VERSION ""

NS_ :

BS_:

BU_: ABS_BASE ATCM_DMSM GENERIC_GWMWakeup PBM IPMB TCU_TBS FDSM GSM TRCM GWM _delete ABS_ESC HUD IPMA CCM SASM PSCM SCCM HCM ATCM SUMA_RLM ATCM_FFSM PCU SECM VDM TBM OCS GENERIC TCCM TSTR RCM

BO_ 139 CruiseCtrl_Steering_Data: 8 SASM
 SG_ ActvFrontSteMsgTxt_D_Rq : 31|3@0+ (1,0) [0|7] "SED"  GWM
 SG_ ActvFrontSteLck_D_Stat : 17|2@0+ (1,0) [0|3] "SED"  GWM
 SG_ SelDrvMdeAdptSte_D_Stat : 28|2@0+ (1,0) [0|3] "SED"  ABS_BASE,ABS_ESC
 SG_ AslButtnOnOffPress2 : 4|1@0+ (1,0) [0|1] "SED"  SCCM
 SG_ AslButtnOnOffCnclPres2 : 5|1@0+ (1,0) [0|1] "SED"  SCCM
 SG_ CcButtnOnPress2 : 18|1@0+ (1,0) [0|1] "SED"  SCCM
 SG_ CcButtnOnOffPress2 : 19|1@0+ (1,0) [0|1] "SED"  SCCM
 SG_ CcButtnOnOffCnclPress2 : 20|1@0+ (1,0) [0|1] "SED"  SCCM
 SG_ CcButtnOffPress2 : 21|1@0+ (1,0) [0|1] "SED"  SCCM
 SG_ CcAsllButtnResPress2 : 22|1@0+ (1,0) [0|1] "SED"  SCCM
 SG_ CcAslButtnSetPress2 : 23|1@0+ (1,0) [0|1] "SED"  SCCM
 SG_ CcAslButtnSetIncPress2 : 8|1@0+ (1,0) [0|1] "SED"  SCCM
 SG_ CcAslButtnSetDecPress2 : 9|1@0+ (1,0) [0|1] "SED"  SCCM
 SG_ CcAslButtnResIncPress2 : 10|1@0+ (1,0) [0|1] "SED"  SCCM
 SG_ CcAslButtnResDecPress2 : 11|1@0+ (1,0) [0|1] "SED"  SCCM
 SG_ CcAslButtnOnPress2 : 12|1@0+ (1,0) [0|1] "SED"  SCCM
 SG_ CcAslButtnOnOffCncl2 : 13|1@0+ (1,0) [0|1] "SED"  SCCM
 SG_ CcAslButtnOffCnclPres2 : 14|1@0+ (1,0) [0|1] "SED"  SCCM
 SG_ CcAslButtnIndxIncPres2 : 15|1@0+ (1,0) [0|1] "SED"  SCCM
 SG_ CcAslButtnIndxDecPres2 : 0|1@0+ (1,0) [0|1] "SED"  SCCM
 SG_ CcAslButtnDeny_B_Actl2 : 1|1@0+ (1,0) [0|1] "SED"  SCCM
 SG_ CcAslButtnCnclResPres2 : 2|1@0+ (1,0) [0|1] "SED"  SCCM
 SG_ CcAslButtnCnclPress2 : 3|1@0+ (1,0) [0|1] "SED"  SCCM
 SG_ AccButtnGapIncPress2 : 6|1@0+ (1,0) [0|1] "SED"  SCCM
 SG_ AccButtnGapDecPress2 : 7|1@0+ (1,0) [0|1] "SED"  SCCM

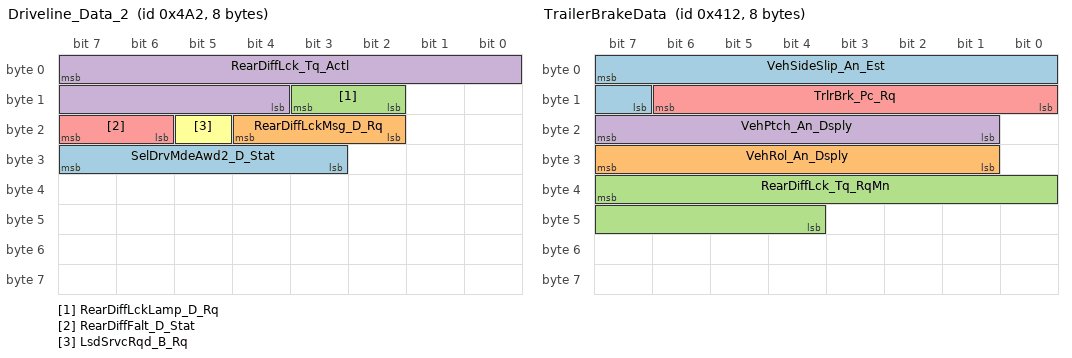
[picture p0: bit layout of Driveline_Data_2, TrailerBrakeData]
BO_ 1186 Driveline_Data_2: 8 TCCM
 SG_ SelDrvMdeAwd2_D_Stat : 31|5@0+ (1,0) [0|31] "SED"  ABS_BASE,ABS_ESC,GWM
 SG_ RearDiffLckMsg_D_Rq : 20|3@0+ (1,0) [0|7] "SED"  GWM
 SG_ RearDiffLckLamp_D_Rq : 11|2@0+ (1,0) [0|3] "SED"  IPMB,ATCM_FFSM,GWM,ATCM_DMSM
 SG_ RearDiffLck_Tq_Actl : 7|12@0+ (1,0) [0|4093] "Nm"  ABS_BASE,ABS_ESC,GWM
 SG_ RearDiffFalt_D_Stat : 23|2@0+ (1,0) [0|3] "SED"  ABS_BASE,ABS_ESC,GWM
 SG_ LsdSrvcRqd_B_Rq : 21|1@0+ (1,0) [0|1] "SED"  GWM

BO_ 1042 TrailerBrakeData: 8 ABS_ESC
 SG_ VehSideSlip_An_Est : 7|9@0+ (0.002,-0.5) [-0.5|0.518] "radians"  TCCM,GWM
 SG_ VehRol_An_Dsply : 31|7@0+ (1,-64) [-64|61] "degrees"  GWM
 SG_ RearDiffLck_Tq_RqMn : 39|12@0+ (4,0) [0|16376] "Nm"  TCCM,GWM
 SG_ VehPtch_An_Dsply : 23|7@0+ (1,-64) [-64|61] "degrees"  GWM
 SG_ TrlrBrk_Pc_Rq : 14|7@0+ (1,0) [0|127] "percent"  TBM,GWM

BO_ 138 ActiveFrontSteering_Stat2: 8 SASM
 SG_ SteWhlRelCalib_T_Actl : 7|8@0+ (1,0) [0|255] "ms"  ABS_BASE,ABS_ESC
 SG_ SteWhlRelCalib_An_Sns : 15|15@0+ (0.1,-1600) [-1600|1676.5] "deg"  PSCM,RCM,TCCM

BO_ 1878 TesterPhysicalReqPBM: 8 TSTR
 SG_ TesterPhysicalReqPBM : 7|64@0+ (1,0) [0|1.84467E+019] "unitless"  PBM

BO_ 1886 TesterPhysicalResPBM: 8 PBM
 SG_ TesterPhysicalResPBM : 7|64@0+ (1,0) [0|1.84467E+019] "unitless"  TSTR

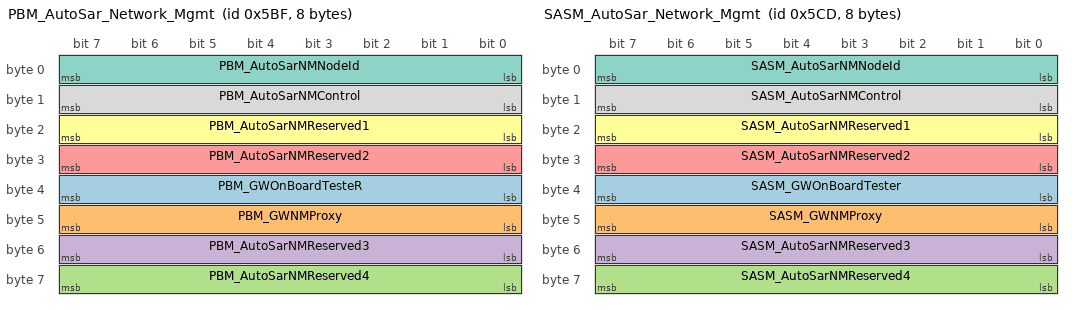
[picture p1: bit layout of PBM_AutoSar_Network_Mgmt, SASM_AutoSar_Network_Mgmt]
BO_ 1471 PBM_AutoSar_Network_Mgmt: 8 PBM
 SG_ PBM_GWOnBoardTesteR : 39|8@0+ (1,0) [0|255] "unitless"  GWM
 SG_ PBM_GWNMProxy : 47|8@0+ (1,0) [0|255] "unitless"  GWM
 SG_ PBM_AutoSarNMReserved4 : 63|8@0+ (1,0) [0|255] "unitless"  GWM
 SG_ PBM_AutoSarNMReserved3 : 55|8@0+ (1,0) [0|255] "unitless"  GWM
 SG_ PBM_AutoSarNMReserved2 : 31|8@0+ (1,0) [0|255] "unitless"  GWM
 SG_ PBM_AutoSarNMReserved1 : 23|8@0+ (1,0) [0|255] "unitless"  GWM
 SG_ PBM_AutoSarNMNodeId : 7|8@0+ (1,0) [0|255] "unitless"  GWM
 SG_ PBM_AutoSarNMControl : 15|8@0+ (1,0) [0|255] "unitless"  GWM

BO_ 1951 TesterPhysicalResSASM: 8 SASM
 SG_ TesterPhysicalResSASM : 7|64@0+ (1,0) [0|1.84467E+019] "unitless"  TSTR

BO_ 1943 TesterPhysicalReqSASM: 8 TSTR
 SG_ TesterPhysicalReqSASM : 7|64@0+ (1,0) [0|1.84467E+019] "unitless"  SASM

BO_ 1485 SASM_AutoSar_Network_Mgmt: 8 SASM
 SG_ SASM_GWOnBoardTester : 39|8@0+ (1,0) [0|255] "unitless"  GWM
 SG_ SASM_GWNMProxy : 47|8@0+ (1,0) [0|255] "unitless"  GWM
 SG_ SASM_AutoSarNMReserved4 : 63|8@0+ (1,0) [0|255] "unitless"  GWM
 SG_ SASM_AutoSarNMReserved3 : 55|8@0+ (1,0) [0|255] "unitless"  GWM
 SG_ SASM_AutoSarNMReserved2 : 31|8@0+ (1,0) [0|255] "unitless"  GWM
 SG_ SASM_AutoSarNMReserved1 : 23|8@0+ (1,0) [0|255] "unitless"  GWM
 SG_ SASM_AutoSarNMNodeId : 7|8@0+ (1,0) [0|255] "unitless"  GWM
 SG_ SASM_AutoSarNMControl : 15|8@0+ (1,0) [0|255] "unitless"  GWM

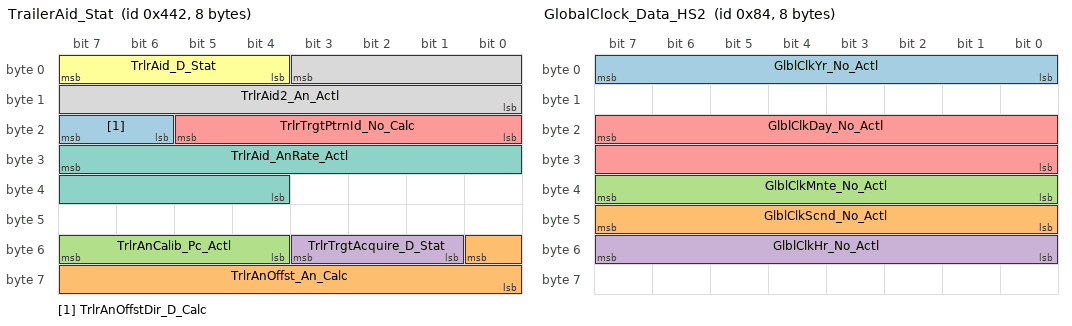
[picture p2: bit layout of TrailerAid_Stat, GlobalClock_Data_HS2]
BO_ 1090 TrailerAid_Stat: 8 IPMB
 SG_ TrlrAnOffstDir_D_Calc : 23|2@0+ (1,0) [0|3] "SED"  PSCM,GWM
 SG_ TrlrAnOffst_An_Calc : 48|9@0+ (0.1,0) [0|51.1] "degrees"  PSCM,GWM
 SG_ TrlrAnCalib_Pc_Actl : 55|4@0+ (10,0) [0|140] "percent"  PSCM,GWM
 SG_ TrlrTrgtAcquire_D_Stat : 51|3@0+ (1,0) [0|7] "SED"  PSCM,GWM
 SG_ TrlrTrgtPtrnId_No_Calc : 21|6@0+ (1,0) [0|63] "unitless"  GWM
 SG_ TrlrAid_D_Stat : 7|4@0+ (1,0) [0|15] "SED"  PSCM
 SG_ TrlrAid_AnRate_Actl : 31|12@0+ (0.1,-50) [-50|359.4] "degrees/sec"  PSCM
 SG_ TrlrAid2_An_Actl : 3|12@0+ (0.1,-90) [-90|319.4] "degrees"  PSCM

BO_ 1977 TesterPhysicalResIPMB: 8 IPMB
 SG_ TesterPhysicalResIPMB : 7|64@0+ (1,0) [0|1.84467E+019] "unitless"  TSTR

BO_ 1969 TesterPhysicalReqIPMB: 8 TSTR
 SG_ TesterPhysicalReqIPMB : 7|64@0+ (1,0) [0|1.84467E+019] "unitless"  IPMB

BO_ 132 GlobalClock_Data_HS2: 8 GWM
 SG_ GlblClkYr_No_Actl : 7|8@0+ (1,2000) [2000|2255] "year"  FDSM,TCU_TBS
 SG_ GlblClkScnd_No_Actl : 47|8@0+ (1,0) [0|255] "second"  FDSM,TCU_TBS
 SG_ GlblClkMnte_No_Actl : 39|8@0+ (1,0) [0|255] "minute"  FDSM,TCU_TBS
 SG_ GlblClkHr_No_Actl : 55|8@0+ (1,0) [0|255] "hour"  FDSM,TCU_TBS
 SG_ GlblClkDay_No_Actl : 23|16@0+ (1,0) [0|65535] "julian day"  FDSM,TCU_TBS

BO_ 73 Global_PATS_SubTarget: 8 ABS_ESC
 SG_ immoSubTarget1Data_T1 : 15|40@0+ (1,0) [0|1099511627775] "Encrypted"  GWM
 SG_ immoSubTarget1Cmd_T1 : 7|3@0+ (1,0) [0|7] "SED"  GWM

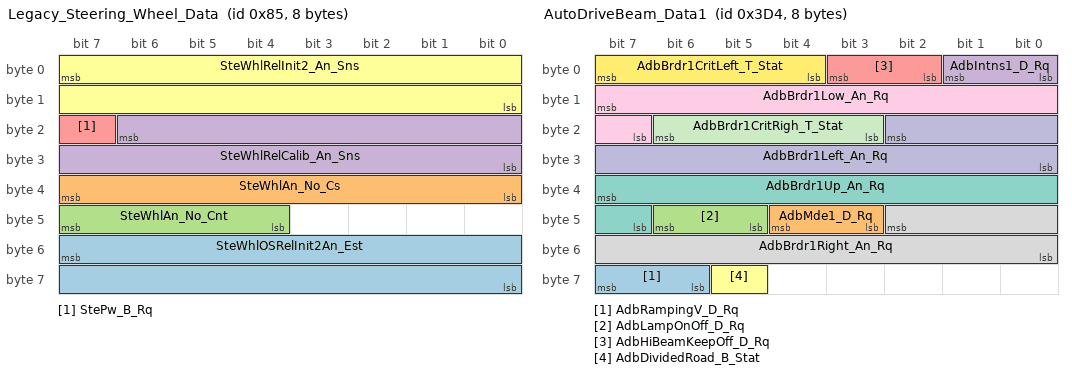
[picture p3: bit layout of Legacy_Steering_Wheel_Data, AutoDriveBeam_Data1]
BO_ 133 Legacy_Steering_Wheel_Data: 8 GENERIC
 SG_ SteWhlOSRelInit2An_Est : 55|16@0+ (0.1,-3200) [-3200|3353.3] "deg"  GENERIC
 SG_ SteWhlAn_No_Cs : 39|8@0+ (1,0) [0|255] "Unitless"  GENERIC
 SG_ SteWhlAn_No_Cnt : 47|4@0+ (1,0) [0|15] "Counts"  GENERIC
 SG_ SteWhlRelCalib_An_Sns : 22|15@0+ (0.1,-1600) [-1600|1676.5] "deg"  GENERIC
 SG_ StePw_B_Rq : 23|1@0+ (1,0) [0|1] "SED"  GENERIC
 SG_ SteWhlRelInit2_An_Sns : 7|16@0+ (0.1,-3200) [-3200|3353.3] "degrees"  IPMA,GENERIC

BO_ 980 AutoDriveBeam_Data1: 8 IPMA
 SG_ AdbRampingV_D_Rq : 63|2@0+ (1,0) [0|3] "SED"  HCM
 SG_ AdbMde1_D_Rq : 44|2@0+ (1,0) [0|3] "SED"  HCM
 SG_ AdbLampOnOff_D_Rq : 46|2@0+ (1,0) [0|3] "SED"  HCM
 SG_ AdbIntns1_D_Rq : 1|2@0+ (1,0) [0|3] "SED"  HCM
 SG_ AdbHiBeamKeepOff_D_Rq : 3|2@0+ (1,0) [0|3] "SED"  HCM
 SG_ AdbDividedRoad_B_Stat : 61|1@0+ (1,0) [0|1] "SED"  HCM
 SG_ AdbBrdr1Up_An_Rq : 39|9@0+ (0.02,-8) [-8|2.18] "degrees"  HCM
 SG_ AdbBrdr1Right_An_Rq : 42|11@0+ (0.02,-20) [-20|20.9] "degrees"  HCM
 SG_ AdbBrdr1Low_An_Rq : 15|9@0+ (0.02,-8) [-8|2.18] "degrees"  HCM
 SG_ AdbBrdr1Left_An_Rq : 18|11@0+ (0.02,-20) [-20|20.9] "degrees"  HCM
 SG_ AdbBrdr1CritRigh_T_Stat : 22|4@0+ (100,0) [0|1500] "millisecond"  HCM
 SG_ AdbBrdr1CritLeft_T_Stat : 7|4@0+ (100,0) [0|1500] "millisecond"  HCM

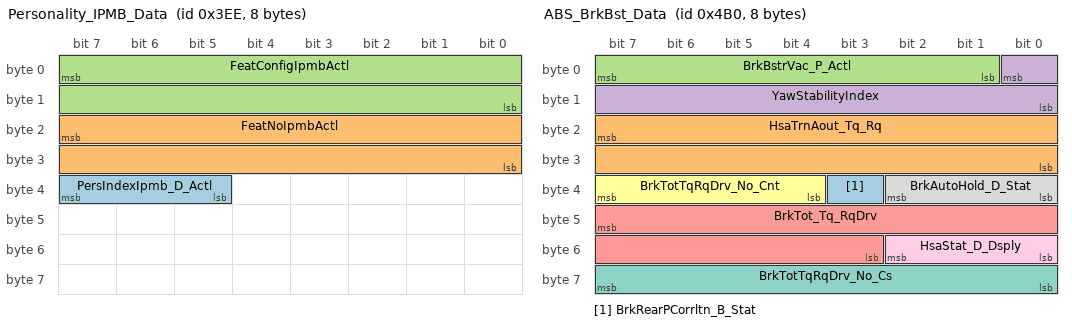
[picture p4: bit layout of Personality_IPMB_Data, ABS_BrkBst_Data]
BO_ 1006 Personality_IPMB_Data: 8 IPMB
 SG_ PersIndexIpmb_D_Actl : 39|3@0+ (1,0) [0|7] "SED"  GWM
 SG_ FeatNoIpmbActl : 23|16@0+ (1,0) [0|65535] "Number"  GWM
 SG_ FeatConfigIpmbActl : 7|16@0+ (1,0) [0|65535] "Undefined"  GWM

BO_ 1200 ABS_BrkBst_Data: 8 ABS_ESC
 SG_ BrkRearPCorrltn_B_Stat : 35|1@0+ (1,0) [0|1] "SED"  PBM,GWM
 SG_ HsaTrnAout_Tq_Rq : 23|16@0+ (4,-131072) [-131072|131060] "Nm"  GWM
 SG_ BrkBstrVac_P_Actl : 7|7@0+ (8,0) [0|1008] "Millibar"  GWM
 SG_ YawStabilityIndex : 0|9@0+ (1,-256) [-256|255] "%"  IPMA,SASM,GWM,PSCM,VDM
 SG_ BrkTot_Tq_RqDrv : 47|13@0+ (4,0) [0|32760] "Nm"  PBM,IPMA,CCM,GWM
 SG_ BrkTotTqRqDrv_No_Cnt : 39|4@0+ (1,0) [0|15] "unitless"  PBM,GWM
 SG_ BrkTotTqRqDrv_No_Cs : 63|8@0+ (1,0) [0|255] "unitless"  PBM,GWM
 SG_ BrkAutoHold_D_Stat : 34|3@0+ (1,0) [0|7] "SED"  GWM
 SG_ HsaStat_D_Dsply : 50|3@0+ (1,0) [0|7] "SED"  GWM

BO_ 989 Personality_HCM_HS2_Data: 8 HCM
 SG_ FeatNoHcm_No_Actl : 23|16@0+ (1,0) [0|65535] "Number"  GWM
 SG_ FeatConfigHcmActl : 7|16@0+ (1,0) [0|65535] "Undefined"  GWM

BO_ 1852 TesterPhysicalResHCM_HS2: 8 HCM
 SG_ TesterPhysicalResHCM : 7|64@0+ (1,0) [0|1.84467E+019] "unitless"  TSTR

BO_ 1844 TesterPhysicalReqHCM_HS2: 8 TSTR
 SG_ TesterPhysicalReqHCM : 7|64@0+ (1,0) [0|1.84467E+019] "unitless"  HCM

BO_ 945 Body_Info_7_HS2: 8 GWM
 SG_ KeyOffMde_D_Actl : 7|4@0+ (1,0) [0|15] "SED"  VDM

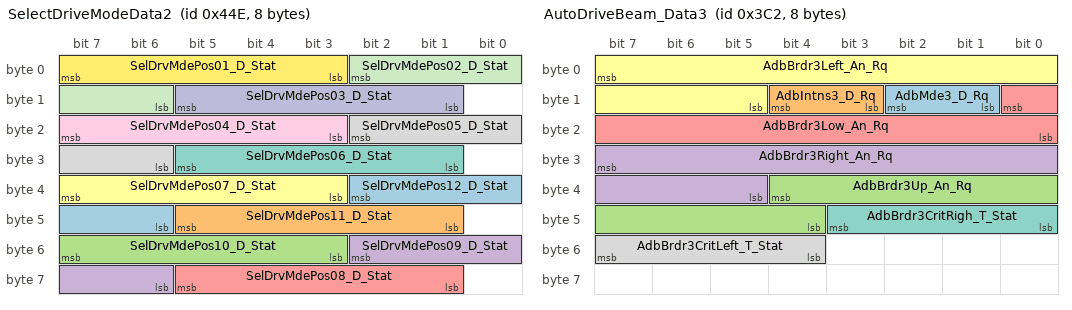
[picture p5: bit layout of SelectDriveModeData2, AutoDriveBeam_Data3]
BO_ 1102 SelectDriveModeData2: 8 ABS_ESC
 SG_ SelDrvMdePos12_D_Stat : 34|5@0+ (1,0) [0|31] "SED"  GWM
 SG_ SelDrvMdePos11_D_Stat : 45|5@0+ (1,0) [0|31] "SED"  GWM
 SG_ SelDrvMdePos10_D_Stat : 55|5@0+ (1,0) [0|31] "SED"  GWM
 SG_ SelDrvMdePos09_D_Stat : 50|5@0+ (1,0) [0|31] "SED"  GWM
 SG_ SelDrvMdePos08_D_Stat : 61|5@0+ (1,0) [0|31] "SED"  GWM
 SG_ SelDrvMdePos07_D_Stat : 39|5@0+ (1,0) [0|31] "SED"  GWM
 SG_ SelDrvMdePos06_D_Stat : 29|5@0+ (1,0) [0|31] "SED"  GWM
 SG_ SelDrvMdePos05_D_Stat : 18|5@0+ (1,0) [0|31] "SED"  GWM
 SG_ SelDrvMdePos04_D_Stat : 23|5@0+ (1,0) [0|31] "SED"  GWM
 SG_ SelDrvMdePos03_D_Stat : 13|5@0+ (1,0) [0|31] "SED"  GWM
 SG_ SelDrvMdePos02_D_Stat : 2|5@0+ (1,0) [0|31] "SED"  GWM
 SG_ SelDrvMdePos01_D_Stat : 7|5@0+ (1,0) [0|31] "SED"  GWM

BO_ 962 AutoDriveBeam_Data3: 8 IPMA
 SG_ AdbMde3_D_Rq : 10|2@0+ (1,0) [0|3] "SED"  HCM
 SG_ AdbIntns3_D_Rq : 12|2@0+ (1,0) [0|3] "SED"  HCM
 SG_ AdbBrdr3Up_An_Rq : 36|9@0+ (0.02,-8) [-8|2.18] "degrees"  HCM
 SG_ AdbBrdr3Right_An_Rq : 31|11@0+ (0.02,-20) [-20|20.9] "degrees"  HCM
 SG_ AdbBrdr3Low_An_Rq : 8|9@0+ (0.02,-8) [-8|2.18] "degrees"  HCM
 SG_ AdbBrdr3Left_An_Rq : 7|11@0+ (0.02,-20) [-20|20.9] "degrees"  HCM
 SG_ AdbBrdr3CritRigh_T_Stat : 43|4@0+ (100,0) [0|1500] "millisecond"  HCM
 SG_ AdbBrdr3CritLeft_T_Stat : 55|4@0+ (100,0) [0|1500] "millisecond"  HCM

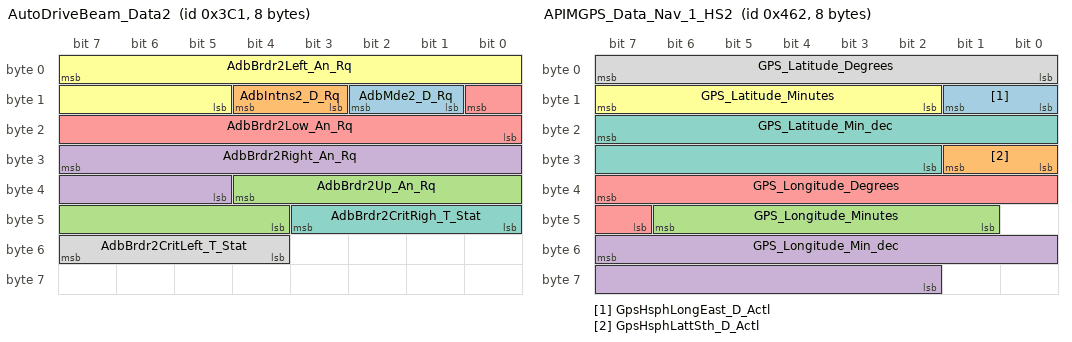
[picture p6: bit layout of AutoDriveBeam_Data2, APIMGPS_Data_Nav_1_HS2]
BO_ 961 AutoDriveBeam_Data2: 8 IPMA
 SG_ AdbMde2_D_Rq : 10|2@0+ (1,0) [0|3] "SED"  HCM
 SG_ AdbIntns2_D_Rq : 12|2@0+ (1,0) [0|3] "SED"  HCM
 SG_ AdbBrdr2Up_An_Rq : 36|9@0+ (0.02,-8) [-8|2.18] "degrees"  HCM
 SG_ AdbBrdr2Right_An_Rq : 31|11@0+ (0.02,-20) [-20|20.9] "degrees"  HCM
 SG_ AdbBrdr2Low_An_Rq : 8|9@0+ (0.02,-8) [-8|2.18] "degrees"  HCM
 SG_ AdbBrdr2Left_An_Rq : 7|11@0+ (0.02,-20) [-20|20.9] "degrees"  HCM
 SG_ AdbBrdr2CritRigh_T_Stat : 43|4@0+ (100,0) [0|1500] "millisecond"  HCM
 SG_ AdbBrdr2CritLeft_T_Stat : 55|4@0+ (100,0) [0|1500] "millisecond"  HCM

BO_ 1122 APIMGPS_Data_Nav_1_HS2: 8 GWM
 SG_ GpsHsphLongEast_D_Actl : 9|2@0+ (1,0) [0|3] "SED"  GENERIC
 SG_ GpsHsphLattSth_D_Actl : 25|2@0+ (1,0) [0|3] "SED"  GENERIC
 SG_ GPS_Longitude_Minutes : 46|6@0+ (1,0) [0|61] "Minutes"  IPMA
 SG_ GPS_Longitude_Min_dec : 55|14@0+ (0.0001,0) [0|1.6381] "Minutes"  IPMA
 SG_ GPS_Longitude_Degrees : 39|9@0+ (1,-179) [-179|330] "Degrees"  IPMA
 SG_ GPS_Latitude_Minutes : 15|6@0+ (1,0) [0|61] "Minutes"  IPMA
 SG_ GPS_Latitude_Min_dec : 23|14@0+ (0.0001,0) [0|1.6381] "Minutes"  IPMA
 SG_ GPS_Latitude_Degrees : 7|8@0+ (1,-89) [-89|164] "Degrees"  IPMA

BO_ 1080 GatewayData3_HS2: 8 GWM
 SG_ AutoTowActv_B_Stat_UB : 50|1@0+ (1,0) [0|1] "SED"  IPMA
 SG_ AutoTowActv_B_Stat : 51|1@0+ (1,0) [0|1] "SED"  IPMA
 SG_ DrLatchLckRr_B_Stat_UB : 44|1@0+ (1,0) [0|1] "SED"  GSM
 SG_ DrLatchLckRl_B_Stat_UB : 46|1@0+ (1,0) [0|1] "SED"  GSM
 SG_ DrLatchLckFr_B_Stat_UB : 32|1@0+ (1,0) [0|1] "SED"  GSM
 SG_ DrLatchLckFl_B_Stat_UB : 34|1@0+ (1,0) [0|1] "SED"  GSM
 SG_ DrLatchRr_B_Falt_UB : 40|1@0+ (1,0) [0|1] "SED"  GSM
 SG_ DrLatchRl_B_Falt_UB : 42|1@0+ (1,0) [0|1] "SED"  GSM
 SG_ DrLatchFr_B_Falt_UB : 36|1@0+ (1,0) [0|1] "SED"  GSM
 SG_ DrLatchFl_B_Falt_UB : 38|1@0+ (1,0) [0|1] "SED"  GSM
 SG_ DrLatchCntRr_No_Actl_UB : 24|1@0+ (1,0) [0|1] "SED"  GSM
 SG_ DrLatchCntRl_No_Actl_UB : 25|1@0+ (1,0) [0|1] "SED"  GSM
 SG_ DrLatchCntFr_No_Actl_UB : 26|1@0+ (1,0) [0|1] "SED"  GSM
 SG_ DrLatchCntFl_No_Actl_UB : 27|1@0+ (1,0) [0|1] "SED"  GSM
 SG_ DrLatchRr_B_Falt : 41|1@0+ (1,0) [0|1] "SED"  GSM
 SG_ DrLatchRl_B_Falt : 43|1@0+ (1,0) [0|1] "SED"  GSM
 SG_ DrLatchLckRr_B_Stat : 45|1@0+ (1,0) [0|1] "SED"  GSM
 SG_ DrLatchLckRl_B_Stat : 47|1@0+ (1,0) [0|1] "SED"  GSM
 SG_ DrLatchLckFr_B_Stat : 33|1@0+ (1,0) [0|1] "SED"  GSM
 SG_ DrLatchLckFl_B_Stat : 35|1@0+ (1,0) [0|1] "SED"  GSM
 SG_ DrLatchFr_B_Falt : 37|1@0+ (1,0) [0|1] "SED"  GSM
 SG_ DrLatchFl_B_Falt : 39|1@0+ (1,0) [0|1] "SED"  GSM
 SG_ DrLatchCntRr_No_Actl : 31|4@0+ (1,0) [0|15] "unitless"  GSM
 SG_ DrLatchCntRl_No_Actl : 19|4@0+ (1,0) [0|15] "unitless"  GSM
 SG_ DrLatchCntFr_No_Actl : 23|4@0+ (1,0) [0|15] "unitless"  GSM
 SG_ DrLatchCntFl_No_Actl : 55|4@0+ (1,0) [0|15] "unitless"  GSM
 SG_ TurnLghtSwtch_D_Stat2_UB : 1|1@0+ (1,0) [0|1] "SED"  PSCM
 SG_ TurnLghtSwtch_D_Stat2 : 3|2@0+ (1,0) [0|3] "SED"  PSCM
 SG_ CabnAmb_Te_Actl_UB : 4|1@0+ (1,0) [0|1] "SED"  SCCM
 SG_ CabnAmb_Te_Actl : 15|8@0+ (0.5,-57) [-57|70] "degreesC"  SCCM
 SG_ HeadLghtHiPrmsn_D_Stat_UB : 5|1@0+ (1,0) [0|1] "SED"  HCM,IPMA,SCCM
 SG_ HeadLghtHiPrmsn_D_Stat : 7|2@0+ (1,0) [0|3] "SED"  HCM,IPMA,SCCM

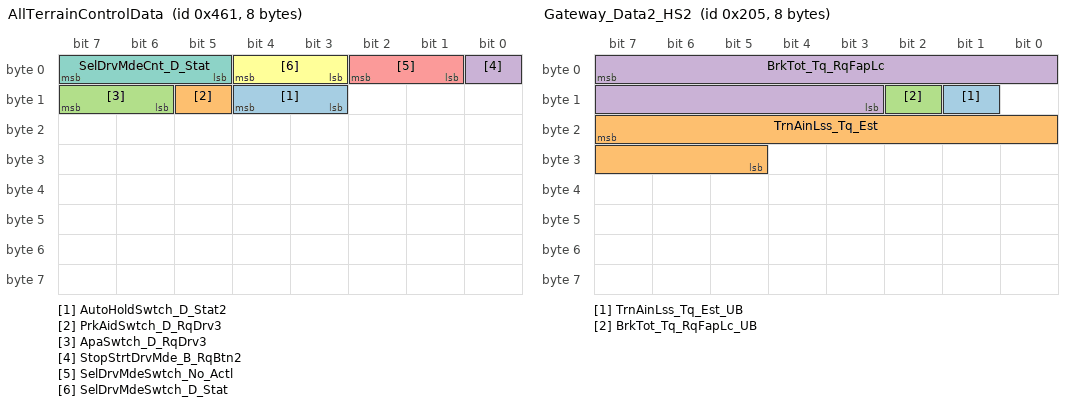
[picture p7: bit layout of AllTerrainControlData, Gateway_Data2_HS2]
BO_ 1121 AllTerrainControlData: 8 ATCM_DMSM
 SG_ AutoHoldSwtch_D_Stat2 : 12|2@0+ (1,0) [0|3] "SED"  ABS_ESC,ABS_BASE
 SG_ PrkAidSwtch_D_RqDrv3 : 13|1@0+ (1,0) [0|1] "SED"  GWM
 SG_ ApaSwtch_D_RqDrv3 : 15|2@0+ (1,0) [0|3] "SED"  GWM
 SG_ StopStrtDrvMde_B_RqBtn2 : 0|1@0+ (1,0) [0|1] "SED"  GWM
 SG_ SelDrvMdeSwtch_No_Actl : 2|2@0+ (1,0) [0|3] "unitless"  ABS_BASE,ABS_ESC
 SG_ SelDrvMdeSwtch_D_Stat : 4|2@0+ (1,0) [0|3] "SED"  ABS_BASE,ABS_ESC
 SG_ SelDrvMdeCnt_D_Stat : 7|3@0+ (1,0) [0|7] "Counts"  ABS_BASE,ABS_ESC

BO_ 517 Gateway_Data2_HS2: 8 GWM
 SG_ TrnAinLss_Tq_Est_UB : 9|1@0+ (1,0) [0|1] "SED"  ABS_ESC,ABS_BASE
 SG_ TrnAinLss_Tq_Est : 23|11@0+ (1,-500) [-500|1545] "Nm"  ABS_ESC,ABS_BASE
 SG_ BrkTot_Tq_RqFapLc_UB : 10|1@0+ (1,0) [0|1] "SED"  ABS_BASE,ABS_ESC
 SG_ BrkTot_Tq_RqFapLc : 7|13@0+ (4,0) [0|32764] "Nm"  ABS_BASE,ABS_ESC

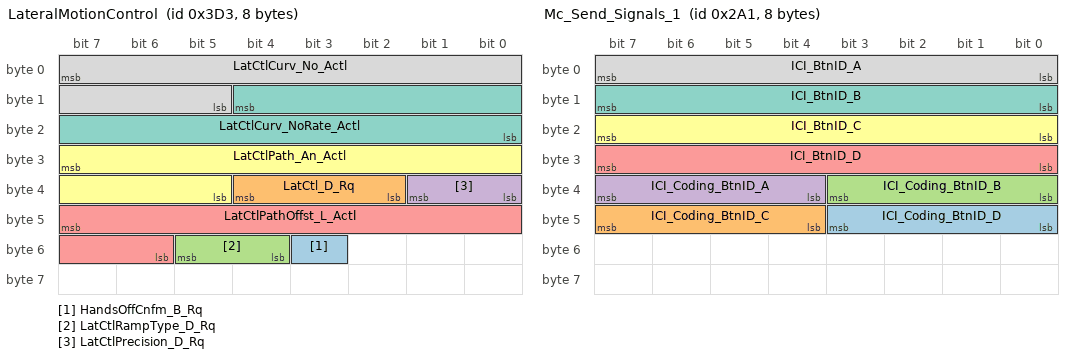
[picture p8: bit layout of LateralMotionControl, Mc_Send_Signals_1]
BO_ 979 LateralMotionControl: 8 IPMA
 SG_ HandsOffCnfm_B_Rq : 51|1@0+ (1,0) [0|1] "SED"  PSCM
 SG_ LatCtl_D_Rq : 36|3@0+ (1,0) [0|7] "SED"  PSCM
 SG_ LatCtlRampType_D_Rq : 53|2@0+ (1,0) [0|3] "SED"  PSCM
 SG_ LatCtlPrecision_D_Rq : 33|2@0+ (1,0) [0|3] "SED"  PSCM
 SG_ LatCtlPathOffst_L_Actl : 47|10@0+ (0.01,-5.12) [-5.12|5.11] "meter"  PSCM
 SG_ LatCtlPath_An_Actl : 31|11@0+ (0.0005,-0.5) [-0.5|0.5235] "radians"  PSCM
 SG_ LatCtlCurv_NoRate_Actl : 12|13@0+ (2.5E-007,-0.001024) [-0.001024|0.00102375] "1/meter"  PSCM
 SG_ LatCtlCurv_No_Actl : 7|11@0+ (2E-005,-0.02) [-0.02|0.02094] "1/meter"  PSCM

BO_ 1056 SelectDriveModeData: 8 ABS_ESC
 SG_ SelDrvMdePos12_B_Avail : 54|1@0+ (1,0) [0|1] "SED"  GWM
 SG_ SelDrvMdePos11_B_Avail : 55|1@0+ (1,0) [0|1] "SED"  GWM
 SG_ SelDrvMdePos10_B_Avail : 40|1@0+ (1,0) [0|1] "SED"  GWM
 SG_ SelDrvMdePos09_B_Avail : 41|1@0+ (1,0) [0|1] "SED"  GWM
 SG_ SelDrvMdePos08_B_Avail : 42|1@0+ (1,0) [0|1] "SED"  GWM
 SG_ SelDrvMdePos07_B_Avail : 43|1@0+ (1,0) [0|1] "SED"  GWM
 SG_ SelDrvMdePos06_B_Avail : 44|1@0+ (1,0) [0|1] "SED"  GWM
 SG_ SelDrvMdePos05_B_Avail : 45|1@0+ (1,0) [0|1] "SED"  GWM
 SG_ SelDrvMdePos04_B_Avail : 46|1@0+ (1,0) [0|1] "SED"  GWM
 SG_ SelDrvMdePos03_B_Avail : 47|1@0+ (1,0) [0|1] "SED"  GWM
 SG_ SelDrvMdePos02_B_Avail : 32|1@0+ (1,0) [0|1] "SED"  GWM
 SG_ SelDrvMdePos01_B_Avail : 24|1@0+ (1,0) [0|1] "SED"  GWM
 SG_ ActvDrvMde_D2_Stat : 53|5@0+ (1,0) [0|31] "SED"  IPMA,GWM
 SG_ SelDrvMde_D2_Rq : 63|5@0+ (1,0) [0|31] "SED"  GWM
 SG_ ActvDrvMde_D_Stat : 39|4@0+ (1,0) [0|15] "SED"  ATCM_DMSM,GWM
 SG_ SelDrvMdePt_D_Rq : 31|5@0+ (1,0) [0|31] "SED"  TCCM,GWM
 SG_ SelDrvMdeMsgTxt_D_Rq : 19|4@0+ (1,0) [0|0] "SED"  GWM
 SG_ SelDrvMde_D_Stat : 26|2@0+ (1,0) [0|3] "SED"  GWM
 SG_ SelDrvMde_D_Rq : 23|4@0+ (1,0) [0|15] "SED"  ATCM_DMSM,GWM
 SG_ SelDrvMde16_B_Avail : 8|1@0+ (1,0) [0|1] "SED"  GWM
 SG_ SelDrvMde15_B_Avail : 9|1@0+ (1,0) [0|1] "SED"  GWM
 SG_ SelDrvMde14_B_Avail : 10|1@0+ (1,0) [0|1] "SED"  GWM
 SG_ SelDrvMde13_B_Avail : 11|1@0+ (1,0) [0|1] "SED"  GWM
 SG_ SelDrvMde12_B_Avail : 12|1@0+ (1,0) [0|1] "SED"  GWM
 SG_ SelDrvMde11_B_Avail : 13|1@0+ (1,0) [0|1] "SED"  GWM
 SG_ SelDrvMde10_B_Avail : 14|1@0+ (1,0) [0|1] "SED"  GWM
 SG_ SelDrvMde09_B_Avail : 15|1@0+ (1,0) [0|1] "SED"  GWM
 SG_ SelDrvMde08_B_Avail : 0|1@0+ (1,0) [0|1] "SED"  GWM
 SG_ SelDrvMde07_B_Avail : 1|1@0+ (1,0) [0|1] "SED"  GWM
 SG_ SelDrvMde06_B_Avail : 2|1@0+ (1,0) [0|1] "SED"  GWM
 SG_ SelDrvMde05_B_Avail : 3|1@0+ (1,0) [0|1] "SED"  GWM
 SG_ SelDrvMde04_B_Avail : 4|1@0+ (1,0) [0|1] "SED"  GWM
 SG_ SelDrvMde03_B_Avail : 5|1@0+ (1,0) [0|1] "SED"  GWM
 SG_ SelDrvMde02_B_Avail : 6|1@0+ (1,0) [0|1] "SED"  GWM
 SG_ SelDrvMde01_B_Avail : 7|1@0+ (1,0) [0|1] "SED"  GWM
 SG_ AwdMde_D_RqBrk : 35|3@0+ (1,0) [0|7] "SED"  GWM,TCCM

BO_ 1215 ElecHorizon_Data2_HS2: 8 GWM
 SG_ EhData2_No_Actl : 7|64@0+ (1,0) [0|1.844674407371E+019] "unitless"  IPMA

BO_ 1214 ElecHorizon_Data1_HS2: 8 GWM
 SG_ EhData1_No_Actl : 7|64@0+ (1,0) [0|1.844674407371E+019] "unitless"  IPMA

BO_ 673 Mc_Send_Signals_1: 8 SCCM
 SG_ ICI_Coding_BtnID_D : 43|4@0+ (1,0) [0|15] "SED"  GWM
 SG_ ICI_Coding_BtnID_C : 47|4@0+ (1,0) [0|15] "SED"  GWM
 SG_ ICI_Coding_BtnID_B : 35|4@0+ (1,0) [0|15] "SED"  GWM
 SG_ ICI_Coding_BtnID_A : 39|4@0+ (1,0) [0|15] "SED"  GWM
 SG_ ICI_BtnID_D : 31|8@0+ (1,0) [0|255] "unitless"  GWM
 SG_ ICI_BtnID_C : 23|8@0+ (1,0) [0|255] "unitless"  GWM
 SG_ ICI_BtnID_B : 15|8@0+ (1,0) [0|255] "unitless"  GWM
 SG_ ICI_BtnID_A : 7|8@0+ (1,0) [0|255] "unitless"  GWM

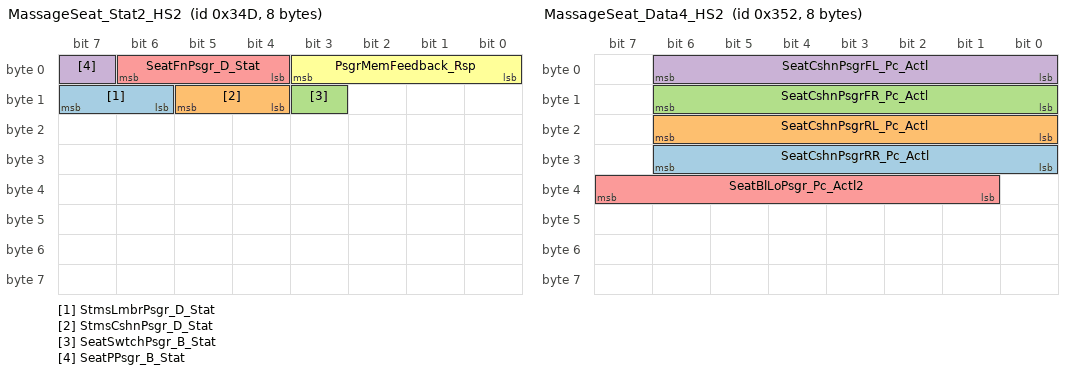
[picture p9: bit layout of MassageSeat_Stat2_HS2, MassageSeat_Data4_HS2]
BO_ 845 MassageSeat_Stat2_HS2: 8 GWM
 SG_ StmsLmbrPsgr_D_Stat : 15|2@0+ (1,0) [0|3] "SED"  OCS
 SG_ StmsCshnPsgr_D_Stat : 13|2@0+ (1,0) [0|3] "SED"  OCS
 SG_ SeatSwtchPsgr_B_Stat : 11|1@0+ (1,0) [0|1] "SED"  OCS
 SG_ SeatPPsgr_B_Stat : 7|1@0+ (1,0) [0|1] "SED"  OCS
 SG_ SeatFnPsgr_D_Stat : 6|3@0+ (1,0) [0|7] "SED"  OCS
 SG_ PsgrMemFeedback_Rsp : 3|4@0+ (1,0) [0|15] "SED"  GENERIC

BO_ 850 MassageSeat_Data4_HS2: 8 GWM
 SG_ SeatCshnPsgrRR_Pc_Actl : 30|7@0+ (1,0) [0|126] "Percent"  OCS
 SG_ SeatCshnPsgrRL_Pc_Actl : 22|7@0+ (1,0) [0|126] "Percent"  OCS
 SG_ SeatCshnPsgrFR_Pc_Actl : 14|7@0+ (1,0) [0|126] "Percent"  OCS
 SG_ SeatCshnPsgrFL_Pc_Actl : 6|7@0+ (1,0) [0|126] "Percent"  OCS
 SG_ SeatBlLoPsgr_Pc_Actl2 : 39|7@0+ (1,0) [0|126] "Percent"  OCS

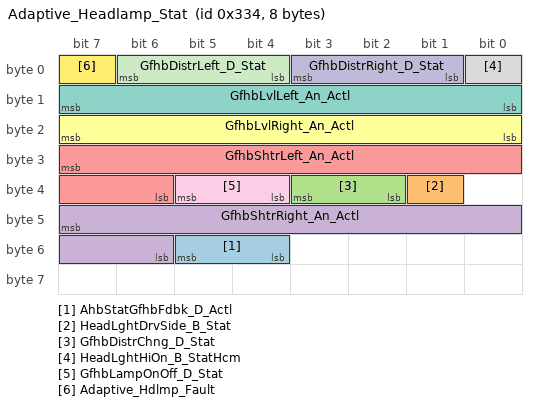
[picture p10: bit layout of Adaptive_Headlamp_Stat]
BO_ 820 Adaptive_Headlamp_Stat: 8 HCM
 SG_ AhbStatGfhbFdbk_D_Actl : 53|2@0+ (1,0) [0|3] "SED"  SCCM
 SG_ HeadLghtDrvSide_B_Stat : 33|1@0+ (1,0) [0|1] "SED"  IPMA
 SG_ GfhbDistrChng_D_Stat : 35|2@0+ (1,0) [0|3] "SED"  IPMA
 SG_ GfhbShtrRight_An_Actl : 47|10@0+ (0.04,-20) [-20|20.84] "degrees"  IPMA
 SG_ GfhbShtrLeft_An_Actl : 31|10@0+ (0.04,-20) [-20|20.84] "degrees"  IPMA
 SG_ GfhbLvlRight_An_Actl : 23|8@0+ (0.1,-12) [-12|13.3] "degrees"  IPMA
 SG_ GfhbLvlLeft_An_Actl : 15|8@0+ (0.1,-12) [-12|13.3] "degrees"  IPMA
 SG_ HeadLghtHiOn_B_StatHcm : 0|1@0+ (1,0) [0|1] "SED"  GWM,GENERIC
 SG_ GfhbLampOnOff_D_Stat : 37|2@0+ (1,0) [0|3] "SED"  IPMA
 SG_ GfhbDistrRight_D_Stat : 3|3@0+ (1,0) [0|7] "SED"  IPMA
 SG_ GfhbDistrLeft_D_Stat : 6|3@0+ (1,0) [0|7] "SED"  IPMA
 SG_ Adaptive_Hdlmp_Fault : 7|1@0+ (1,0) [0|1] "SED"  GWM,IPMA,GENERIC

BO_ 935 Side_Detect_R_Stat_HS2: 8 GWM
 SG_ CtaAlrtRight2_D_Stat : 30|3@0+ (1,0) [0|7] "SED"  GENERIC
 SG_ BttRight_D_Stat : 45|3@0+ (1,0) [0|7] "SED"  GENERIC
 SG_ BttRight_D_RqDrv : 47|2@0+ (1,0) [0|3] "SED"  GENERIC
 SG_ CtaBrkRightMsgTxt_B_Rq : 42|1@0+ (1,0) [0|1] "SED"  GENERIC
 SG_ CtaRightBrkEnbl_B_Rq : 31|1@0+ (1,0) [0|1] "SED"  ABS_BASE,ABS_ESC
 SG_ Side_Detect_R_Illum : 39|8@0+ (1,0) [0|255] "Percent"  GENERIC
 SG_ CtaSnsRight_D_Stat : 25|2@0+ (1,0) [0|3] "SED"  GENERIC
 SG_ CtaAlrtRight_D_Stat : 8|1@0+ (1,0) [0|1] "SED"  GENERIC
 SG_ CtaRight_D_Stat : 18|3@0+ (1,0) [0|7] "SED"  GENERIC
 SG_ SodRight_D_Stat : 15|3@0+ (1,0) [0|7] "SED"  GENERIC
 SG_ SodSnsRight_D_Stat : 12|2@0+ (1,0) [0|3] "SED"  GENERIC
 SG_ SodAlrtRight_D_Stat : 10|2@0+ (1,0) [0|3] "SED"  GENERIC
 SG_ SodDetctRight_D_Stat : 23|3@0+ (1,0) [0|7] "SED"  IPMA
 SG_ SodWarnRight_Prd_Rq : 6|7@0+ (1,0) [0|127] "millisecond"  GENERIC
 SG_ SodInnrRight_D_Stat : 20|2@0+ (1,0) [0|3] "SED"  GENERIC
 SG_ CtaRightBrkDecel_B_Rq : 7|1@0+ (1,0) [0|1] "SED"  ABS_BASE,ABS_ESC
 SG_ CtaInnrRight_D_Stat : 27|2@0+ (1,0) [0|3] "SED"  GENERIC

BO_ 934 Side_Detect_L_Stat_HS2: 8 GWM
 SG_ CtaAlrtLeft2_D_Stat : 30|3@0+ (1,0) [0|7] "SED"  GENERIC
 SG_ BttLeft_D_Stat : 45|3@0+ (1,0) [0|7] "SED"  GENERIC
 SG_ BttLeft_D_RqDrv : 47|2@0+ (1,0) [0|3] "SED"  GENERIC
 SG_ CtaBrkLeftMsgTxt_B_Rq : 42|1@0+ (1,0) [0|1] "SED"  GENERIC
 SG_ CtaLeftBrkDecel_B_Rq : 7|1@0+ (1,0) [0|1] "SED"  ABS_BASE,ABS_ESC
 SG_ CtaLeftBrkEnbl_B_Rq : 31|1@0+ (1,0) [0|1] "SED"  ABS_BASE,ABS_ESC
 SG_ Side_Detect_L_Illum : 39|8@0+ (1,0) [0|255] "Percent"  GENERIC
 SG_ CtaSnsLeft_D_Stat : 25|2@0+ (1,0) [0|3] "SED"  GENERIC
 SG_ SodDetctLeft_D_Stat : 23|3@0+ (1,0) [0|7] "SED"  IPMA
 SG_ CtaLeft_D_Stat : 18|3@0+ (1,0) [0|7] "SED"  GENERIC
 SG_ CtaAlrtLeft_D_Stat : 8|1@0+ (1,0) [0|1] "SED"  GENERIC
 SG_ SodLeft_D_Stat : 15|3@0+ (1,0) [0|7] "SED"  GENERIC
 SG_ SodSnsLeft_D_Stat : 12|2@0+ (1,0) [0|3] "SED"  GENERIC
 SG_ SodAlrtLeft_D_Stat : 10|2@0+ (1,0) [0|3] "SED"  GENERIC
 SG_ SodWarnLeft_Prd_Rq : 6|7@0+ (1,0) [0|127] "millisecond"  GENERIC
 SG_ SodInnrLeft_D_Stat : 20|2@0+ (1,0) [0|3] "SED"  GENERIC
 SG_ CtaInnrLeft_D_Stat : 27|2@0+ (1,0) [0|3] "SED"  GENERIC

BO_TX_BU_ 1042 : ABS_BASE,ABS_ESC;
BO_TX_BU_ 73 : ABS_BASE,TCU_TBS,ABS_ESC;
BO_TX_BU_ 1200 : ABS_BASE,ABS_ESC;
BO_TX_BU_ 1102 : ABS_BASE,ABS_ESC;
BO_TX_BU_ 1056 : ABS_BASE,ABS_ESC;
BO_TX_BU_ 673 : SASM,SCCM;
CM_ SG_ 138 SteWhlRelCalib_An_Sns "Signal is not transmitted on vehicles where PSCM is transmitting the message that contains this signal.
Signal data set to 0x0 for ABS only vehicle option content";
CM_ BO_ 73 "Provide target function information to the control function of the Passive Anti-Theft Subsystem";
CM_ SG_ 133 SteWhlOSRelInit2An_Est "Legacy signal not supported, reserving bit location for commodity IPMA dbc file.  No valid data. ";
CM_ SG_ 133 SteWhlAn_No_Cs "Legacy signal not supported, reserving bit location for commodity IPMA dbc file.  No valid data. ";
CM_ SG_ 133 SteWhlAn_No_Cnt "Legacy signal not supported, reserving bit location for commodity IPMA dbc file.  No valid data. ";
CM_ SG_ 133 SteWhlRelCalib_An_Sns "Signal is not transmitted on vehicles where PSCM is transmitting the message that contains this signal.
Signal data set to 0x0 for ABS only vehicle option content";
CM_ SG_ 133 SteWhlRelInit2_An_Sns "Legacy signal not supported, reserving bit location for commodity IPMA dbc file.  No valid data. ";
CM_ SG_ 1200 BrkTot_Tq_RqDrv "DCR 1836 to update Tx from GWM to EP100ms rejected due MPS6 TCM requires BrkTot_Tq_RqDrv at 20ms (bshu1).";
CM_ BO_ 1122 "HS3 APIM Sync Gen3 Tx 0x462.  FrameGateway to 0x465 on HS1, HS2, HS3 and MS1.";
CM_ SG_ 1080 DrLatchCntRr_No_Actl "Rolling counts indicate fresh data (DrLatchCntxx) are updated each time new data is sent from a latch to BCM thru the GW. UBs not required.";
CM_ SG_ 1080 DrLatchCntRl_No_Actl "Rolling counts indicate fresh data (DrLatchCntxx) are updated each time new data is sent from a latch to BCM thru the GW. UBs not required.";
CM_ SG_ 1080 DrLatchCntFr_No_Actl "Rolling counts indicate fresh data (DrLatchCntxx) are updated each time new data is sent from a latch to BCM thru the GW. UBs not required.";
CM_ SG_ 1080 DrLatchCntFl_No_Actl "Rolling counts indicate fresh data (DrLatchCntxx) are updated each time new data is sent from a latch to BCM thru the GW. UBs not required.";
CM_ BO_ 673 "Do not use this Frame for other Cluster Interaction";
CM_ SG_ 673 ICI_Coding_BtnID_D "Object InputControlInterface ICI ButtonCoding_D
(Parameter2)";
CM_ SG_ 673 ICI_Coding_BtnID_C "Object InputControlInterface ICI ButtonCoding_C
(Parameter2)";
CM_ SG_ 673 ICI_Coding_BtnID_B "Object InputControlInterface ICI ButtonCoding_B
(Parameter2)";
CM_ SG_ 673 ICI_Coding_BtnID_A "Object InputControlInterface ICI ButtonCoding_A
(Parameter2)";
CM_ SG_ 673 ICI_BtnID_D "Object InputControlInterface ICI ButtonID_D
(Parameter1)
for detailed Information refer to ICI Reference document";
CM_ SG_ 673 ICI_BtnID_C "Object InputControlInterface ICI ButtonID_C
(Parameter1)
for detailed Information refer to ICI Reference document";
CM_ SG_ 673 ICI_BtnID_B "Object InputControlInterface ICI ButtonID_B
(Parameter1)
for detailed Information refer to ICI Reference document";
CM_ SG_ 673 ICI_BtnID_A "Object InputControlInterface ICI ButtonID_A
(Parameter1)
for detailed Information refer to ICI Reference document";
CM_ SG_ 935 Side_Detect_R_Illum "DDMGenSigTimeoutTime=2000";
CM_ SG_ 935 SodRight_D_Stat "IPCGenSigTimeoutTime=1600";
CM_ SG_ 935 SodSnsRight_D_Stat "IPCGenSigTimeoutTime=1600";
CM_ SG_ 935 SodAlrtRight_D_Stat "DDMGenSigTimeoutTime=2000";
CM_ SG_ 935 CtaInnrRight_D_Stat "IPCGenSigTimeoutTime=1600";
CM_ SG_ 934 Side_Detect_L_Illum "DDMGenSigTimeoutTime=2000";
CM_ SG_ 934 SodLeft_D_Stat "IPCGenSigTimeoutTime=1600";
CM_ SG_ 934 SodSnsLeft_D_Stat "IPCGenSigTimeoutTime=1600";
CM_ SG_ 934 SodAlrtLeft_D_Stat "DDMGenSigTimeoutTime=2000";
CM_ SG_ 934 CtaInnrLeft_D_Stat "IPCGenSigTimeoutTime=1600";
BA_DEF_ SG_  "GenSigTimeoutTime_GWM" INT 0 100000;
BA_DEF_ BO_  "FrameGatewayNetwork" STRING ;
BA_DEF_ BO_  "FrameGatewayMS1" HEX 0 1407;
BA_DEF_ BO_  "FrameGatewayHS3" HEX 0 1407;
BA_DEF_ BO_  "FrameGatewayHS1" HEX 0 1407;
BA_DEF_ BO_  "NetworkInitialization" ENUM  "No","Yes";
BA_DEF_ BO_  "FrameGatewayId" HEX 0 1407;
BA_DEF_ BO_  "EventRateOfChange" INT 10 10000;
BA_DEF_ BO_  "GenMsgStartDelayTime" INT 0 10000;
BA_DEF_ BO_  "GenMsgNrOfRepetition" INT 0 100;
BA_DEF_ BO_  "GenMsgDelayTime" INT 0 1000;
BA_DEF_ BO_  "GenMsgCycleTime" INT 0 100000;
BA_DEF_ BO_  "GenMsgSendType" ENUM  "FixedPeriodic","Event","EnabledPeriodic","NotUsed","NotUsed","EventPeriodic","NotUsed","NotUsed","NoMsgSendType";
BA_DEF_ SG_  "U_U611_U625_MY20_Phev_Tx" ENUM  "No","Yes";
BA_DEF_ SG_  "U_CX482_CX483_MY20_Hev_Tx" ENUM  "No","Yes";
BA_DEF_ SG_  "U_CX482_CX483_MY20_Gas_Tx" ENUM  "No","Yes";
BA_DEF_ SG_  "U_CX482_CX483_MY20_Diesel_Tx" ENUM  "No","Yes";
BA_DEF_ SG_  "U_U611_U625_MY20_Hev_Tx" ENUM  "No","Yes";
BA_DEF_ SG_  "U_U611_U625_MY20_Gas_Tx" ENUM  "No","Yes";
BA_DEF_ SG_  "U_U611_U625_MY20_Diesel_Tx" ENUM  "No","Yes";
BA_DEF_ SG_  "U_LC1_B500_MY18_Gas_Tx" ENUM  "No","Yes";
BA_DEF_ SG_  "U_LC1_B500_MY18_Diesel_Tx" ENUM  "No","Yes";
BA_DEF_ SG_  "U_B500_MY18_Diesel_Tx" ENUM  "No","Yes";
BA_DEF_ SG_  "U_B500_MY18_Gas_Tx" ENUM  "No","Yes";
BA_DEF_ SG_  "U_C490_MY18_Tx" ENUM  "No","Yes";
BA_DEF_ SG_  "U_B562_MY18_Gas_Tx" ENUM  "No","Yes";
BA_DEF_ SG_  "U_C519_MY18_5_Gas_Tx" ENUM  "No","Yes";
BA_DEF_ SG_  "U_C519_MY18_5_Diesel_Tx" ENUM  "No","Yes";
BA_DEF_ SG_  "U_B515_MCA_MY17_Gas_Tx" ENUM  "No","Yes";
BA_DEF_ SG_  "U_B515_MCA_MY17_Diesel_Tx" ENUM  "No","Yes";
BA_DEF_ SG_  "U_B479_MY17_Diesel_Tx" ENUM  "No","Yes";
BA_DEF_ SG_  "U_B479_MY17_Gas_Tx" ENUM  "No","Yes";
BA_DEF_ SG_  "U_B562LC_MY15_Gas_Tx" ENUM  "No","Yes";
BA_DEF_ SG_  "U_B562LC_MY15_Diesel_Tx" ENUM  "No","Yes";
BA_DEF_ SG_  "U_U611_U625_MY20_Phev_Rx" ENUM  "No","Yes";
BA_DEF_ SG_  "U_CX482_CX483_MY20_Hev_Rx" ENUM  "No","Yes";
BA_DEF_ SG_  "U_CX482_CX483_MY20_Gas_Rx" ENUM  "No","Yes";
BA_DEF_ SG_  "U_CX482_CX483_MY20_Diesel_Rx" ENUM  "No","Yes";
BA_DEF_ SG_  "U_U611_U625_MY20_Hev_Rx" ENUM  "No","Yes";
BA_DEF_ SG_  "U_U611_U625_MY20_Gas_Rx" ENUM  "No","Yes";
BA_DEF_ SG_  "U_U611_U625_MY20_Diesel_Rx" ENUM  "No","Yes";
BA_DEF_ SG_  "U_B500_MY18_Diesel_Rx" ENUM  "No","Yes";
BA_DEF_ SG_  "U_B500_MY18_Gas_Rx" ENUM  "No","Yes";
BA_DEF_ SG_  "U_C490_MY18_Rx" ENUM  "No","Yes";
BA_DEF_ SG_  "U_B562_MY18_Gas_Rx" ENUM  "No","Yes";
BA_DEF_ SG_  "U_C519_MY18_5_Gas_Rx" ENUM  "No","Yes";
BA_DEF_ SG_  "U_C519_MY18_5_Diesel_Rx" ENUM  "No","Yes";
BA_DEF_ SG_  "U_B515_MCA_MY17_Gas_Rx" ENUM  "No","Yes";
BA_DEF_ SG_  "U_B515_MCA_MY17_Diesel_Rx" ENUM  "No","Yes";
BA_DEF_ SG_  "U_B479_MY17_Diesel_Rx" ENUM  "No","Yes";
BA_DEF_ SG_  "U_B479_MY17_Gas_Rx" ENUM  "No","Yes";
BA_DEF_ SG_  "U_B562LC_MY15_Gas_Rx" ENUM  "No","Yes";
BA_DEF_ SG_  "U_B562LC_MY15_Diesel_Rx" ENUM  "No","Yes";
BA_DEF_ SG_  "ContentDependant" ENUM  "No","Yes";
BA_DEF_ SG_  "GenSigStartValue" INT 0 1000000000;
BA_DEF_ SG_  "UsedOnPgmDBC" ENUM  "No","Yes";
BA_DEF_ SG_  "CrossOver_InfoCAN" ENUM  "No","Yes";
BA_DEF_ SG_  "WakeupSignal" ENUM  "No","Yes";
BA_DEF_ SG_  "GenSigMissingSourceValue" INT 0 1000000000;
BA_DEF_ SG_  "GenSigSendType" ENUM  "Cyclic","OnWrite","vector_leerstring","OnChange","vector_leerstring","IfActive","vector_leerstring","NoSigSendType";
BA_DEF_ BO_  "GenMsgRoutingTimeoutTime" INT 0 1000;
BA_DEF_ BO_  "MessageGateway" ENUM  "No","Yes";
BA_DEF_ BO_  "NmAsrMessage" ENUM  "No","Yes";
BA_DEF_ BO_  "TpApplType" STRING ;
BA_DEF_ BO_  "DiagState" ENUM  "No","Yes";
BA_DEF_ BO_  "DiagRequest" ENUM  "No","Yes";
BA_DEF_ BO_  "DiagResponse" ENUM  "No","Yes";
BA_DEF_ BO_  "GenMsgILSupport" ENUM  "No","Yes";
BA_DEF_DEF_  "GenSigTimeoutTime_GWM" 0;
BA_DEF_DEF_  "FrameGatewayNetwork" "NONE";
BA_DEF_DEF_  "FrameGatewayMS1" 0;
BA_DEF_DEF_  "FrameGatewayHS3" 0;
BA_DEF_DEF_  "FrameGatewayHS1" 0;
BA_DEF_DEF_  "NetworkInitialization" "Yes";
BA_DEF_DEF_  "FrameGatewayId" 0;
BA_DEF_DEF_  "EventRateOfChange" 10000;
BA_DEF_DEF_  "GenMsgStartDelayTime" 0;
BA_DEF_DEF_  "GenMsgNrOfRepetition" 1;
BA_DEF_DEF_  "GenMsgDelayTime" 20;
BA_DEF_DEF_  "GenMsgCycleTime" 0;
BA_DEF_DEF_  "GenMsgSendType" "NoMsgSendType";
BA_DEF_DEF_  "U_U611_U625_MY20_Phev_Tx" "No";
BA_DEF_DEF_  "U_CX482_CX483_MY20_Hev_Tx" "No";
BA_DEF_DEF_  "U_CX482_CX483_MY20_Gas_Tx" "No";
BA_DEF_DEF_  "U_CX482_CX483_MY20_Diesel_Tx" "No";
BA_DEF_DEF_  "U_U611_U625_MY20_Hev_Tx" "No";
BA_DEF_DEF_  "U_U611_U625_MY20_Gas_Tx" "No";
BA_DEF_DEF_  "U_U611_U625_MY20_Diesel_Tx" "No";
BA_DEF_DEF_  "U_LC1_B500_MY18_Gas_Tx" "No";
BA_DEF_DEF_  "U_LC1_B500_MY18_Diesel_Tx" "No";
BA_DEF_DEF_  "U_B500_MY18_Diesel_Tx" "No";
BA_DEF_DEF_  "U_B500_MY18_Gas_Tx" "No";
BA_DEF_DEF_  "U_C490_MY18_Tx" "No";
BA_DEF_DEF_  "U_B562_MY18_Gas_Tx" "No";
BA_DEF_DEF_  "U_C519_MY18_5_Gas_Tx" "No";
BA_DEF_DEF_  "U_C519_MY18_5_Diesel_Tx" "No";
BA_DEF_DEF_  "U_B515_MCA_MY17_Gas_Tx" "No";
BA_DEF_DEF_  "U_B515_MCA_MY17_Diesel_Tx" "No";
BA_DEF_DEF_  "U_B479_MY17_Diesel_Tx" "No";
BA_DEF_DEF_  "U_B479_MY17_Gas_Tx" "No";
BA_DEF_DEF_  "U_B562LC_MY15_Gas_Tx" "No";
BA_DEF_DEF_  "U_B562LC_MY15_Diesel_Tx" "No";
BA_DEF_DEF_  "U_U611_U625_MY20_Phev_Rx" "No";
BA_DEF_DEF_  "U_CX482_CX483_MY20_Hev_Rx" "No";
BA_DEF_DEF_  "U_CX482_CX483_MY20_Gas_Rx" "No";
BA_DEF_DEF_  "U_CX482_CX483_MY20_Diesel_Rx" "No";
BA_DEF_DEF_  "U_U611_U625_MY20_Hev_Rx" "No";
BA_DEF_DEF_  "U_U611_U625_MY20_Gas_Rx" "No";
BA_DEF_DEF_  "U_U611_U625_MY20_Diesel_Rx" "No";
BA_DEF_DEF_  "U_B500_MY18_Diesel_Rx" "No";
BA_DEF_DEF_  "U_B500_MY18_Gas_Rx" "No";
BA_DEF_DEF_  "U_C490_MY18_Rx" "No";
BA_DEF_DEF_  "U_B562_MY18_Gas_Rx" "No";
BA_DEF_DEF_  "U_C519_MY18_5_Gas_Rx" "No";
BA_DEF_DEF_  "U_C519_MY18_5_Diesel_Rx" "No";
BA_DEF_DEF_  "U_B515_MCA_MY17_Gas_Rx" "No";
BA_DEF_DEF_  "U_B515_MCA_MY17_Diesel_Rx" "No";
BA_DEF_DEF_  "U_B479_MY17_Diesel_Rx" "No";
BA_DEF_DEF_  "U_B479_MY17_Gas_Rx" "No";
BA_DEF_DEF_  "U_B562LC_MY15_Gas_Rx" "No";
BA_DEF_DEF_  "U_B562LC_MY15_Diesel_Rx" "No";
BA_DEF_DEF_  "ContentDependant" "No";
BA_DEF_DEF_  "GenSigStartValue" 0;
BA_DEF_DEF_  "UsedOnPgmDBC" "Yes";
BA_DEF_DEF_  "CrossOver_InfoCAN" "No";
BA_DEF_DEF_  "WakeupSignal" "No";
BA_DEF_DEF_  "GenSigMissingSourceValue" 0;
BA_DEF_DEF_  "GenSigSendType" "NoSigSendType";
BA_DEF_DEF_  "GenMsgRoutingTimeoutTime" 0;
BA_DEF_DEF_  "MessageGateway" "No";
BA_DEF_DEF_  "NmAsrMessage" "No";
BA_DEF_DEF_  "TpApplType" "";
BA_DEF_DEF_  "DiagState" "No";
BA_DEF_DEF_  "DiagRequest" "No";
BA_DEF_DEF_  "DiagResponse" "No";
BA_DEF_DEF_  "GenMsgILSupport" "Yes";
BA_ "GenMsgCycleTime" BO_ 139 100;
BA_ "GenMsgSendType" BO_ 139 5;
BA_ "GenMsgCycleTime" BO_ 1186 100;
BA_ "GenMsgSendType" BO_ 1186 0;
BA_ "GenMsgCycleTime" BO_ 1042 50;
BA_ "GenMsgSendType" BO_ 1042 0;
BA_ "GenMsgDelayTime" BO_ 138 0;
BA_ "GenMsgCycleTime" BO_ 138 10;
BA_ "GenMsgSendType" BO_ 138 0;
BA_ "NetworkInitialization" BO_ 1878 0;
BA_ "GenMsgDelayTime" BO_ 1878 0;
BA_ "GenMsgSendType" BO_ 1878 1;
BA_ "DiagRequest" BO_ 1878 1;
BA_ "GenMsgILSupport" BO_ 1878 0;
BA_ "NetworkInitialization" BO_ 1886 0;
BA_ "GenMsgDelayTime" BO_ 1886 0;
BA_ "GenMsgSendType" BO_ 1886 1;
BA_ "DiagResponse" BO_ 1886 1;
BA_ "GenMsgILSupport" BO_ 1886 0;
BA_ "NetworkInitialization" BO_ 1471 0;
BA_ "GenMsgCycleTime" BO_ 1471 1000;
BA_ "GenMsgSendType" BO_ 1471 0;
BA_ "NmAsrMessage" BO_ 1471 1;
BA_ "GenMsgILSupport" BO_ 1471 0;
BA_ "NetworkInitialization" BO_ 1951 0;
BA_ "GenMsgDelayTime" BO_ 1951 0;
BA_ "GenMsgSendType" BO_ 1951 1;
BA_ "DiagResponse" BO_ 1951 1;
BA_ "GenMsgILSupport" BO_ 1951 0;
BA_ "NetworkInitialization" BO_ 1943 0;
BA_ "GenMsgDelayTime" BO_ 1943 0;
BA_ "GenMsgSendType" BO_ 1943 1;
BA_ "DiagRequest" BO_ 1943 1;
BA_ "GenMsgILSupport" BO_ 1943 0;
BA_ "NetworkInitialization" BO_ 1485 0;
BA_ "GenMsgCycleTime" BO_ 1485 1000;
BA_ "GenMsgSendType" BO_ 1485 0;
BA_ "NmAsrMessage" BO_ 1485 1;
BA_ "GenMsgILSupport" BO_ 1485 0;
BA_ "GenMsgCycleTime" BO_ 1090 50;
BA_ "GenMsgSendType" BO_ 1090 0;
BA_ "NetworkInitialization" BO_ 1977 0;
BA_ "GenMsgDelayTime" BO_ 1977 0;
BA_ "GenMsgSendType" BO_ 1977 1;
BA_ "DiagResponse" BO_ 1977 1;
BA_ "GenMsgILSupport" BO_ 1977 0;
BA_ "NetworkInitialization" BO_ 1969 0;
BA_ "GenMsgDelayTime" BO_ 1969 0;
BA_ "GenMsgSendType" BO_ 1969 1;
BA_ "DiagRequest" BO_ 1969 1;
BA_ "GenMsgILSupport" BO_ 1969 0;
BA_ "FrameGatewayNetwork" BO_ 132 "HS1_CAN";
BA_ "FrameGatewayHS1" BO_ 132 132;
BA_ "FrameGatewayId" BO_ 132 132;
BA_ "GenMsgDelayTime" BO_ 73 10;
BA_ "GenMsgCycleTime" BO_ 73 20;
BA_ "GenMsgSendType" BO_ 73 0;
BA_ "GenMsgDelayTime" BO_ 133 0;
BA_ "GenMsgCycleTime" BO_ 133 10;
BA_ "GenMsgSendType" BO_ 133 0;
BA_ "GenMsgCycleTime" BO_ 980 30;
BA_ "GenMsgSendType" BO_ 980 0;
BA_ "GenMsgCycleTime" BO_ 1006 1000;
BA_ "GenMsgSendType" BO_ 1006 5;
BA_ "GenMsgDelayTime" BO_ 1200 10;
BA_ "GenMsgCycleTime" BO_ 1200 20;
BA_ "GenMsgSendType" BO_ 1200 0;
BA_ "GenMsgCycleTime" BO_ 989 1000;
BA_ "GenMsgSendType" BO_ 989 5;
BA_ "NetworkInitialization" BO_ 1852 0;
BA_ "GenMsgDelayTime" BO_ 1852 0;
BA_ "GenMsgSendType" BO_ 1852 1;
BA_ "DiagResponse" BO_ 1852 1;
BA_ "GenMsgILSupport" BO_ 1852 0;
BA_ "NetworkInitialization" BO_ 1844 0;
BA_ "GenMsgDelayTime" BO_ 1844 0;
BA_ "GenMsgSendType" BO_ 1844 1;
BA_ "DiagRequest" BO_ 1844 1;
BA_ "GenMsgILSupport" BO_ 1844 0;
BA_ "FrameGatewayNetwork" BO_ 945 "HS1_CAN";
BA_ "FrameGatewayHS1" BO_ 945 945;
BA_ "FrameGatewayId" BO_ 945 945;
BA_ "GenMsgStartDelayTime" BO_ 1102 1130;
BA_ "GenMsgCycleTime" BO_ 1102 100000;
BA_ "GenMsgSendType" BO_ 1102 5;
BA_ "GenMsgCycleTime" BO_ 962 1000;
BA_ "GenMsgSendType" BO_ 962 5;
BA_ "GenMsgCycleTime" BO_ 961 1000;
BA_ "GenMsgSendType" BO_ 961 5;
BA_ "FrameGatewayNetwork" BO_ 1122 "HS3_CAN";
BA_ "FrameGatewayHS3" BO_ 1122 1122;
BA_ "FrameGatewayId" BO_ 1122 1122;
BA_ "GenMsgCycleTime" BO_ 1080 1000;
BA_ "GenMsgSendType" BO_ 1080 5;
BA_ "GenMsgCycleTime" BO_ 1121 1000;
BA_ "GenMsgSendType" BO_ 1121 5;
BA_ "GenMsgDelayTime" BO_ 517 10;
BA_ "GenMsgCycleTime" BO_ 517 20;
BA_ "GenMsgSendType" BO_ 517 0;
BA_ "GenMsgCycleTime" BO_ 979 50;
BA_ "GenMsgSendType" BO_ 979 0;
BA_ "GenMsgCycleTime" BO_ 1056 1000;
BA_ "GenMsgSendType" BO_ 1056 5;
BA_ "FrameGatewayNetwork" BO_ 1215 "HS3_CAN";
BA_ "FrameGatewayHS3" BO_ 1215 559;
BA_ "FrameGatewayId" BO_ 1215 559;
BA_ "FrameGatewayNetwork" BO_ 1214 "HS3_CAN";
BA_ "FrameGatewayHS3" BO_ 1214 558;
BA_ "FrameGatewayId" BO_ 1214 558;
BA_ "GenMsgCycleTime" BO_ 673 100;
BA_ "GenMsgSendType" BO_ 673 5;
BA_ "FrameGatewayNetwork" BO_ 845 "MS1_CAN";
BA_ "FrameGatewayMS1" BO_ 845 845;
BA_ "FrameGatewayId" BO_ 845 845;
BA_ "FrameGatewayNetwork" BO_ 850 "MS1_CAN";
BA_ "FrameGatewayMS1" BO_ 850 850;
BA_ "FrameGatewayId" BO_ 850 850;
BA_ "GenMsgCycleTime" BO_ 820 60;
BA_ "GenMsgSendType" BO_ 820 0;
BA_ "FrameGatewayNetwork" BO_ 935 "MS1_CAN";
BA_ "FrameGatewayMS1" BO_ 935 935;
BA_ "FrameGatewayId" BO_ 935 935;
BA_ "FrameGatewayNetwork" BO_ 934 "MS1_CAN";
BA_ "FrameGatewayMS1" BO_ 934 934;
BA_ "FrameGatewayId" BO_ 934 934;
BA_ "U_U611_U625_MY20_Hev_Tx" SG_ 139 ActvFrontSteMsgTxt_D_Rq 1;
BA_ "U_U611_U625_MY20_Gas_Tx" SG_ 139 ActvFrontSteMsgTxt_D_Rq 1;
BA_ "U_U611_U625_MY20_Diesel_Tx" SG_ 139 ActvFrontSteMsgTxt_D_Rq 1;
BA_ "GenSigSendType" SG_ 139 ActvFrontSteMsgTxt_D_Rq 3;
BA_ "U_U611_U625_MY20_Hev_Tx" SG_ 139 ActvFrontSteLck_D_Stat 1;
BA_ "U_U611_U625_MY20_Gas_Tx" SG_ 139 ActvFrontSteLck_D_Stat 1;
BA_ "U_U611_U625_MY20_Diesel_Tx" SG_ 139 ActvFrontSteLck_D_Stat 1;
BA_ "GenSigSendType" SG_ 139 ActvFrontSteLck_D_Stat 3;
BA_ "U_U611_U625_MY20_Hev_Tx" SG_ 139 SelDrvMdeAdptSte_D_Stat 1;
BA_ "U_U611_U625_MY20_Gas_Tx" SG_ 139 SelDrvMdeAdptSte_D_Stat 1;
BA_ "U_U611_U625_MY20_Diesel_Tx" SG_ 139 SelDrvMdeAdptSte_D_Stat 1;
BA_ "U_CX482_CX483_MY20_Hev_Rx" SG_ 139 SelDrvMdeAdptSte_D_Stat 1;
BA_ "U_CX482_CX483_MY20_Gas_Rx" SG_ 139 SelDrvMdeAdptSte_D_Stat 1;
BA_ "U_CX482_CX483_MY20_Diesel_Rx" SG_ 139 SelDrvMdeAdptSte_D_Stat 1;
BA_ "U_U611_U625_MY20_Hev_Rx" SG_ 139 SelDrvMdeAdptSte_D_Stat 1;
BA_ "U_U611_U625_MY20_Gas_Rx" SG_ 139 SelDrvMdeAdptSte_D_Stat 1;
BA_ "U_U611_U625_MY20_Diesel_Rx" SG_ 139 SelDrvMdeAdptSte_D_Stat 1;
BA_ "U_B562_MY18_Gas_Rx" SG_ 139 SelDrvMdeAdptSte_D_Stat 1;
BA_ "U_C519_MY18_5_Gas_Rx" SG_ 139 SelDrvMdeAdptSte_D_Stat 1;
BA_ "U_C519_MY18_5_Diesel_Rx" SG_ 139 SelDrvMdeAdptSte_D_Stat 1;
BA_ "GenSigSendType" SG_ 139 SelDrvMdeAdptSte_D_Stat 3;
BA_ "U_U611_U625_MY20_Hev_Tx" SG_ 139 AslButtnOnOffPress2 1;
BA_ "U_U611_U625_MY20_Gas_Tx" SG_ 139 AslButtnOnOffPress2 1;
BA_ "U_U611_U625_MY20_Diesel_Tx" SG_ 139 AslButtnOnOffPress2 1;
BA_ "GenSigSendType" SG_ 139 AslButtnOnOffPress2 3;
BA_ "U_U611_U625_MY20_Hev_Tx" SG_ 139 AslButtnOnOffCnclPres2 1;
BA_ "U_U611_U625_MY20_Gas_Tx" SG_ 139 AslButtnOnOffCnclPres2 1;
BA_ "U_U611_U625_MY20_Diesel_Tx" SG_ 139 AslButtnOnOffCnclPres2 1;
BA_ "GenSigSendType" SG_ 139 AslButtnOnOffCnclPres2 3;
BA_ "U_U611_U625_MY20_Hev_Tx" SG_ 139 CcButtnOnPress2 1;
BA_ "U_U611_U625_MY20_Gas_Tx" SG_ 139 CcButtnOnPress2 1;
BA_ "U_U611_U625_MY20_Diesel_Tx" SG_ 139 CcButtnOnPress2 1;
BA_ "GenSigSendType" SG_ 139 CcButtnOnPress2 3;
BA_ "U_U611_U625_MY20_Hev_Tx" SG_ 139 CcButtnOnOffPress2 1;
BA_ "U_U611_U625_MY20_Gas_Tx" SG_ 139 CcButtnOnOffPress2 1;
BA_ "U_U611_U625_MY20_Diesel_Tx" SG_ 139 CcButtnOnOffPress2 1;
BA_ "GenSigSendType" SG_ 139 CcButtnOnOffPress2 3;
BA_ "U_U611_U625_MY20_Hev_Tx" SG_ 139 CcButtnOnOffCnclPress2 1;
BA_ "U_U611_U625_MY20_Gas_Tx" SG_ 139 CcButtnOnOffCnclPress2 1;
BA_ "U_U611_U625_MY20_Diesel_Tx" SG_ 139 CcButtnOnOffCnclPress2 1;
BA_ "GenSigSendType" SG_ 139 CcButtnOnOffCnclPress2 3;
BA_ "U_U611_U625_MY20_Hev_Tx" SG_ 139 CcButtnOffPress2 1;
BA_ "U_U611_U625_MY20_Gas_Tx" SG_ 139 CcButtnOffPress2 1;
BA_ "U_U611_U625_MY20_Diesel_Tx" SG_ 139 CcButtnOffPress2 1;
BA_ "GenSigSendType" SG_ 139 CcButtnOffPress2 3;
BA_ "U_U611_U625_MY20_Hev_Tx" SG_ 139 CcAsllButtnResPress2 1;
BA_ "U_U611_U625_MY20_Gas_Tx" SG_ 139 CcAsllButtnResPress2 1;
BA_ "U_U611_U625_MY20_Diesel_Tx" SG_ 139 CcAsllButtnResPress2 1;
BA_ "GenSigSendType" SG_ 139 CcAsllButtnResPress2 3;
BA_ "U_U611_U625_MY20_Hev_Tx" SG_ 139 CcAslButtnSetPress2 1;
BA_ "U_U611_U625_MY20_Gas_Tx" SG_ 139 CcAslButtnSetPress2 1;
BA_ "U_U611_U625_MY20_Diesel_Tx" SG_ 139 CcAslButtnSetPress2 1;
BA_ "GenSigSendType" SG_ 139 CcAslButtnSetPress2 3;
BA_ "U_U611_U625_MY20_Hev_Tx" SG_ 139 CcAslButtnSetIncPress2 1;
BA_ "U_U611_U625_MY20_Gas_Tx" SG_ 139 CcAslButtnSetIncPress2 1;
BA_ "U_U611_U625_MY20_Diesel_Tx" SG_ 139 CcAslButtnSetIncPress2 1;
BA_ "GenSigSendType" SG_ 139 CcAslButtnSetIncPress2 3;
BA_ "U_U611_U625_MY20_Hev_Tx" SG_ 139 CcAslButtnSetDecPress2 1;
BA_ "U_U611_U625_MY20_Gas_Tx" SG_ 139 CcAslButtnSetDecPress2 1;
BA_ "U_U611_U625_MY20_Diesel_Tx" SG_ 139 CcAslButtnSetDecPress2 1;
BA_ "GenSigSendType" SG_ 139 CcAslButtnSetDecPress2 3;
BA_ "U_U611_U625_MY20_Hev_Tx" SG_ 139 CcAslButtnResIncPress2 1;
BA_ "U_U611_U625_MY20_Gas_Tx" SG_ 139 CcAslButtnResIncPress2 1;
BA_ "U_U611_U625_MY20_Diesel_Tx" SG_ 139 CcAslButtnResIncPress2 1;
BA_ "GenSigSendType" SG_ 139 CcAslButtnResIncPress2 3;
BA_ "U_U611_U625_MY20_Hev_Tx" SG_ 139 CcAslButtnResDecPress2 1;
BA_ "U_U611_U625_MY20_Gas_Tx" SG_ 139 CcAslButtnResDecPress2 1;
BA_ "U_U611_U625_MY20_Diesel_Tx" SG_ 139 CcAslButtnResDecPress2 1;
BA_ "GenSigSendType" SG_ 139 CcAslButtnResDecPress2 3;
BA_ "U_U611_U625_MY20_Hev_Tx" SG_ 139 CcAslButtnOnPress2 1;
BA_ "U_U611_U625_MY20_Gas_Tx" SG_ 139 CcAslButtnOnPress2 1;
BA_ "U_U611_U625_MY20_Diesel_Tx" SG_ 139 CcAslButtnOnPress2 1;
BA_ "GenSigSendType" SG_ 139 CcAslButtnOnPress2 3;
BA_ "U_U611_U625_MY20_Hev_Tx" SG_ 139 CcAslButtnOnOffCncl2 1;
BA_ "U_U611_U625_MY20_Gas_Tx" SG_ 139 CcAslButtnOnOffCncl2 1;
BA_ "U_U611_U625_MY20_Diesel_Tx" SG_ 139 CcAslButtnOnOffCncl2 1;
BA_ "GenSigSendType" SG_ 139 CcAslButtnOnOffCncl2 3;
BA_ "U_U611_U625_MY20_Hev_Tx" SG_ 139 CcAslButtnOffCnclPres2 1;
BA_ "U_U611_U625_MY20_Gas_Tx" SG_ 139 CcAslButtnOffCnclPres2 1;
BA_ "U_U611_U625_MY20_Diesel_Tx" SG_ 139 CcAslButtnOffCnclPres2 1;
BA_ "GenSigSendType" SG_ 139 CcAslButtnOffCnclPres2 3;
BA_ "U_U611_U625_MY20_Hev_Tx" SG_ 139 CcAslButtnIndxIncPres2 1;
BA_ "U_U611_U625_MY20_Gas_Tx" SG_ 139 CcAslButtnIndxIncPres2 1;
BA_ "U_U611_U625_MY20_Diesel_Tx" SG_ 139 CcAslButtnIndxIncPres2 1;
BA_ "GenSigSendType" SG_ 139 CcAslButtnIndxIncPres2 3;
BA_ "U_U611_U625_MY20_Hev_Tx" SG_ 139 CcAslButtnIndxDecPres2 1;
BA_ "U_U611_U625_MY20_Gas_Tx" SG_ 139 CcAslButtnIndxDecPres2 1;
BA_ "U_U611_U625_MY20_Diesel_Tx" SG_ 139 CcAslButtnIndxDecPres2 1;
BA_ "GenSigSendType" SG_ 139 CcAslButtnIndxDecPres2 3;
BA_ "U_U611_U625_MY20_Hev_Tx" SG_ 139 CcAslButtnDeny_B_Actl2 1;
BA_ "U_U611_U625_MY20_Gas_Tx" SG_ 139 CcAslButtnDeny_B_Actl2 1;
BA_ "U_U611_U625_MY20_Diesel_Tx" SG_ 139 CcAslButtnDeny_B_Actl2 1;
BA_ "GenSigSendType" SG_ 139 CcAslButtnDeny_B_Actl2 3;
BA_ "U_U611_U625_MY20_Hev_Tx" SG_ 139 CcAslButtnCnclResPres2 1;
BA_ "U_U611_U625_MY20_Gas_Tx" SG_ 139 CcAslButtnCnclResPres2 1;
BA_ "U_U611_U625_MY20_Diesel_Tx" SG_ 139 CcAslButtnCnclResPres2 1;
BA_ "GenSigSendType" SG_ 139 CcAslButtnCnclResPres2 3;
BA_ "U_U611_U625_MY20_Hev_Tx" SG_ 139 CcAslButtnCnclPress2 1;
BA_ "U_U611_U625_MY20_Gas_Tx" SG_ 139 CcAslButtnCnclPress2 1;
BA_ "U_U611_U625_MY20_Diesel_Tx" SG_ 139 CcAslButtnCnclPress2 1;
BA_ "GenSigSendType" SG_ 139 CcAslButtnCnclPress2 3;
BA_ "U_U611_U625_MY20_Hev_Tx" SG_ 139 AccButtnGapIncPress2 1;
BA_ "U_U611_U625_MY20_Gas_Tx" SG_ 139 AccButtnGapIncPress2 1;
BA_ "U_U611_U625_MY20_Diesel_Tx" SG_ 139 AccButtnGapIncPress2 1;
BA_ "GenSigSendType" SG_ 139 AccButtnGapIncPress2 3;
BA_ "U_U611_U625_MY20_Hev_Tx" SG_ 139 AccButtnGapDecPress2 1;
BA_ "U_U611_U625_MY20_Gas_Tx" SG_ 139 AccButtnGapDecPress2 1;
BA_ "U_U611_U625_MY20_Diesel_Tx" SG_ 139 AccButtnGapDecPress2 1;
BA_ "GenSigSendType" SG_ 139 AccButtnGapDecPress2 3;
BA_ "U_CX482_CX483_MY20_Hev_Rx" SG_ 1186 SelDrvMdeAwd2_D_Stat 1;
BA_ "U_CX482_CX483_MY20_Gas_Rx" SG_ 1186 SelDrvMdeAwd2_D_Stat 1;
BA_ "U_CX482_CX483_MY20_Diesel_Rx" SG_ 1186 SelDrvMdeAwd2_D_Stat 1;
BA_ "U_U611_U625_MY20_Hev_Rx" SG_ 1186 SelDrvMdeAwd2_D_Stat 1;
BA_ "U_U611_U625_MY20_Gas_Rx" SG_ 1186 SelDrvMdeAwd2_D_Stat 1;
BA_ "U_U611_U625_MY20_Diesel_Rx" SG_ 1186 SelDrvMdeAwd2_D_Stat 1;
BA_ "U_C519_MY18_5_Gas_Rx" SG_ 1186 SelDrvMdeAwd2_D_Stat 1;
BA_ "U_C519_MY18_5_Diesel_Rx" SG_ 1186 SelDrvMdeAwd2_D_Stat 1;
BA_ "GenSigStartValue" SG_ 1186 SelDrvMdeAwd2_D_Stat 31;
BA_ "CrossOver_InfoCAN" SG_ 1186 LsdSrvcRqd_B_Rq 1;
BA_ "U_B515_MCA_MY17_Gas_Tx" SG_ 1042 VehSideSlip_An_Est 1;
BA_ "U_B515_MCA_MY17_Diesel_Tx" SG_ 1042 VehSideSlip_An_Est 1;
BA_ "GenSigStartValue" SG_ 1042 VehSideSlip_An_Est 250;
BA_ "U_B515_MCA_MY17_Gas_Tx" SG_ 1042 VehRol_An_Dsply 1;
BA_ "U_B515_MCA_MY17_Diesel_Tx" SG_ 1042 VehRol_An_Dsply 1;
BA_ "GenSigStartValue" SG_ 1042 VehRol_An_Dsply 64;
BA_ "U_B515_MCA_MY17_Gas_Tx" SG_ 1042 VehPtch_An_Dsply 1;
BA_ "U_B515_MCA_MY17_Diesel_Tx" SG_ 1042 VehPtch_An_Dsply 1;
BA_ "GenSigStartValue" SG_ 1042 VehPtch_An_Dsply 64;
BA_ "U_B515_MCA_MY17_Gas_Tx" SG_ 1042 TrlrBrk_Pc_Rq 1;
BA_ "U_B515_MCA_MY17_Diesel_Tx" SG_ 1042 TrlrBrk_Pc_Rq 1;
BA_ "U_U611_U625_MY20_Hev_Tx" SG_ 138 SteWhlRelCalib_T_Actl 1;
BA_ "U_U611_U625_MY20_Gas_Tx" SG_ 138 SteWhlRelCalib_T_Actl 1;
BA_ "U_U611_U625_MY20_Diesel_Tx" SG_ 138 SteWhlRelCalib_T_Actl 1;
BA_ "U_U611_U625_MY20_Hev_Rx" SG_ 138 SteWhlRelCalib_T_Actl 1;
BA_ "U_U611_U625_MY20_Gas_Rx" SG_ 138 SteWhlRelCalib_T_Actl 1;
BA_ "U_U611_U625_MY20_Diesel_Rx" SG_ 138 SteWhlRelCalib_T_Actl 1;
BA_ "U_U611_U625_MY20_Phev_Rx" SG_ 138 SteWhlRelCalib_An_Sns 1;
BA_ "U_U611_U625_MY20_Hev_Rx" SG_ 138 SteWhlRelCalib_An_Sns 1;
BA_ "U_U611_U625_MY20_Gas_Rx" SG_ 138 SteWhlRelCalib_An_Sns 1;
BA_ "U_U611_U625_MY20_Diesel_Rx" SG_ 138 SteWhlRelCalib_An_Sns 1;
BA_ "U_B500_MY18_Diesel_Rx" SG_ 138 SteWhlRelCalib_An_Sns 1;
BA_ "U_B500_MY18_Gas_Rx" SG_ 138 SteWhlRelCalib_An_Sns 1;
BA_ "U_B479_MY17_Diesel_Rx" SG_ 138 SteWhlRelCalib_An_Sns 1;
BA_ "U_B479_MY17_Gas_Rx" SG_ 138 SteWhlRelCalib_An_Sns 1;
BA_ "ContentDependant" SG_ 138 SteWhlRelCalib_An_Sns 1;
BA_ "GenSigSendType" SG_ 1878 TesterPhysicalReqPBM 3;
BA_ "GenSigSendType" SG_ 1886 TesterPhysicalResPBM 3;
BA_ "ContentDependant" SG_ 1471 PBM_GWOnBoardTesteR 1;
BA_ "GenSigStartValue" SG_ 1471 PBM_GWOnBoardTesteR 255;
BA_ "ContentDependant" SG_ 1471 PBM_GWNMProxy 1;
BA_ "GenSigStartValue" SG_ 1471 PBM_GWNMProxy 255;
BA_ "ContentDependant" SG_ 1471 PBM_AutoSarNMReserved4 1;
BA_ "GenSigStartValue" SG_ 1471 PBM_AutoSarNMReserved4 255;
BA_ "ContentDependant" SG_ 1471 PBM_AutoSarNMReserved3 1;
BA_ "GenSigStartValue" SG_ 1471 PBM_AutoSarNMReserved3 255;
BA_ "ContentDependant" SG_ 1471 PBM_AutoSarNMReserved2 1;
BA_ "GenSigStartValue" SG_ 1471 PBM_AutoSarNMReserved2 255;
BA_ "ContentDependant" SG_ 1471 PBM_AutoSarNMReserved1 1;
BA_ "GenSigStartValue" SG_ 1471 PBM_AutoSarNMReserved1 255;
BA_ "ContentDependant" SG_ 1471 PBM_AutoSarNMNodeId 1;
BA_ "GenSigStartValue" SG_ 1471 PBM_AutoSarNMNodeId 191;
BA_ "ContentDependant" SG_ 1471 PBM_AutoSarNMControl 1;
BA_ "U_U611_U625_MY20_Hev_Tx" SG_ 1951 TesterPhysicalResSASM 1;
BA_ "U_U611_U625_MY20_Gas_Tx" SG_ 1951 TesterPhysicalResSASM 1;
BA_ "U_U611_U625_MY20_Diesel_Tx" SG_ 1951 TesterPhysicalResSASM 1;
BA_ "GenSigSendType" SG_ 1951 TesterPhysicalResSASM 3;
BA_ "U_U611_U625_MY20_Hev_Rx" SG_ 1943 TesterPhysicalReqSASM 1;
BA_ "U_U611_U625_MY20_Gas_Rx" SG_ 1943 TesterPhysicalReqSASM 1;
BA_ "U_U611_U625_MY20_Diesel_Rx" SG_ 1943 TesterPhysicalReqSASM 1;
BA_ "GenSigSendType" SG_ 1943 TesterPhysicalReqSASM 3;
BA_ "U_U611_U625_MY20_Hev_Tx" SG_ 1485 SASM_GWOnBoardTester 1;
BA_ "U_U611_U625_MY20_Gas_Tx" SG_ 1485 SASM_GWOnBoardTester 1;
BA_ "U_U611_U625_MY20_Diesel_Tx" SG_ 1485 SASM_GWOnBoardTester 1;
BA_ "ContentDependant" SG_ 1485 SASM_GWOnBoardTester 1;
BA_ "GenSigStartValue" SG_ 1485 SASM_GWOnBoardTester 255;
BA_ "U_U611_U625_MY20_Hev_Tx" SG_ 1485 SASM_GWNMProxy 1;
BA_ "U_U611_U625_MY20_Gas_Tx" SG_ 1485 SASM_GWNMProxy 1;
BA_ "U_U611_U625_MY20_Diesel_Tx" SG_ 1485 SASM_GWNMProxy 1;
BA_ "ContentDependant" SG_ 1485 SASM_GWNMProxy 1;
BA_ "GenSigStartValue" SG_ 1485 SASM_GWNMProxy 255;
BA_ "U_U611_U625_MY20_Hev_Tx" SG_ 1485 SASM_AutoSarNMReserved4 1;
BA_ "U_U611_U625_MY20_Gas_Tx" SG_ 1485 SASM_AutoSarNMReserved4 1;
BA_ "U_U611_U625_MY20_Diesel_Tx" SG_ 1485 SASM_AutoSarNMReserved4 1;
BA_ "ContentDependant" SG_ 1485 SASM_AutoSarNMReserved4 1;
BA_ "GenSigStartValue" SG_ 1485 SASM_AutoSarNMReserved4 255;
BA_ "U_U611_U625_MY20_Hev_Tx" SG_ 1485 SASM_AutoSarNMReserved3 1;
BA_ "U_U611_U625_MY20_Gas_Tx" SG_ 1485 SASM_AutoSarNMReserved3 1;
BA_ "U_U611_U625_MY20_Diesel_Tx" SG_ 1485 SASM_AutoSarNMReserved3 1;
BA_ "ContentDependant" SG_ 1485 SASM_AutoSarNMReserved3 1;
BA_ "GenSigStartValue" SG_ 1485 SASM_AutoSarNMReserved3 255;
BA_ "U_U611_U625_MY20_Hev_Tx" SG_ 1485 SASM_AutoSarNMReserved2 1;
BA_ "U_U611_U625_MY20_Gas_Tx" SG_ 1485 SASM_AutoSarNMReserved2 1;
BA_ "U_U611_U625_MY20_Diesel_Tx" SG_ 1485 SASM_AutoSarNMReserved2 1;
BA_ "ContentDependant" SG_ 1485 SASM_AutoSarNMReserved2 1;
BA_ "GenSigStartValue" SG_ 1485 SASM_AutoSarNMReserved2 255;
BA_ "U_U611_U625_MY20_Hev_Tx" SG_ 1485 SASM_AutoSarNMReserved1 1;
BA_ "U_U611_U625_MY20_Gas_Tx" SG_ 1485 SASM_AutoSarNMReserved1 1;
BA_ "U_U611_U625_MY20_Diesel_Tx" SG_ 1485 SASM_AutoSarNMReserved1 1;
BA_ "ContentDependant" SG_ 1485 SASM_AutoSarNMReserved1 1;
BA_ "GenSigStartValue" SG_ 1485 SASM_AutoSarNMReserved1 255;
BA_ "U_U611_U625_MY20_Hev_Tx" SG_ 1485 SASM_AutoSarNMNodeId 1;
BA_ "U_U611_U625_MY20_Gas_Tx" SG_ 1485 SASM_AutoSarNMNodeId 1;
BA_ "U_U611_U625_MY20_Diesel_Tx" SG_ 1485 SASM_AutoSarNMNodeId 1;
BA_ "ContentDependant" SG_ 1485 SASM_AutoSarNMNodeId 1;
BA_ "GenSigStartValue" SG_ 1485 SASM_AutoSarNMNodeId 205;
BA_ "U_U611_U625_MY20_Hev_Tx" SG_ 1485 SASM_AutoSarNMControl 1;
BA_ "U_U611_U625_MY20_Gas_Tx" SG_ 1485 SASM_AutoSarNMControl 1;
BA_ "U_U611_U625_MY20_Diesel_Tx" SG_ 1485 SASM_AutoSarNMControl 1;
BA_ "ContentDependant" SG_ 1485 SASM_AutoSarNMControl 1;
BA_ "GenSigStartValue" SG_ 1090 TrlrAid_AnRate_Actl 500;
BA_ "GenSigStartValue" SG_ 1090 TrlrAid2_An_Actl 900;
BA_ "GenSigSendType" SG_ 1977 TesterPhysicalResIPMB 3;
BA_ "GenSigSendType" SG_ 1969 TesterPhysicalReqIPMB 3;
BA_ "CrossOver_InfoCAN" SG_ 132 GlblClkYr_No_Actl 1;
BA_ "CrossOver_InfoCAN" SG_ 132 GlblClkScnd_No_Actl 1;
BA_ "CrossOver_InfoCAN" SG_ 132 GlblClkMnte_No_Actl 1;
BA_ "CrossOver_InfoCAN" SG_ 132 GlblClkHr_No_Actl 1;
BA_ "CrossOver_InfoCAN" SG_ 132 GlblClkDay_No_Actl 1;
BA_ "U_LC1_B500_MY18_Gas_Tx" SG_ 73 immoSubTarget1Data_T1 1;
BA_ "U_LC1_B500_MY18_Diesel_Tx" SG_ 73 immoSubTarget1Data_T1 1;
BA_ "U_CX482_CX483_MY20_Hev_Tx" SG_ 73 immoSubTarget1Data_T1 1;
BA_ "U_CX482_CX483_MY20_Gas_Tx" SG_ 73 immoSubTarget1Data_T1 1;
BA_ "U_CX482_CX483_MY20_Diesel_Tx" SG_ 73 immoSubTarget1Data_T1 1;
BA_ "U_U611_U625_MY20_Hev_Tx" SG_ 73 immoSubTarget1Data_T1 1;
BA_ "U_U611_U625_MY20_Gas_Tx" SG_ 73 immoSubTarget1Data_T1 1;
BA_ "U_U611_U625_MY20_Diesel_Tx" SG_ 73 immoSubTarget1Data_T1 1;
BA_ "U_B500_MY18_Diesel_Tx" SG_ 73 immoSubTarget1Data_T1 1;
BA_ "U_B500_MY18_Gas_Tx" SG_ 73 immoSubTarget1Data_T1 1;
BA_ "U_C490_MY18_Tx" SG_ 73 immoSubTarget1Data_T1 1;
BA_ "U_B562_MY18_Gas_Tx" SG_ 73 immoSubTarget1Data_T1 1;
BA_ "U_C519_MY18_5_Gas_Tx" SG_ 73 immoSubTarget1Data_T1 1;
BA_ "U_C519_MY18_5_Diesel_Tx" SG_ 73 immoSubTarget1Data_T1 1;
BA_ "U_B515_MCA_MY17_Gas_Tx" SG_ 73 immoSubTarget1Data_T1 1;
BA_ "U_B515_MCA_MY17_Diesel_Tx" SG_ 73 immoSubTarget1Data_T1 1;
BA_ "U_B479_MY17_Diesel_Tx" SG_ 73 immoSubTarget1Data_T1 1;
BA_ "U_B479_MY17_Gas_Tx" SG_ 73 immoSubTarget1Data_T1 1;
BA_ "U_B562LC_MY15_Gas_Tx" SG_ 73 immoSubTarget1Data_T1 1;
BA_ "U_B562LC_MY15_Diesel_Tx" SG_ 73 immoSubTarget1Data_T1 1;
BA_ "U_LC1_B500_MY18_Gas_Tx" SG_ 73 immoSubTarget1Cmd_T1 1;
BA_ "U_LC1_B500_MY18_Diesel_Tx" SG_ 73 immoSubTarget1Cmd_T1 1;
BA_ "U_CX482_CX483_MY20_Hev_Tx" SG_ 73 immoSubTarget1Cmd_T1 1;
BA_ "U_CX482_CX483_MY20_Gas_Tx" SG_ 73 immoSubTarget1Cmd_T1 1;
BA_ "U_CX482_CX483_MY20_Diesel_Tx" SG_ 73 immoSubTarget1Cmd_T1 1;
BA_ "U_U611_U625_MY20_Hev_Tx" SG_ 73 immoSubTarget1Cmd_T1 1;
BA_ "U_U611_U625_MY20_Gas_Tx" SG_ 73 immoSubTarget1Cmd_T1 1;
BA_ "U_U611_U625_MY20_Diesel_Tx" SG_ 73 immoSubTarget1Cmd_T1 1;
BA_ "U_B500_MY18_Diesel_Tx" SG_ 73 immoSubTarget1Cmd_T1 1;
BA_ "U_B500_MY18_Gas_Tx" SG_ 73 immoSubTarget1Cmd_T1 1;
BA_ "U_C490_MY18_Tx" SG_ 73 immoSubTarget1Cmd_T1 1;
BA_ "U_B562_MY18_Gas_Tx" SG_ 73 immoSubTarget1Cmd_T1 1;
BA_ "U_C519_MY18_5_Gas_Tx" SG_ 73 immoSubTarget1Cmd_T1 1;
BA_ "U_C519_MY18_5_Diesel_Tx" SG_ 73 immoSubTarget1Cmd_T1 1;
BA_ "U_B515_MCA_MY17_Gas_Tx" SG_ 73 immoSubTarget1Cmd_T1 1;
BA_ "U_B515_MCA_MY17_Diesel_Tx" SG_ 73 immoSubTarget1Cmd_T1 1;
BA_ "U_B479_MY17_Diesel_Tx" SG_ 73 immoSubTarget1Cmd_T1 1;
BA_ "U_B479_MY17_Gas_Tx" SG_ 73 immoSubTarget1Cmd_T1 1;
BA_ "U_B562LC_MY15_Gas_Tx" SG_ 73 immoSubTarget1Cmd_T1 1;
BA_ "U_B562LC_MY15_Diesel_Tx" SG_ 73 immoSubTarget1Cmd_T1 1;
BA_ "GenSigStartValue" SG_ 133 SteWhlOSRelInit2An_Est 65534;
BA_ "U_U611_U625_MY20_Phev_Rx" SG_ 133 SteWhlRelCalib_An_Sns 1;
BA_ "U_U611_U625_MY20_Hev_Rx" SG_ 133 SteWhlRelCalib_An_Sns 1;
BA_ "U_U611_U625_MY20_Gas_Rx" SG_ 133 SteWhlRelCalib_An_Sns 1;
BA_ "U_U611_U625_MY20_Diesel_Rx" SG_ 133 SteWhlRelCalib_An_Sns 1;
BA_ "U_B500_MY18_Diesel_Rx" SG_ 133 SteWhlRelCalib_An_Sns 1;
BA_ "U_B500_MY18_Gas_Rx" SG_ 133 SteWhlRelCalib_An_Sns 1;
BA_ "U_B479_MY17_Diesel_Rx" SG_ 133 SteWhlRelCalib_An_Sns 1;
BA_ "U_B479_MY17_Gas_Rx" SG_ 133 SteWhlRelCalib_An_Sns 1;
BA_ "ContentDependant" SG_ 133 SteWhlRelCalib_An_Sns 1;
BA_ "U_U611_U625_MY20_Hev_Rx" SG_ 133 SteWhlRelInit2_An_Sns 1;
BA_ "U_U611_U625_MY20_Gas_Rx" SG_ 133 SteWhlRelInit2_An_Sns 1;
BA_ "U_U611_U625_MY20_Diesel_Rx" SG_ 133 SteWhlRelInit2_An_Sns 1;
BA_ "U_C519_MY18_5_Gas_Rx" SG_ 133 SteWhlRelInit2_An_Sns 1;
BA_ "U_C519_MY18_5_Diesel_Rx" SG_ 133 SteWhlRelInit2_An_Sns 1;
BA_ "ContentDependant" SG_ 133 SteWhlRelInit2_An_Sns 1;
BA_ "GenSigStartValue" SG_ 133 SteWhlRelInit2_An_Sns 65535;
BA_ "U_CX482_CX483_MY20_Hev_Tx" SG_ 980 AdbRampingV_D_Rq 1;
BA_ "U_CX482_CX483_MY20_Gas_Tx" SG_ 980 AdbRampingV_D_Rq 1;
BA_ "U_CX482_CX483_MY20_Diesel_Tx" SG_ 980 AdbRampingV_D_Rq 1;
BA_ "U_U611_U625_MY20_Hev_Tx" SG_ 980 AdbRampingV_D_Rq 1;
BA_ "U_U611_U625_MY20_Gas_Tx" SG_ 980 AdbRampingV_D_Rq 1;
BA_ "U_U611_U625_MY20_Diesel_Tx" SG_ 980 AdbRampingV_D_Rq 1;
BA_ "U_C519_MY18_5_Gas_Tx" SG_ 980 AdbRampingV_D_Rq 1;
BA_ "U_C519_MY18_5_Diesel_Tx" SG_ 980 AdbRampingV_D_Rq 1;
BA_ "U_CX482_CX483_MY20_Hev_Rx" SG_ 980 AdbRampingV_D_Rq 1;
BA_ "U_CX482_CX483_MY20_Gas_Rx" SG_ 980 AdbRampingV_D_Rq 1;
BA_ "U_CX482_CX483_MY20_Diesel_Rx" SG_ 980 AdbRampingV_D_Rq 1;
BA_ "U_U611_U625_MY20_Hev_Rx" SG_ 980 AdbRampingV_D_Rq 1;
BA_ "U_U611_U625_MY20_Gas_Rx" SG_ 980 AdbRampingV_D_Rq 1;
BA_ "U_U611_U625_MY20_Diesel_Rx" SG_ 980 AdbRampingV_D_Rq 1;
BA_ "U_C519_MY18_5_Gas_Rx" SG_ 980 AdbRampingV_D_Rq 1;
BA_ "U_C519_MY18_5_Diesel_Rx" SG_ 980 AdbRampingV_D_Rq 1;
BA_ "U_CX482_CX483_MY20_Hev_Tx" SG_ 980 AdbMde1_D_Rq 1;
BA_ "U_CX482_CX483_MY20_Gas_Tx" SG_ 980 AdbMde1_D_Rq 1;
BA_ "U_CX482_CX483_MY20_Diesel_Tx" SG_ 980 AdbMde1_D_Rq 1;
BA_ "U_U611_U625_MY20_Hev_Tx" SG_ 980 AdbMde1_D_Rq 1;
BA_ "U_U611_U625_MY20_Gas_Tx" SG_ 980 AdbMde1_D_Rq 1;
BA_ "U_U611_U625_MY20_Diesel_Tx" SG_ 980 AdbMde1_D_Rq 1;
BA_ "U_C519_MY18_5_Gas_Tx" SG_ 980 AdbMde1_D_Rq 1;
BA_ "U_C519_MY18_5_Diesel_Tx" SG_ 980 AdbMde1_D_Rq 1;
BA_ "U_CX482_CX483_MY20_Hev_Rx" SG_ 980 AdbMde1_D_Rq 1;
BA_ "U_CX482_CX483_MY20_Gas_Rx" SG_ 980 AdbMde1_D_Rq 1;
BA_ "U_CX482_CX483_MY20_Diesel_Rx" SG_ 980 AdbMde1_D_Rq 1;
BA_ "U_U611_U625_MY20_Hev_Rx" SG_ 980 AdbMde1_D_Rq 1;
BA_ "U_U611_U625_MY20_Gas_Rx" SG_ 980 AdbMde1_D_Rq 1;
BA_ "U_U611_U625_MY20_Diesel_Rx" SG_ 980 AdbMde1_D_Rq 1;
BA_ "U_C519_MY18_5_Gas_Rx" SG_ 980 AdbMde1_D_Rq 1;
BA_ "U_C519_MY18_5_Diesel_Rx" SG_ 980 AdbMde1_D_Rq 1;
BA_ "U_CX482_CX483_MY20_Hev_Tx" SG_ 980 AdbLampOnOff_D_Rq 1;
BA_ "U_CX482_CX483_MY20_Gas_Tx" SG_ 980 AdbLampOnOff_D_Rq 1;
BA_ "U_CX482_CX483_MY20_Diesel_Tx" SG_ 980 AdbLampOnOff_D_Rq 1;
BA_ "U_U611_U625_MY20_Hev_Tx" SG_ 980 AdbLampOnOff_D_Rq 1;
BA_ "U_U611_U625_MY20_Gas_Tx" SG_ 980 AdbLampOnOff_D_Rq 1;
BA_ "U_U611_U625_MY20_Diesel_Tx" SG_ 980 AdbLampOnOff_D_Rq 1;
BA_ "U_C519_MY18_5_Gas_Tx" SG_ 980 AdbLampOnOff_D_Rq 1;
BA_ "U_C519_MY18_5_Diesel_Tx" SG_ 980 AdbLampOnOff_D_Rq 1;
BA_ "U_CX482_CX483_MY20_Hev_Rx" SG_ 980 AdbLampOnOff_D_Rq 1;
BA_ "U_CX482_CX483_MY20_Gas_Rx" SG_ 980 AdbLampOnOff_D_Rq 1;
BA_ "U_CX482_CX483_MY20_Diesel_Rx" SG_ 980 AdbLampOnOff_D_Rq 1;
BA_ "U_U611_U625_MY20_Hev_Rx" SG_ 980 AdbLampOnOff_D_Rq 1;
BA_ "U_U611_U625_MY20_Gas_Rx" SG_ 980 AdbLampOnOff_D_Rq 1;
BA_ "U_U611_U625_MY20_Diesel_Rx" SG_ 980 AdbLampOnOff_D_Rq 1;
BA_ "U_C519_MY18_5_Gas_Rx" SG_ 980 AdbLampOnOff_D_Rq 1;
BA_ "U_C519_MY18_5_Diesel_Rx" SG_ 980 AdbLampOnOff_D_Rq 1;
BA_ "U_CX482_CX483_MY20_Hev_Tx" SG_ 980 AdbIntns1_D_Rq 1;
BA_ "U_CX482_CX483_MY20_Gas_Tx" SG_ 980 AdbIntns1_D_Rq 1;
BA_ "U_CX482_CX483_MY20_Diesel_Tx" SG_ 980 AdbIntns1_D_Rq 1;
BA_ "U_U611_U625_MY20_Hev_Tx" SG_ 980 AdbIntns1_D_Rq 1;
BA_ "U_U611_U625_MY20_Gas_Tx" SG_ 980 AdbIntns1_D_Rq 1;
BA_ "U_U611_U625_MY20_Diesel_Tx" SG_ 980 AdbIntns1_D_Rq 1;
BA_ "U_C519_MY18_5_Gas_Tx" SG_ 980 AdbIntns1_D_Rq 1;
BA_ "U_C519_MY18_5_Diesel_Tx" SG_ 980 AdbIntns1_D_Rq 1;
BA_ "U_CX482_CX483_MY20_Hev_Rx" SG_ 980 AdbIntns1_D_Rq 1;
BA_ "U_CX482_CX483_MY20_Gas_Rx" SG_ 980 AdbIntns1_D_Rq 1;
BA_ "U_CX482_CX483_MY20_Diesel_Rx" SG_ 980 AdbIntns1_D_Rq 1;
BA_ "U_U611_U625_MY20_Hev_Rx" SG_ 980 AdbIntns1_D_Rq 1;
BA_ "U_U611_U625_MY20_Gas_Rx" SG_ 980 AdbIntns1_D_Rq 1;
BA_ "U_U611_U625_MY20_Diesel_Rx" SG_ 980 AdbIntns1_D_Rq 1;
BA_ "U_C519_MY18_5_Gas_Rx" SG_ 980 AdbIntns1_D_Rq 1;
BA_ "U_C519_MY18_5_Diesel_Rx" SG_ 980 AdbIntns1_D_Rq 1;
BA_ "U_CX482_CX483_MY20_Hev_Tx" SG_ 980 AdbHiBeamKeepOff_D_Rq 1;
BA_ "U_CX482_CX483_MY20_Gas_Tx" SG_ 980 AdbHiBeamKeepOff_D_Rq 1;
BA_ "U_CX482_CX483_MY20_Diesel_Tx" SG_ 980 AdbHiBeamKeepOff_D_Rq 1;
BA_ "U_U611_U625_MY20_Hev_Tx" SG_ 980 AdbHiBeamKeepOff_D_Rq 1;
BA_ "U_U611_U625_MY20_Gas_Tx" SG_ 980 AdbHiBeamKeepOff_D_Rq 1;
BA_ "U_U611_U625_MY20_Diesel_Tx" SG_ 980 AdbHiBeamKeepOff_D_Rq 1;
BA_ "U_C519_MY18_5_Gas_Tx" SG_ 980 AdbHiBeamKeepOff_D_Rq 1;
BA_ "U_C519_MY18_5_Diesel_Tx" SG_ 980 AdbHiBeamKeepOff_D_Rq 1;
BA_ "U_CX482_CX483_MY20_Hev_Rx" SG_ 980 AdbHiBeamKeepOff_D_Rq 1;
BA_ "U_CX482_CX483_MY20_Gas_Rx" SG_ 980 AdbHiBeamKeepOff_D_Rq 1;
BA_ "U_CX482_CX483_MY20_Diesel_Rx" SG_ 980 AdbHiBeamKeepOff_D_Rq 1;
BA_ "U_U611_U625_MY20_Hev_Rx" SG_ 980 AdbHiBeamKeepOff_D_Rq 1;
BA_ "U_U611_U625_MY20_Gas_Rx" SG_ 980 AdbHiBeamKeepOff_D_Rq 1;
BA_ "U_U611_U625_MY20_Diesel_Rx" SG_ 980 AdbHiBeamKeepOff_D_Rq 1;
BA_ "U_C519_MY18_5_Gas_Rx" SG_ 980 AdbHiBeamKeepOff_D_Rq 1;
BA_ "U_C519_MY18_5_Diesel_Rx" SG_ 980 AdbHiBeamKeepOff_D_Rq 1;
BA_ "U_CX482_CX483_MY20_Hev_Tx" SG_ 980 AdbDividedRoad_B_Stat 1;
BA_ "U_CX482_CX483_MY20_Gas_Tx" SG_ 980 AdbDividedRoad_B_Stat 1;
BA_ "U_CX482_CX483_MY20_Diesel_Tx" SG_ 980 AdbDividedRoad_B_Stat 1;
BA_ "U_U611_U625_MY20_Hev_Tx" SG_ 980 AdbDividedRoad_B_Stat 1;
BA_ "U_U611_U625_MY20_Gas_Tx" SG_ 980 AdbDividedRoad_B_Stat 1;
BA_ "U_U611_U625_MY20_Diesel_Tx" SG_ 980 AdbDividedRoad_B_Stat 1;
BA_ "U_C519_MY18_5_Gas_Tx" SG_ 980 AdbDividedRoad_B_Stat 1;
BA_ "U_C519_MY18_5_Diesel_Tx" SG_ 980 AdbDividedRoad_B_Stat 1;
BA_ "U_CX482_CX483_MY20_Hev_Rx" SG_ 980 AdbDividedRoad_B_Stat 1;
BA_ "U_CX482_CX483_MY20_Gas_Rx" SG_ 980 AdbDividedRoad_B_Stat 1;
BA_ "U_CX482_CX483_MY20_Diesel_Rx" SG_ 980 AdbDividedRoad_B_Stat 1;
BA_ "U_U611_U625_MY20_Hev_Rx" SG_ 980 AdbDividedRoad_B_Stat 1;
BA_ "U_U611_U625_MY20_Gas_Rx" SG_ 980 AdbDividedRoad_B_Stat 1;
BA_ "U_U611_U625_MY20_Diesel_Rx" SG_ 980 AdbDividedRoad_B_Stat 1;
BA_ "U_C519_MY18_5_Gas_Rx" SG_ 980 AdbDividedRoad_B_Stat 1;
BA_ "U_C519_MY18_5_Diesel_Rx" SG_ 980 AdbDividedRoad_B_Stat 1;
BA_ "U_CX482_CX483_MY20_Hev_Tx" SG_ 980 AdbBrdr1Up_An_Rq 1;
BA_ "U_CX482_CX483_MY20_Gas_Tx" SG_ 980 AdbBrdr1Up_An_Rq 1;
BA_ "U_CX482_CX483_MY20_Diesel_Tx" SG_ 980 AdbBrdr1Up_An_Rq 1;
BA_ "U_U611_U625_MY20_Hev_Tx" SG_ 980 AdbBrdr1Up_An_Rq 1;
BA_ "U_U611_U625_MY20_Gas_Tx" SG_ 980 AdbBrdr1Up_An_Rq 1;
BA_ "U_U611_U625_MY20_Diesel_Tx" SG_ 980 AdbBrdr1Up_An_Rq 1;
BA_ "U_C519_MY18_5_Gas_Tx" SG_ 980 AdbBrdr1Up_An_Rq 1;
BA_ "U_C519_MY18_5_Diesel_Tx" SG_ 980 AdbBrdr1Up_An_Rq 1;
BA_ "U_CX482_CX483_MY20_Hev_Rx" SG_ 980 AdbBrdr1Up_An_Rq 1;
BA_ "U_CX482_CX483_MY20_Gas_Rx" SG_ 980 AdbBrdr1Up_An_Rq 1;
BA_ "U_CX482_CX483_MY20_Diesel_Rx" SG_ 980 AdbBrdr1Up_An_Rq 1;
BA_ "U_U611_U625_MY20_Hev_Rx" SG_ 980 AdbBrdr1Up_An_Rq 1;
BA_ "U_U611_U625_MY20_Gas_Rx" SG_ 980 AdbBrdr1Up_An_Rq 1;
BA_ "U_U611_U625_MY20_Diesel_Rx" SG_ 980 AdbBrdr1Up_An_Rq 1;
BA_ "U_C519_MY18_5_Gas_Rx" SG_ 980 AdbBrdr1Up_An_Rq 1;
BA_ "U_C519_MY18_5_Diesel_Rx" SG_ 980 AdbBrdr1Up_An_Rq 1;
BA_ "GenSigStartValue" SG_ 980 AdbBrdr1Up_An_Rq 510;
BA_ "U_CX482_CX483_MY20_Hev_Tx" SG_ 980 AdbBrdr1Right_An_Rq 1;
BA_ "U_CX482_CX483_MY20_Gas_Tx" SG_ 980 AdbBrdr1Right_An_Rq 1;
BA_ "U_CX482_CX483_MY20_Diesel_Tx" SG_ 980 AdbBrdr1Right_An_Rq 1;
BA_ "U_U611_U625_MY20_Hev_Tx" SG_ 980 AdbBrdr1Right_An_Rq 1;
BA_ "U_U611_U625_MY20_Gas_Tx" SG_ 980 AdbBrdr1Right_An_Rq 1;
BA_ "U_U611_U625_MY20_Diesel_Tx" SG_ 980 AdbBrdr1Right_An_Rq 1;
BA_ "U_C519_MY18_5_Gas_Tx" SG_ 980 AdbBrdr1Right_An_Rq 1;
BA_ "U_C519_MY18_5_Diesel_Tx" SG_ 980 AdbBrdr1Right_An_Rq 1;
BA_ "U_CX482_CX483_MY20_Hev_Rx" SG_ 980 AdbBrdr1Right_An_Rq 1;
BA_ "U_CX482_CX483_MY20_Gas_Rx" SG_ 980 AdbBrdr1Right_An_Rq 1;
BA_ "U_CX482_CX483_MY20_Diesel_Rx" SG_ 980 AdbBrdr1Right_An_Rq 1;
BA_ "U_U611_U625_MY20_Hev_Rx" SG_ 980 AdbBrdr1Right_An_Rq 1;
BA_ "U_U611_U625_MY20_Gas_Rx" SG_ 980 AdbBrdr1Right_An_Rq 1;
BA_ "U_U611_U625_MY20_Diesel_Rx" SG_ 980 AdbBrdr1Right_An_Rq 1;
BA_ "U_C519_MY18_5_Gas_Rx" SG_ 980 AdbBrdr1Right_An_Rq 1;
BA_ "U_C519_MY18_5_Diesel_Rx" SG_ 980 AdbBrdr1Right_An_Rq 1;
BA_ "GenSigStartValue" SG_ 980 AdbBrdr1Right_An_Rq 2046;
BA_ "U_CX482_CX483_MY20_Hev_Tx" SG_ 980 AdbBrdr1Low_An_Rq 1;
BA_ "U_CX482_CX483_MY20_Gas_Tx" SG_ 980 AdbBrdr1Low_An_Rq 1;
BA_ "U_CX482_CX483_MY20_Diesel_Tx" SG_ 980 AdbBrdr1Low_An_Rq 1;
BA_ "U_U611_U625_MY20_Hev_Tx" SG_ 980 AdbBrdr1Low_An_Rq 1;
BA_ "U_U611_U625_MY20_Gas_Tx" SG_ 980 AdbBrdr1Low_An_Rq 1;
BA_ "U_U611_U625_MY20_Diesel_Tx" SG_ 980 AdbBrdr1Low_An_Rq 1;
BA_ "U_C519_MY18_5_Gas_Tx" SG_ 980 AdbBrdr1Low_An_Rq 1;
BA_ "U_C519_MY18_5_Diesel_Tx" SG_ 980 AdbBrdr1Low_An_Rq 1;
BA_ "U_CX482_CX483_MY20_Hev_Rx" SG_ 980 AdbBrdr1Low_An_Rq 1;
BA_ "U_CX482_CX483_MY20_Gas_Rx" SG_ 980 AdbBrdr1Low_An_Rq 1;
BA_ "U_CX482_CX483_MY20_Diesel_Rx" SG_ 980 AdbBrdr1Low_An_Rq 1;
BA_ "U_U611_U625_MY20_Hev_Rx" SG_ 980 AdbBrdr1Low_An_Rq 1;
BA_ "U_U611_U625_MY20_Gas_Rx" SG_ 980 AdbBrdr1Low_An_Rq 1;
BA_ "U_U611_U625_MY20_Diesel_Rx" SG_ 980 AdbBrdr1Low_An_Rq 1;
BA_ "U_C519_MY18_5_Gas_Rx" SG_ 980 AdbBrdr1Low_An_Rq 1;
BA_ "U_C519_MY18_5_Diesel_Rx" SG_ 980 AdbBrdr1Low_An_Rq 1;
BA_ "GenSigStartValue" SG_ 980 AdbBrdr1Low_An_Rq 510;
BA_ "U_CX482_CX483_MY20_Hev_Tx" SG_ 980 AdbBrdr1Left_An_Rq 1;
BA_ "U_CX482_CX483_MY20_Gas_Tx" SG_ 980 AdbBrdr1Left_An_Rq 1;
BA_ "U_CX482_CX483_MY20_Diesel_Tx" SG_ 980 AdbBrdr1Left_An_Rq 1;
BA_ "U_U611_U625_MY20_Hev_Tx" SG_ 980 AdbBrdr1Left_An_Rq 1;
BA_ "U_U611_U625_MY20_Gas_Tx" SG_ 980 AdbBrdr1Left_An_Rq 1;
BA_ "U_U611_U625_MY20_Diesel_Tx" SG_ 980 AdbBrdr1Left_An_Rq 1;
BA_ "U_C519_MY18_5_Gas_Tx" SG_ 980 AdbBrdr1Left_An_Rq 1;
BA_ "U_C519_MY18_5_Diesel_Tx" SG_ 980 AdbBrdr1Left_An_Rq 1;
BA_ "U_CX482_CX483_MY20_Hev_Rx" SG_ 980 AdbBrdr1Left_An_Rq 1;
BA_ "U_CX482_CX483_MY20_Gas_Rx" SG_ 980 AdbBrdr1Left_An_Rq 1;
BA_ "U_CX482_CX483_MY20_Diesel_Rx" SG_ 980 AdbBrdr1Left_An_Rq 1;
BA_ "U_U611_U625_MY20_Hev_Rx" SG_ 980 AdbBrdr1Left_An_Rq 1;
BA_ "U_U611_U625_MY20_Gas_Rx" SG_ 980 AdbBrdr1Left_An_Rq 1;
BA_ "U_U611_U625_MY20_Diesel_Rx" SG_ 980 AdbBrdr1Left_An_Rq 1;
BA_ "U_C519_MY18_5_Gas_Rx" SG_ 980 AdbBrdr1Left_An_Rq 1;
BA_ "U_C519_MY18_5_Diesel_Rx" SG_ 980 AdbBrdr1Left_An_Rq 1;
BA_ "GenSigStartValue" SG_ 980 AdbBrdr1Left_An_Rq 2046;
BA_ "U_CX482_CX483_MY20_Hev_Tx" SG_ 980 AdbBrdr1CritRigh_T_Stat 1;
BA_ "U_CX482_CX483_MY20_Gas_Tx" SG_ 980 AdbBrdr1CritRigh_T_Stat 1;
BA_ "U_CX482_CX483_MY20_Diesel_Tx" SG_ 980 AdbBrdr1CritRigh_T_Stat 1;
BA_ "U_U611_U625_MY20_Hev_Tx" SG_ 980 AdbBrdr1CritRigh_T_Stat 1;
BA_ "U_U611_U625_MY20_Gas_Tx" SG_ 980 AdbBrdr1CritRigh_T_Stat 1;
BA_ "U_U611_U625_MY20_Diesel_Tx" SG_ 980 AdbBrdr1CritRigh_T_Stat 1;
BA_ "U_C519_MY18_5_Gas_Tx" SG_ 980 AdbBrdr1CritRigh_T_Stat 1;
BA_ "U_C519_MY18_5_Diesel_Tx" SG_ 980 AdbBrdr1CritRigh_T_Stat 1;
BA_ "U_CX482_CX483_MY20_Hev_Rx" SG_ 980 AdbBrdr1CritRigh_T_Stat 1;
BA_ "U_CX482_CX483_MY20_Gas_Rx" SG_ 980 AdbBrdr1CritRigh_T_Stat 1;
BA_ "U_CX482_CX483_MY20_Diesel_Rx" SG_ 980 AdbBrdr1CritRigh_T_Stat 1;
BA_ "U_U611_U625_MY20_Hev_Rx" SG_ 980 AdbBrdr1CritRigh_T_Stat 1;
BA_ "U_U611_U625_MY20_Gas_Rx" SG_ 980 AdbBrdr1CritRigh_T_Stat 1;
BA_ "U_U611_U625_MY20_Diesel_Rx" SG_ 980 AdbBrdr1CritRigh_T_Stat 1;
BA_ "U_C519_MY18_5_Gas_Rx" SG_ 980 AdbBrdr1CritRigh_T_Stat 1;
BA_ "U_C519_MY18_5_Diesel_Rx" SG_ 980 AdbBrdr1CritRigh_T_Stat 1;
BA_ "U_CX482_CX483_MY20_Hev_Tx" SG_ 980 AdbBrdr1CritLeft_T_Stat 1;
BA_ "U_CX482_CX483_MY20_Gas_Tx" SG_ 980 AdbBrdr1CritLeft_T_Stat 1;
BA_ "U_CX482_CX483_MY20_Diesel_Tx" SG_ 980 AdbBrdr1CritLeft_T_Stat 1;
BA_ "U_U611_U625_MY20_Hev_Tx" SG_ 980 AdbBrdr1CritLeft_T_Stat 1;
BA_ "U_U611_U625_MY20_Gas_Tx" SG_ 980 AdbBrdr1CritLeft_T_Stat 1;
BA_ "U_U611_U625_MY20_Diesel_Tx" SG_ 980 AdbBrdr1CritLeft_T_Stat 1;
BA_ "U_C519_MY18_5_Gas_Tx" SG_ 980 AdbBrdr1CritLeft_T_Stat 1;
BA_ "U_C519_MY18_5_Diesel_Tx" SG_ 980 AdbBrdr1CritLeft_T_Stat 1;
BA_ "U_CX482_CX483_MY20_Hev_Rx" SG_ 980 AdbBrdr1CritLeft_T_Stat 1;
BA_ "U_CX482_CX483_MY20_Gas_Rx" SG_ 980 AdbBrdr1CritLeft_T_Stat 1;
BA_ "U_CX482_CX483_MY20_Diesel_Rx" SG_ 980 AdbBrdr1CritLeft_T_Stat 1;
BA_ "U_U611_U625_MY20_Hev_Rx" SG_ 980 AdbBrdr1CritLeft_T_Stat 1;
BA_ "U_U611_U625_MY20_Gas_Rx" SG_ 980 AdbBrdr1CritLeft_T_Stat 1;
BA_ "U_U611_U625_MY20_Diesel_Rx" SG_ 980 AdbBrdr1CritLeft_T_Stat 1;
BA_ "U_C519_MY18_5_Gas_Rx" SG_ 980 AdbBrdr1CritLeft_T_Stat 1;
BA_ "U_C519_MY18_5_Diesel_Rx" SG_ 980 AdbBrdr1CritLeft_T_Stat 1;
BA_ "GenSigSendType" SG_ 1006 PersIndexIpmb_D_Actl 3;
BA_ "GenSigStartValue" SG_ 1006 PersIndexIpmb_D_Actl 4;
BA_ "CrossOver_InfoCAN" SG_ 1006 PersIndexIpmb_D_Actl 1;
BA_ "GenSigSendType" SG_ 1006 FeatNoIpmbActl 3;
BA_ "CrossOver_InfoCAN" SG_ 1006 FeatNoIpmbActl 1;
BA_ "GenSigSendType" SG_ 1006 FeatConfigIpmbActl 3;
BA_ "CrossOver_InfoCAN" SG_ 1006 FeatConfigIpmbActl 1;
BA_ "U_B562_MY18_Gas_Tx" SG_ 1200 BrkRearPCorrltn_B_Stat 1;
BA_ "U_CX482_CX483_MY20_Hev_Tx" SG_ 1200 HsaTrnAout_Tq_Rq 1;
BA_ "U_CX482_CX483_MY20_Gas_Tx" SG_ 1200 HsaTrnAout_Tq_Rq 1;
BA_ "U_CX482_CX483_MY20_Diesel_Tx" SG_ 1200 HsaTrnAout_Tq_Rq 1;
BA_ "U_U611_U625_MY20_Hev_Tx" SG_ 1200 HsaTrnAout_Tq_Rq 1;
BA_ "U_U611_U625_MY20_Gas_Tx" SG_ 1200 HsaTrnAout_Tq_Rq 1;
BA_ "U_U611_U625_MY20_Diesel_Tx" SG_ 1200 HsaTrnAout_Tq_Rq 1;
BA_ "U_B500_MY18_Diesel_Tx" SG_ 1200 HsaTrnAout_Tq_Rq 1;
BA_ "U_B500_MY18_Gas_Tx" SG_ 1200 HsaTrnAout_Tq_Rq 1;
BA_ "U_C490_MY18_Tx" SG_ 1200 HsaTrnAout_Tq_Rq 1;
BA_ "U_B562_MY18_Gas_Tx" SG_ 1200 HsaTrnAout_Tq_Rq 1;
BA_ "U_C519_MY18_5_Gas_Tx" SG_ 1200 HsaTrnAout_Tq_Rq 1;
BA_ "U_C519_MY18_5_Diesel_Tx" SG_ 1200 HsaTrnAout_Tq_Rq 1;
BA_ "U_B515_MCA_MY17_Gas_Tx" SG_ 1200 HsaTrnAout_Tq_Rq 1;
BA_ "U_B515_MCA_MY17_Diesel_Tx" SG_ 1200 HsaTrnAout_Tq_Rq 1;
BA_ "U_B479_MY17_Diesel_Tx" SG_ 1200 HsaTrnAout_Tq_Rq 1;
BA_ "U_B479_MY17_Gas_Tx" SG_ 1200 HsaTrnAout_Tq_Rq 1;
BA_ "U_B562LC_MY15_Gas_Tx" SG_ 1200 HsaTrnAout_Tq_Rq 1;
BA_ "U_B562LC_MY15_Diesel_Tx" SG_ 1200 HsaTrnAout_Tq_Rq 1;
BA_ "GenSigStartValue" SG_ 1200 HsaTrnAout_Tq_Rq 32768;
BA_ "U_CX482_CX483_MY20_Hev_Tx" SG_ 1200 BrkBstrVac_P_Actl 1;
BA_ "U_CX482_CX483_MY20_Gas_Tx" SG_ 1200 BrkBstrVac_P_Actl 1;
BA_ "U_CX482_CX483_MY20_Diesel_Tx" SG_ 1200 BrkBstrVac_P_Actl 1;
BA_ "U_B500_MY18_Diesel_Tx" SG_ 1200 BrkBstrVac_P_Actl 1;
BA_ "U_B500_MY18_Gas_Tx" SG_ 1200 BrkBstrVac_P_Actl 1;
BA_ "U_C490_MY18_Tx" SG_ 1200 BrkBstrVac_P_Actl 1;
BA_ "U_B562_MY18_Gas_Tx" SG_ 1200 BrkBstrVac_P_Actl 1;
BA_ "U_C519_MY18_5_Gas_Tx" SG_ 1200 BrkBstrVac_P_Actl 1;
BA_ "U_C519_MY18_5_Diesel_Tx" SG_ 1200 BrkBstrVac_P_Actl 1;
BA_ "U_B515_MCA_MY17_Gas_Tx" SG_ 1200 BrkBstrVac_P_Actl 1;
BA_ "U_B515_MCA_MY17_Diesel_Tx" SG_ 1200 BrkBstrVac_P_Actl 1;
BA_ "U_B479_MY17_Diesel_Tx" SG_ 1200 BrkBstrVac_P_Actl 1;
BA_ "U_B479_MY17_Gas_Tx" SG_ 1200 BrkBstrVac_P_Actl 1;
BA_ "U_B562LC_MY15_Gas_Tx" SG_ 1200 BrkBstrVac_P_Actl 1;
BA_ "U_B562LC_MY15_Diesel_Tx" SG_ 1200 BrkBstrVac_P_Actl 1;
BA_ "GenSigStartValue" SG_ 1200 BrkBstrVac_P_Actl 127;
BA_ "U_CX482_CX483_MY20_Hev_Tx" SG_ 1200 YawStabilityIndex 1;
BA_ "U_CX482_CX483_MY20_Gas_Tx" SG_ 1200 YawStabilityIndex 1;
BA_ "U_CX482_CX483_MY20_Diesel_Tx" SG_ 1200 YawStabilityIndex 1;
BA_ "U_U611_U625_MY20_Hev_Tx" SG_ 1200 YawStabilityIndex 1;
BA_ "U_U611_U625_MY20_Gas_Tx" SG_ 1200 YawStabilityIndex 1;
BA_ "U_U611_U625_MY20_Diesel_Tx" SG_ 1200 YawStabilityIndex 1;
BA_ "U_B500_MY18_Diesel_Tx" SG_ 1200 YawStabilityIndex 1;
BA_ "U_B500_MY18_Gas_Tx" SG_ 1200 YawStabilityIndex 1;
BA_ "U_C490_MY18_Tx" SG_ 1200 YawStabilityIndex 1;
BA_ "U_B562_MY18_Gas_Tx" SG_ 1200 YawStabilityIndex 1;
BA_ "U_C519_MY18_5_Gas_Tx" SG_ 1200 YawStabilityIndex 1;
BA_ "U_C519_MY18_5_Diesel_Tx" SG_ 1200 YawStabilityIndex 1;
BA_ "U_B515_MCA_MY17_Gas_Tx" SG_ 1200 YawStabilityIndex 1;
BA_ "U_B515_MCA_MY17_Diesel_Tx" SG_ 1200 YawStabilityIndex 1;
BA_ "U_B479_MY17_Diesel_Tx" SG_ 1200 YawStabilityIndex 1;
BA_ "U_B479_MY17_Gas_Tx" SG_ 1200 YawStabilityIndex 1;
BA_ "U_B562LC_MY15_Gas_Tx" SG_ 1200 YawStabilityIndex 1;
BA_ "U_B562LC_MY15_Diesel_Tx" SG_ 1200 YawStabilityIndex 1;
BA_ "U_CX482_CX483_MY20_Hev_Rx" SG_ 1200 YawStabilityIndex 1;
BA_ "U_CX482_CX483_MY20_Gas_Rx" SG_ 1200 YawStabilityIndex 1;
BA_ "U_CX482_CX483_MY20_Diesel_Rx" SG_ 1200 YawStabilityIndex 1;
BA_ "U_B500_MY18_Diesel_Rx" SG_ 1200 YawStabilityIndex 1;
BA_ "U_B500_MY18_Gas_Rx" SG_ 1200 YawStabilityIndex 1;
BA_ "U_B479_MY17_Diesel_Rx" SG_ 1200 YawStabilityIndex 1;
BA_ "U_B479_MY17_Gas_Rx" SG_ 1200 YawStabilityIndex 1;
BA_ "U_U611_U625_MY20_Phev_Rx" SG_ 1200 YawStabilityIndex 1;
BA_ "U_U611_U625_MY20_Hev_Rx" SG_ 1200 YawStabilityIndex 1;
BA_ "U_U611_U625_MY20_Gas_Rx" SG_ 1200 YawStabilityIndex 1;
BA_ "U_U611_U625_MY20_Diesel_Rx" SG_ 1200 YawStabilityIndex 1;
BA_ "U_C519_MY18_5_Gas_Rx" SG_ 1200 YawStabilityIndex 1;
BA_ "U_C519_MY18_5_Diesel_Rx" SG_ 1200 YawStabilityIndex 1;
BA_ "GenSigStartValue" SG_ 1200 YawStabilityIndex 256;
BA_ "U_CX482_CX483_MY20_Hev_Tx" SG_ 1200 BrkTot_Tq_RqDrv 1;
BA_ "U_CX482_CX483_MY20_Gas_Tx" SG_ 1200 BrkTot_Tq_RqDrv 1;
BA_ "U_CX482_CX483_MY20_Diesel_Tx" SG_ 1200 BrkTot_Tq_RqDrv 1;
BA_ "U_U611_U625_MY20_Hev_Tx" SG_ 1200 BrkTot_Tq_RqDrv 1;
BA_ "U_U611_U625_MY20_Gas_Tx" SG_ 1200 BrkTot_Tq_RqDrv 1;
BA_ "U_U611_U625_MY20_Diesel_Tx" SG_ 1200 BrkTot_Tq_RqDrv 1;
BA_ "U_B500_MY18_Diesel_Tx" SG_ 1200 BrkTot_Tq_RqDrv 1;
BA_ "U_B500_MY18_Gas_Tx" SG_ 1200 BrkTot_Tq_RqDrv 1;
BA_ "U_C490_MY18_Tx" SG_ 1200 BrkTot_Tq_RqDrv 1;
BA_ "U_B562_MY18_Gas_Tx" SG_ 1200 BrkTot_Tq_RqDrv 1;
BA_ "U_C519_MY18_5_Gas_Tx" SG_ 1200 BrkTot_Tq_RqDrv 1;
BA_ "U_C519_MY18_5_Diesel_Tx" SG_ 1200 BrkTot_Tq_RqDrv 1;
BA_ "U_B515_MCA_MY17_Gas_Tx" SG_ 1200 BrkTot_Tq_RqDrv 1;
BA_ "U_B515_MCA_MY17_Diesel_Tx" SG_ 1200 BrkTot_Tq_RqDrv 1;
BA_ "U_B479_MY17_Diesel_Tx" SG_ 1200 BrkTot_Tq_RqDrv 1;
BA_ "U_B479_MY17_Gas_Tx" SG_ 1200 BrkTot_Tq_RqDrv 1;
BA_ "U_B562LC_MY15_Gas_Tx" SG_ 1200 BrkTot_Tq_RqDrv 1;
BA_ "U_B562LC_MY15_Diesel_Tx" SG_ 1200 BrkTot_Tq_RqDrv 1;
BA_ "U_CX482_CX483_MY20_Hev_Rx" SG_ 1200 BrkTot_Tq_RqDrv 1;
BA_ "U_CX482_CX483_MY20_Gas_Rx" SG_ 1200 BrkTot_Tq_RqDrv 1;
BA_ "U_CX482_CX483_MY20_Diesel_Rx" SG_ 1200 BrkTot_Tq_RqDrv 1;
BA_ "U_U611_U625_MY20_Hev_Rx" SG_ 1200 BrkTot_Tq_RqDrv 1;
BA_ "U_U611_U625_MY20_Gas_Rx" SG_ 1200 BrkTot_Tq_RqDrv 1;
BA_ "U_U611_U625_MY20_Diesel_Rx" SG_ 1200 BrkTot_Tq_RqDrv 1;
BA_ "U_C519_MY18_5_Gas_Rx" SG_ 1200 BrkTot_Tq_RqDrv 1;
BA_ "U_C519_MY18_5_Diesel_Rx" SG_ 1200 BrkTot_Tq_RqDrv 1;
BA_ "U_B479_MY17_Diesel_Rx" SG_ 1200 BrkTot_Tq_RqDrv 1;
BA_ "U_B479_MY17_Gas_Rx" SG_ 1200 BrkTot_Tq_RqDrv 1;
BA_ "U_CX482_CX483_MY20_Hev_Tx" SG_ 1200 BrkTotTqRqDrv_No_Cnt 1;
BA_ "U_CX482_CX483_MY20_Gas_Tx" SG_ 1200 BrkTotTqRqDrv_No_Cnt 1;
BA_ "U_CX482_CX483_MY20_Diesel_Tx" SG_ 1200 BrkTotTqRqDrv_No_Cnt 1;
BA_ "U_U611_U625_MY20_Hev_Tx" SG_ 1200 BrkTotTqRqDrv_No_Cnt 1;
BA_ "U_U611_U625_MY20_Gas_Tx" SG_ 1200 BrkTotTqRqDrv_No_Cnt 1;
BA_ "U_U611_U625_MY20_Diesel_Tx" SG_ 1200 BrkTotTqRqDrv_No_Cnt 1;
BA_ "U_B500_MY18_Diesel_Tx" SG_ 1200 BrkTotTqRqDrv_No_Cnt 1;
BA_ "U_B500_MY18_Gas_Tx" SG_ 1200 BrkTotTqRqDrv_No_Cnt 1;
BA_ "U_C490_MY18_Tx" SG_ 1200 BrkTotTqRqDrv_No_Cnt 1;
BA_ "U_B562_MY18_Gas_Tx" SG_ 1200 BrkTotTqRqDrv_No_Cnt 1;
BA_ "U_C519_MY18_5_Gas_Tx" SG_ 1200 BrkTotTqRqDrv_No_Cnt 1;
BA_ "U_C519_MY18_5_Diesel_Tx" SG_ 1200 BrkTotTqRqDrv_No_Cnt 1;
BA_ "U_B515_MCA_MY17_Gas_Tx" SG_ 1200 BrkTotTqRqDrv_No_Cnt 1;
BA_ "U_B515_MCA_MY17_Diesel_Tx" SG_ 1200 BrkTotTqRqDrv_No_Cnt 1;
BA_ "U_B479_MY17_Diesel_Tx" SG_ 1200 BrkTotTqRqDrv_No_Cnt 1;
BA_ "U_B479_MY17_Gas_Tx" SG_ 1200 BrkTotTqRqDrv_No_Cnt 1;
BA_ "U_B562LC_MY15_Gas_Tx" SG_ 1200 BrkTotTqRqDrv_No_Cnt 1;
BA_ "U_B562LC_MY15_Diesel_Tx" SG_ 1200 BrkTotTqRqDrv_No_Cnt 1;
BA_ "U_CX482_CX483_MY20_Hev_Tx" SG_ 1200 BrkTotTqRqDrv_No_Cs 1;
BA_ "U_CX482_CX483_MY20_Gas_Tx" SG_ 1200 BrkTotTqRqDrv_No_Cs 1;
BA_ "U_CX482_CX483_MY20_Diesel_Tx" SG_ 1200 BrkTotTqRqDrv_No_Cs 1;
BA_ "U_U611_U625_MY20_Hev_Tx" SG_ 1200 BrkTotTqRqDrv_No_Cs 1;
BA_ "U_U611_U625_MY20_Gas_Tx" SG_ 1200 BrkTotTqRqDrv_No_Cs 1;
BA_ "U_U611_U625_MY20_Diesel_Tx" SG_ 1200 BrkTotTqRqDrv_No_Cs 1;
BA_ "U_B500_MY18_Diesel_Tx" SG_ 1200 BrkTotTqRqDrv_No_Cs 1;
BA_ "U_B500_MY18_Gas_Tx" SG_ 1200 BrkTotTqRqDrv_No_Cs 1;
BA_ "U_C490_MY18_Tx" SG_ 1200 BrkTotTqRqDrv_No_Cs 1;
BA_ "U_B562_MY18_Gas_Tx" SG_ 1200 BrkTotTqRqDrv_No_Cs 1;
BA_ "U_C519_MY18_5_Gas_Tx" SG_ 1200 BrkTotTqRqDrv_No_Cs 1;
BA_ "U_C519_MY18_5_Diesel_Tx" SG_ 1200 BrkTotTqRqDrv_No_Cs 1;
BA_ "U_B515_MCA_MY17_Gas_Tx" SG_ 1200 BrkTotTqRqDrv_No_Cs 1;
BA_ "U_B515_MCA_MY17_Diesel_Tx" SG_ 1200 BrkTotTqRqDrv_No_Cs 1;
BA_ "U_B479_MY17_Diesel_Tx" SG_ 1200 BrkTotTqRqDrv_No_Cs 1;
BA_ "U_B479_MY17_Gas_Tx" SG_ 1200 BrkTotTqRqDrv_No_Cs 1;
BA_ "U_B562LC_MY15_Gas_Tx" SG_ 1200 BrkTotTqRqDrv_No_Cs 1;
BA_ "U_B562LC_MY15_Diesel_Tx" SG_ 1200 BrkTotTqRqDrv_No_Cs 1;
BA_ "U_CX482_CX483_MY20_Hev_Tx" SG_ 1200 BrkAutoHold_D_Stat 1;
BA_ "U_CX482_CX483_MY20_Gas_Tx" SG_ 1200 BrkAutoHold_D_Stat 1;
BA_ "U_CX482_CX483_MY20_Diesel_Tx" SG_ 1200 BrkAutoHold_D_Stat 1;
BA_ "U_U611_U625_MY20_Gas_Tx" SG_ 1200 BrkAutoHold_D_Stat 1;
BA_ "U_U611_U625_MY20_Diesel_Tx" SG_ 1200 BrkAutoHold_D_Stat 1;
BA_ "U_C519_MY18_5_Gas_Tx" SG_ 1200 BrkAutoHold_D_Stat 1;
BA_ "U_C519_MY18_5_Diesel_Tx" SG_ 1200 BrkAutoHold_D_Stat 1;
BA_ "U_CX482_CX483_MY20_Hev_Tx" SG_ 1200 HsaStat_D_Dsply 1;
BA_ "U_CX482_CX483_MY20_Gas_Tx" SG_ 1200 HsaStat_D_Dsply 1;
BA_ "U_CX482_CX483_MY20_Diesel_Tx" SG_ 1200 HsaStat_D_Dsply 1;
BA_ "U_U611_U625_MY20_Hev_Tx" SG_ 1200 HsaStat_D_Dsply 1;
BA_ "U_U611_U625_MY20_Gas_Tx" SG_ 1200 HsaStat_D_Dsply 1;
BA_ "U_U611_U625_MY20_Diesel_Tx" SG_ 1200 HsaStat_D_Dsply 1;
BA_ "U_B500_MY18_Diesel_Tx" SG_ 1200 HsaStat_D_Dsply 1;
BA_ "U_B500_MY18_Gas_Tx" SG_ 1200 HsaStat_D_Dsply 1;
BA_ "U_C490_MY18_Tx" SG_ 1200 HsaStat_D_Dsply 1;
BA_ "U_B562_MY18_Gas_Tx" SG_ 1200 HsaStat_D_Dsply 1;
BA_ "U_C519_MY18_5_Gas_Tx" SG_ 1200 HsaStat_D_Dsply 1;
BA_ "U_C519_MY18_5_Diesel_Tx" SG_ 1200 HsaStat_D_Dsply 1;
BA_ "U_B515_MCA_MY17_Gas_Tx" SG_ 1200 HsaStat_D_Dsply 1;
BA_ "U_B515_MCA_MY17_Diesel_Tx" SG_ 1200 HsaStat_D_Dsply 1;
BA_ "U_B479_MY17_Diesel_Tx" SG_ 1200 HsaStat_D_Dsply 1;
BA_ "U_B479_MY17_Gas_Tx" SG_ 1200 HsaStat_D_Dsply 1;
BA_ "U_CX482_CX483_MY20_Hev_Tx" SG_ 989 FeatNoHcm_No_Actl 1;
BA_ "U_CX482_CX483_MY20_Gas_Tx" SG_ 989 FeatNoHcm_No_Actl 1;
BA_ "U_CX482_CX483_MY20_Diesel_Tx" SG_ 989 FeatNoHcm_No_Actl 1;
BA_ "U_C519_MY18_5_Gas_Tx" SG_ 989 FeatNoHcm_No_Actl 1;
BA_ "U_C519_MY18_5_Diesel_Tx" SG_ 989 FeatNoHcm_No_Actl 1;
BA_ "GenSigSendType" SG_ 989 FeatNoHcm_No_Actl 3;
BA_ "CrossOver_InfoCAN" SG_ 989 FeatNoHcm_No_Actl 1;
BA_ "U_CX482_CX483_MY20_Hev_Tx" SG_ 989 FeatConfigHcmActl 1;
BA_ "U_CX482_CX483_MY20_Gas_Tx" SG_ 989 FeatConfigHcmActl 1;
BA_ "U_CX482_CX483_MY20_Diesel_Tx" SG_ 989 FeatConfigHcmActl 1;
BA_ "U_C519_MY18_5_Gas_Tx" SG_ 989 FeatConfigHcmActl 1;
BA_ "U_C519_MY18_5_Diesel_Tx" SG_ 989 FeatConfigHcmActl 1;
BA_ "GenSigSendType" SG_ 989 FeatConfigHcmActl 3;
BA_ "CrossOver_InfoCAN" SG_ 989 FeatConfigHcmActl 1;
BA_ "U_CX482_CX483_MY20_Hev_Tx" SG_ 1852 TesterPhysicalResHCM 1;
BA_ "U_CX482_CX483_MY20_Gas_Tx" SG_ 1852 TesterPhysicalResHCM 1;
BA_ "U_CX482_CX483_MY20_Diesel_Tx" SG_ 1852 TesterPhysicalResHCM 1;
BA_ "U_C519_MY18_5_Gas_Tx" SG_ 1852 TesterPhysicalResHCM 1;
BA_ "U_C519_MY18_5_Diesel_Tx" SG_ 1852 TesterPhysicalResHCM 1;
BA_ "GenSigSendType" SG_ 1852 TesterPhysicalResHCM 3;
BA_ "U_CX482_CX483_MY20_Hev_Rx" SG_ 1844 TesterPhysicalReqHCM 1;
BA_ "U_CX482_CX483_MY20_Gas_Rx" SG_ 1844 TesterPhysicalReqHCM 1;
BA_ "U_CX482_CX483_MY20_Diesel_Rx" SG_ 1844 TesterPhysicalReqHCM 1;
BA_ "U_U611_U625_MY20_Hev_Rx" SG_ 1844 TesterPhysicalReqHCM 1;
BA_ "U_U611_U625_MY20_Gas_Rx" SG_ 1844 TesterPhysicalReqHCM 1;
BA_ "U_U611_U625_MY20_Diesel_Rx" SG_ 1844 TesterPhysicalReqHCM 1;
BA_ "U_C519_MY18_5_Gas_Rx" SG_ 1844 TesterPhysicalReqHCM 1;
BA_ "U_C519_MY18_5_Diesel_Rx" SG_ 1844 TesterPhysicalReqHCM 1;
BA_ "GenSigSendType" SG_ 1844 TesterPhysicalReqHCM 3;
BA_ "U_CX482_CX483_MY20_Hev_Tx" SG_ 1102 SelDrvMdePos12_D_Stat 1;
BA_ "U_CX482_CX483_MY20_Gas_Tx" SG_ 1102 SelDrvMdePos12_D_Stat 1;
BA_ "U_CX482_CX483_MY20_Diesel_Tx" SG_ 1102 SelDrvMdePos12_D_Stat 1;
BA_ "U_U611_U625_MY20_Hev_Tx" SG_ 1102 SelDrvMdePos12_D_Stat 1;
BA_ "U_U611_U625_MY20_Gas_Tx" SG_ 1102 SelDrvMdePos12_D_Stat 1;
BA_ "U_U611_U625_MY20_Diesel_Tx" SG_ 1102 SelDrvMdePos12_D_Stat 1;
BA_ "U_C519_MY18_5_Gas_Tx" SG_ 1102 SelDrvMdePos12_D_Stat 1;
BA_ "U_C519_MY18_5_Diesel_Tx" SG_ 1102 SelDrvMdePos12_D_Stat 1;
BA_ "GenSigSendType" SG_ 1102 SelDrvMdePos12_D_Stat 3;
BA_ "GenSigStartValue" SG_ 1102 SelDrvMdePos12_D_Stat 31;
BA_ "U_CX482_CX483_MY20_Hev_Tx" SG_ 1102 SelDrvMdePos11_D_Stat 1;
BA_ "U_CX482_CX483_MY20_Gas_Tx" SG_ 1102 SelDrvMdePos11_D_Stat 1;
BA_ "U_CX482_CX483_MY20_Diesel_Tx" SG_ 1102 SelDrvMdePos11_D_Stat 1;
BA_ "U_U611_U625_MY20_Hev_Tx" SG_ 1102 SelDrvMdePos11_D_Stat 1;
BA_ "U_U611_U625_MY20_Gas_Tx" SG_ 1102 SelDrvMdePos11_D_Stat 1;
BA_ "U_U611_U625_MY20_Diesel_Tx" SG_ 1102 SelDrvMdePos11_D_Stat 1;
BA_ "U_C519_MY18_5_Gas_Tx" SG_ 1102 SelDrvMdePos11_D_Stat 1;
BA_ "U_C519_MY18_5_Diesel_Tx" SG_ 1102 SelDrvMdePos11_D_Stat 1;
BA_ "GenSigSendType" SG_ 1102 SelDrvMdePos11_D_Stat 3;
BA_ "GenSigStartValue" SG_ 1102 SelDrvMdePos11_D_Stat 31;
BA_ "U_CX482_CX483_MY20_Hev_Tx" SG_ 1102 SelDrvMdePos10_D_Stat 1;
BA_ "U_CX482_CX483_MY20_Gas_Tx" SG_ 1102 SelDrvMdePos10_D_Stat 1;
BA_ "U_CX482_CX483_MY20_Diesel_Tx" SG_ 1102 SelDrvMdePos10_D_Stat 1;
BA_ "U_U611_U625_MY20_Hev_Tx" SG_ 1102 SelDrvMdePos10_D_Stat 1;
BA_ "U_U611_U625_MY20_Gas_Tx" SG_ 1102 SelDrvMdePos10_D_Stat 1;
BA_ "U_U611_U625_MY20_Diesel_Tx" SG_ 1102 SelDrvMdePos10_D_Stat 1;
BA_ "U_C519_MY18_5_Gas_Tx" SG_ 1102 SelDrvMdePos10_D_Stat 1;
BA_ "U_C519_MY18_5_Diesel_Tx" SG_ 1102 SelDrvMdePos10_D_Stat 1;
BA_ "GenSigSendType" SG_ 1102 SelDrvMdePos10_D_Stat 3;
BA_ "GenSigStartValue" SG_ 1102 SelDrvMdePos10_D_Stat 31;
BA_ "U_CX482_CX483_MY20_Hev_Tx" SG_ 1102 SelDrvMdePos09_D_Stat 1;
BA_ "U_CX482_CX483_MY20_Gas_Tx" SG_ 1102 SelDrvMdePos09_D_Stat 1;
BA_ "U_CX482_CX483_MY20_Diesel_Tx" SG_ 1102 SelDrvMdePos09_D_Stat 1;
BA_ "U_U611_U625_MY20_Hev_Tx" SG_ 1102 SelDrvMdePos09_D_Stat 1;
BA_ "U_U611_U625_MY20_Gas_Tx" SG_ 1102 SelDrvMdePos09_D_Stat 1;
BA_ "U_U611_U625_MY20_Diesel_Tx" SG_ 1102 SelDrvMdePos09_D_Stat 1;
BA_ "U_C519_MY18_5_Gas_Tx" SG_ 1102 SelDrvMdePos09_D_Stat 1;
BA_ "U_C519_MY18_5_Diesel_Tx" SG_ 1102 SelDrvMdePos09_D_Stat 1;
BA_ "GenSigSendType" SG_ 1102 SelDrvMdePos09_D_Stat 3;
BA_ "GenSigStartValue" SG_ 1102 SelDrvMdePos09_D_Stat 31;
BA_ "U_CX482_CX483_MY20_Hev_Tx" SG_ 1102 SelDrvMdePos08_D_Stat 1;
BA_ "U_CX482_CX483_MY20_Gas_Tx" SG_ 1102 SelDrvMdePos08_D_Stat 1;
BA_ "U_CX482_CX483_MY20_Diesel_Tx" SG_ 1102 SelDrvMdePos08_D_Stat 1;
BA_ "U_U611_U625_MY20_Hev_Tx" SG_ 1102 SelDrvMdePos08_D_Stat 1;
BA_ "U_U611_U625_MY20_Gas_Tx" SG_ 1102 SelDrvMdePos08_D_Stat 1;
BA_ "U_U611_U625_MY20_Diesel_Tx" SG_ 1102 SelDrvMdePos08_D_Stat 1;
BA_ "U_C519_MY18_5_Gas_Tx" SG_ 1102 SelDrvMdePos08_D_Stat 1;
BA_ "U_C519_MY18_5_Diesel_Tx" SG_ 1102 SelDrvMdePos08_D_Stat 1;
BA_ "GenSigSendType" SG_ 1102 SelDrvMdePos08_D_Stat 3;
BA_ "GenSigStartValue" SG_ 1102 SelDrvMdePos08_D_Stat 31;
BA_ "U_CX482_CX483_MY20_Hev_Tx" SG_ 1102 SelDrvMdePos07_D_Stat 1;
BA_ "U_CX482_CX483_MY20_Gas_Tx" SG_ 1102 SelDrvMdePos07_D_Stat 1;
BA_ "U_CX482_CX483_MY20_Diesel_Tx" SG_ 1102 SelDrvMdePos07_D_Stat 1;
BA_ "U_U611_U625_MY20_Hev_Tx" SG_ 1102 SelDrvMdePos07_D_Stat 1;
BA_ "U_U611_U625_MY20_Gas_Tx" SG_ 1102 SelDrvMdePos07_D_Stat 1;
BA_ "U_U611_U625_MY20_Diesel_Tx" SG_ 1102 SelDrvMdePos07_D_Stat 1;
BA_ "U_C519_MY18_5_Gas_Tx" SG_ 1102 SelDrvMdePos07_D_Stat 1;
BA_ "U_C519_MY18_5_Diesel_Tx" SG_ 1102 SelDrvMdePos07_D_Stat 1;
BA_ "GenSigSendType" SG_ 1102 SelDrvMdePos07_D_Stat 3;
BA_ "GenSigStartValue" SG_ 1102 SelDrvMdePos07_D_Stat 31;
BA_ "U_CX482_CX483_MY20_Hev_Tx" SG_ 1102 SelDrvMdePos06_D_Stat 1;
BA_ "U_CX482_CX483_MY20_Gas_Tx" SG_ 1102 SelDrvMdePos06_D_Stat 1;
BA_ "U_CX482_CX483_MY20_Diesel_Tx" SG_ 1102 SelDrvMdePos06_D_Stat 1;
BA_ "U_U611_U625_MY20_Hev_Tx" SG_ 1102 SelDrvMdePos06_D_Stat 1;
BA_ "U_U611_U625_MY20_Gas_Tx" SG_ 1102 SelDrvMdePos06_D_Stat 1;
BA_ "U_U611_U625_MY20_Diesel_Tx" SG_ 1102 SelDrvMdePos06_D_Stat 1;
BA_ "U_C519_MY18_5_Gas_Tx" SG_ 1102 SelDrvMdePos06_D_Stat 1;
BA_ "U_C519_MY18_5_Diesel_Tx" SG_ 1102 SelDrvMdePos06_D_Stat 1;
BA_ "GenSigSendType" SG_ 1102 SelDrvMdePos06_D_Stat 3;
BA_ "GenSigStartValue" SG_ 1102 SelDrvMdePos06_D_Stat 31;
BA_ "U_CX482_CX483_MY20_Hev_Tx" SG_ 1102 SelDrvMdePos05_D_Stat 1;
BA_ "U_CX482_CX483_MY20_Gas_Tx" SG_ 1102 SelDrvMdePos05_D_Stat 1;
BA_ "U_CX482_CX483_MY20_Diesel_Tx" SG_ 1102 SelDrvMdePos05_D_Stat 1;
BA_ "U_U611_U625_MY20_Hev_Tx" SG_ 1102 SelDrvMdePos05_D_Stat 1;
BA_ "U_U611_U625_MY20_Gas_Tx" SG_ 1102 SelDrvMdePos05_D_Stat 1;
BA_ "U_U611_U625_MY20_Diesel_Tx" SG_ 1102 SelDrvMdePos05_D_Stat 1;
BA_ "U_C519_MY18_5_Gas_Tx" SG_ 1102 SelDrvMdePos05_D_Stat 1;
BA_ "U_C519_MY18_5_Diesel_Tx" SG_ 1102 SelDrvMdePos05_D_Stat 1;
BA_ "GenSigSendType" SG_ 1102 SelDrvMdePos05_D_Stat 3;
BA_ "GenSigStartValue" SG_ 1102 SelDrvMdePos05_D_Stat 31;
BA_ "U_CX482_CX483_MY20_Hev_Tx" SG_ 1102 SelDrvMdePos04_D_Stat 1;
BA_ "U_CX482_CX483_MY20_Gas_Tx" SG_ 1102 SelDrvMdePos04_D_Stat 1;
BA_ "U_CX482_CX483_MY20_Diesel_Tx" SG_ 1102 SelDrvMdePos04_D_Stat 1;
BA_ "U_U611_U625_MY20_Hev_Tx" SG_ 1102 SelDrvMdePos04_D_Stat 1;
BA_ "U_U611_U625_MY20_Gas_Tx" SG_ 1102 SelDrvMdePos04_D_Stat 1;
BA_ "U_U611_U625_MY20_Diesel_Tx" SG_ 1102 SelDrvMdePos04_D_Stat 1;
BA_ "U_C519_MY18_5_Gas_Tx" SG_ 1102 SelDrvMdePos04_D_Stat 1;
BA_ "U_C519_MY18_5_Diesel_Tx" SG_ 1102 SelDrvMdePos04_D_Stat 1;
BA_ "GenSigSendType" SG_ 1102 SelDrvMdePos04_D_Stat 3;
BA_ "GenSigStartValue" SG_ 1102 SelDrvMdePos04_D_Stat 31;
BA_ "U_CX482_CX483_MY20_Hev_Tx" SG_ 1102 SelDrvMdePos03_D_Stat 1;
BA_ "U_CX482_CX483_MY20_Gas_Tx" SG_ 1102 SelDrvMdePos03_D_Stat 1;
BA_ "U_CX482_CX483_MY20_Diesel_Tx" SG_ 1102 SelDrvMdePos03_D_Stat 1;
BA_ "U_U611_U625_MY20_Hev_Tx" SG_ 1102 SelDrvMdePos03_D_Stat 1;
BA_ "U_U611_U625_MY20_Gas_Tx" SG_ 1102 SelDrvMdePos03_D_Stat 1;
BA_ "U_U611_U625_MY20_Diesel_Tx" SG_ 1102 SelDrvMdePos03_D_Stat 1;
BA_ "U_C519_MY18_5_Gas_Tx" SG_ 1102 SelDrvMdePos03_D_Stat 1;
BA_ "U_C519_MY18_5_Diesel_Tx" SG_ 1102 SelDrvMdePos03_D_Stat 1;
BA_ "GenSigSendType" SG_ 1102 SelDrvMdePos03_D_Stat 3;
BA_ "GenSigStartValue" SG_ 1102 SelDrvMdePos03_D_Stat 31;
BA_ "U_CX482_CX483_MY20_Hev_Tx" SG_ 1102 SelDrvMdePos02_D_Stat 1;
BA_ "U_CX482_CX483_MY20_Gas_Tx" SG_ 1102 SelDrvMdePos02_D_Stat 1;
BA_ "U_CX482_CX483_MY20_Diesel_Tx" SG_ 1102 SelDrvMdePos02_D_Stat 1;
BA_ "U_U611_U625_MY20_Hev_Tx" SG_ 1102 SelDrvMdePos02_D_Stat 1;
BA_ "U_U611_U625_MY20_Gas_Tx" SG_ 1102 SelDrvMdePos02_D_Stat 1;
BA_ "U_U611_U625_MY20_Diesel_Tx" SG_ 1102 SelDrvMdePos02_D_Stat 1;
BA_ "U_C519_MY18_5_Gas_Tx" SG_ 1102 SelDrvMdePos02_D_Stat 1;
BA_ "U_C519_MY18_5_Diesel_Tx" SG_ 1102 SelDrvMdePos02_D_Stat 1;
BA_ "GenSigSendType" SG_ 1102 SelDrvMdePos02_D_Stat 3;
BA_ "GenSigStartValue" SG_ 1102 SelDrvMdePos02_D_Stat 31;
BA_ "U_CX482_CX483_MY20_Hev_Tx" SG_ 1102 SelDrvMdePos01_D_Stat 1;
BA_ "U_CX482_CX483_MY20_Gas_Tx" SG_ 1102 SelDrvMdePos01_D_Stat 1;
BA_ "U_CX482_CX483_MY20_Diesel_Tx" SG_ 1102 SelDrvMdePos01_D_Stat 1;
BA_ "U_U611_U625_MY20_Hev_Tx" SG_ 1102 SelDrvMdePos01_D_Stat 1;
BA_ "U_U611_U625_MY20_Gas_Tx" SG_ 1102 SelDrvMdePos01_D_Stat 1;
BA_ "U_U611_U625_MY20_Diesel_Tx" SG_ 1102 SelDrvMdePos01_D_Stat 1;
BA_ "U_C519_MY18_5_Gas_Tx" SG_ 1102 SelDrvMdePos01_D_Stat 1;
BA_ "U_C519_MY18_5_Diesel_Tx" SG_ 1102 SelDrvMdePos01_D_Stat 1;
BA_ "GenSigSendType" SG_ 1102 SelDrvMdePos01_D_Stat 3;
BA_ "GenSigStartValue" SG_ 1102 SelDrvMdePos01_D_Stat 31;
BA_ "U_CX482_CX483_MY20_Hev_Tx" SG_ 962 AdbMde3_D_Rq 1;
BA_ "U_CX482_CX483_MY20_Gas_Tx" SG_ 962 AdbMde3_D_Rq 1;
BA_ "U_CX482_CX483_MY20_Diesel_Tx" SG_ 962 AdbMde3_D_Rq 1;
BA_ "U_U611_U625_MY20_Hev_Tx" SG_ 962 AdbMde3_D_Rq 1;
BA_ "U_U611_U625_MY20_Gas_Tx" SG_ 962 AdbMde3_D_Rq 1;
BA_ "U_U611_U625_MY20_Diesel_Tx" SG_ 962 AdbMde3_D_Rq 1;
BA_ "U_C519_MY18_5_Gas_Tx" SG_ 962 AdbMde3_D_Rq 1;
BA_ "U_C519_MY18_5_Diesel_Tx" SG_ 962 AdbMde3_D_Rq 1;
BA_ "U_CX482_CX483_MY20_Hev_Rx" SG_ 962 AdbMde3_D_Rq 1;
BA_ "U_CX482_CX483_MY20_Gas_Rx" SG_ 962 AdbMde3_D_Rq 1;
BA_ "U_CX482_CX483_MY20_Diesel_Rx" SG_ 962 AdbMde3_D_Rq 1;
BA_ "U_C519_MY18_5_Gas_Rx" SG_ 962 AdbMde3_D_Rq 1;
BA_ "U_C519_MY18_5_Diesel_Rx" SG_ 962 AdbMde3_D_Rq 1;
BA_ "GenSigSendType" SG_ 962 AdbMde3_D_Rq 3;
BA_ "U_CX482_CX483_MY20_Hev_Tx" SG_ 962 AdbIntns3_D_Rq 1;
BA_ "U_CX482_CX483_MY20_Gas_Tx" SG_ 962 AdbIntns3_D_Rq 1;
BA_ "U_CX482_CX483_MY20_Diesel_Tx" SG_ 962 AdbIntns3_D_Rq 1;
BA_ "U_U611_U625_MY20_Hev_Tx" SG_ 962 AdbIntns3_D_Rq 1;
BA_ "U_U611_U625_MY20_Gas_Tx" SG_ 962 AdbIntns3_D_Rq 1;
BA_ "U_U611_U625_MY20_Diesel_Tx" SG_ 962 AdbIntns3_D_Rq 1;
BA_ "U_C519_MY18_5_Gas_Tx" SG_ 962 AdbIntns3_D_Rq 1;
BA_ "U_C519_MY18_5_Diesel_Tx" SG_ 962 AdbIntns3_D_Rq 1;
BA_ "U_CX482_CX483_MY20_Hev_Rx" SG_ 962 AdbIntns3_D_Rq 1;
BA_ "U_CX482_CX483_MY20_Gas_Rx" SG_ 962 AdbIntns3_D_Rq 1;
BA_ "U_CX482_CX483_MY20_Diesel_Rx" SG_ 962 AdbIntns3_D_Rq 1;
BA_ "U_C519_MY18_5_Gas_Rx" SG_ 962 AdbIntns3_D_Rq 1;
BA_ "U_C519_MY18_5_Diesel_Rx" SG_ 962 AdbIntns3_D_Rq 1;
BA_ "GenSigSendType" SG_ 962 AdbIntns3_D_Rq 3;
BA_ "U_CX482_CX483_MY20_Hev_Tx" SG_ 962 AdbBrdr3Up_An_Rq 1;
BA_ "U_CX482_CX483_MY20_Gas_Tx" SG_ 962 AdbBrdr3Up_An_Rq 1;
BA_ "U_CX482_CX483_MY20_Diesel_Tx" SG_ 962 AdbBrdr3Up_An_Rq 1;
BA_ "U_U611_U625_MY20_Hev_Tx" SG_ 962 AdbBrdr3Up_An_Rq 1;
BA_ "U_U611_U625_MY20_Gas_Tx" SG_ 962 AdbBrdr3Up_An_Rq 1;
BA_ "U_U611_U625_MY20_Diesel_Tx" SG_ 962 AdbBrdr3Up_An_Rq 1;
BA_ "U_C519_MY18_5_Gas_Tx" SG_ 962 AdbBrdr3Up_An_Rq 1;
BA_ "U_C519_MY18_5_Diesel_Tx" SG_ 962 AdbBrdr3Up_An_Rq 1;
BA_ "U_CX482_CX483_MY20_Hev_Rx" SG_ 962 AdbBrdr3Up_An_Rq 1;
BA_ "U_CX482_CX483_MY20_Gas_Rx" SG_ 962 AdbBrdr3Up_An_Rq 1;
BA_ "U_CX482_CX483_MY20_Diesel_Rx" SG_ 962 AdbBrdr3Up_An_Rq 1;
BA_ "U_C519_MY18_5_Gas_Rx" SG_ 962 AdbBrdr3Up_An_Rq 1;
BA_ "U_C519_MY18_5_Diesel_Rx" SG_ 962 AdbBrdr3Up_An_Rq 1;
BA_ "GenSigStartValue" SG_ 962 AdbBrdr3Up_An_Rq 400;
BA_ "U_CX482_CX483_MY20_Hev_Tx" SG_ 962 AdbBrdr3Right_An_Rq 1;
BA_ "U_CX482_CX483_MY20_Gas_Tx" SG_ 962 AdbBrdr3Right_An_Rq 1;
BA_ "U_CX482_CX483_MY20_Diesel_Tx" SG_ 962 AdbBrdr3Right_An_Rq 1;
BA_ "U_U611_U625_MY20_Hev_Tx" SG_ 962 AdbBrdr3Right_An_Rq 1;
BA_ "U_U611_U625_MY20_Gas_Tx" SG_ 962 AdbBrdr3Right_An_Rq 1;
BA_ "U_U611_U625_MY20_Diesel_Tx" SG_ 962 AdbBrdr3Right_An_Rq 1;
BA_ "U_C519_MY18_5_Gas_Tx" SG_ 962 AdbBrdr3Right_An_Rq 1;
BA_ "U_C519_MY18_5_Diesel_Tx" SG_ 962 AdbBrdr3Right_An_Rq 1;
BA_ "U_CX482_CX483_MY20_Hev_Rx" SG_ 962 AdbBrdr3Right_An_Rq 1;
BA_ "U_CX482_CX483_MY20_Gas_Rx" SG_ 962 AdbBrdr3Right_An_Rq 1;
BA_ "U_CX482_CX483_MY20_Diesel_Rx" SG_ 962 AdbBrdr3Right_An_Rq 1;
BA_ "U_C519_MY18_5_Gas_Rx" SG_ 962 AdbBrdr3Right_An_Rq 1;
BA_ "U_C519_MY18_5_Diesel_Rx" SG_ 962 AdbBrdr3Right_An_Rq 1;
BA_ "GenSigStartValue" SG_ 962 AdbBrdr3Right_An_Rq 1000;
BA_ "U_CX482_CX483_MY20_Hev_Tx" SG_ 962 AdbBrdr3Low_An_Rq 1;
BA_ "U_CX482_CX483_MY20_Gas_Tx" SG_ 962 AdbBrdr3Low_An_Rq 1;
BA_ "U_CX482_CX483_MY20_Diesel_Tx" SG_ 962 AdbBrdr3Low_An_Rq 1;
BA_ "U_U611_U625_MY20_Hev_Tx" SG_ 962 AdbBrdr3Low_An_Rq 1;
BA_ "U_U611_U625_MY20_Gas_Tx" SG_ 962 AdbBrdr3Low_An_Rq 1;
BA_ "U_U611_U625_MY20_Diesel_Tx" SG_ 962 AdbBrdr3Low_An_Rq 1;
BA_ "U_C519_MY18_5_Gas_Tx" SG_ 962 AdbBrdr3Low_An_Rq 1;
BA_ "U_C519_MY18_5_Diesel_Tx" SG_ 962 AdbBrdr3Low_An_Rq 1;
BA_ "U_CX482_CX483_MY20_Hev_Rx" SG_ 962 AdbBrdr3Low_An_Rq 1;
BA_ "U_CX482_CX483_MY20_Gas_Rx" SG_ 962 AdbBrdr3Low_An_Rq 1;
BA_ "U_CX482_CX483_MY20_Diesel_Rx" SG_ 962 AdbBrdr3Low_An_Rq 1;
BA_ "U_C519_MY18_5_Gas_Rx" SG_ 962 AdbBrdr3Low_An_Rq 1;
BA_ "U_C519_MY18_5_Diesel_Rx" SG_ 962 AdbBrdr3Low_An_Rq 1;
BA_ "GenSigStartValue" SG_ 962 AdbBrdr3Low_An_Rq 400;
BA_ "U_CX482_CX483_MY20_Hev_Tx" SG_ 962 AdbBrdr3Left_An_Rq 1;
BA_ "U_CX482_CX483_MY20_Gas_Tx" SG_ 962 AdbBrdr3Left_An_Rq 1;
BA_ "U_CX482_CX483_MY20_Diesel_Tx" SG_ 962 AdbBrdr3Left_An_Rq 1;
BA_ "U_U611_U625_MY20_Hev_Tx" SG_ 962 AdbBrdr3Left_An_Rq 1;
BA_ "U_U611_U625_MY20_Gas_Tx" SG_ 962 AdbBrdr3Left_An_Rq 1;
BA_ "U_U611_U625_MY20_Diesel_Tx" SG_ 962 AdbBrdr3Left_An_Rq 1;
BA_ "U_C519_MY18_5_Gas_Tx" SG_ 962 AdbBrdr3Left_An_Rq 1;
BA_ "U_C519_MY18_5_Diesel_Tx" SG_ 962 AdbBrdr3Left_An_Rq 1;
BA_ "U_CX482_CX483_MY20_Hev_Rx" SG_ 962 AdbBrdr3Left_An_Rq 1;
BA_ "U_CX482_CX483_MY20_Gas_Rx" SG_ 962 AdbBrdr3Left_An_Rq 1;
BA_ "U_CX482_CX483_MY20_Diesel_Rx" SG_ 962 AdbBrdr3Left_An_Rq 1;
BA_ "U_C519_MY18_5_Gas_Rx" SG_ 962 AdbBrdr3Left_An_Rq 1;
BA_ "U_C519_MY18_5_Diesel_Rx" SG_ 962 AdbBrdr3Left_An_Rq 1;
BA_ "GenSigStartValue" SG_ 962 AdbBrdr3Left_An_Rq 1000;
BA_ "U_CX482_CX483_MY20_Hev_Tx" SG_ 962 AdbBrdr3CritRigh_T_Stat 1;
BA_ "U_CX482_CX483_MY20_Gas_Tx" SG_ 962 AdbBrdr3CritRigh_T_Stat 1;
BA_ "U_CX482_CX483_MY20_Diesel_Tx" SG_ 962 AdbBrdr3CritRigh_T_Stat 1;
BA_ "U_U611_U625_MY20_Hev_Tx" SG_ 962 AdbBrdr3CritRigh_T_Stat 1;
BA_ "U_U611_U625_MY20_Gas_Tx" SG_ 962 AdbBrdr3CritRigh_T_Stat 1;
BA_ "U_U611_U625_MY20_Diesel_Tx" SG_ 962 AdbBrdr3CritRigh_T_Stat 1;
BA_ "U_C519_MY18_5_Gas_Tx" SG_ 962 AdbBrdr3CritRigh_T_Stat 1;
BA_ "U_C519_MY18_5_Diesel_Tx" SG_ 962 AdbBrdr3CritRigh_T_Stat 1;
BA_ "U_CX482_CX483_MY20_Hev_Rx" SG_ 962 AdbBrdr3CritRigh_T_Stat 1;
BA_ "U_CX482_CX483_MY20_Gas_Rx" SG_ 962 AdbBrdr3CritRigh_T_Stat 1;
BA_ "U_CX482_CX483_MY20_Diesel_Rx" SG_ 962 AdbBrdr3CritRigh_T_Stat 1;
BA_ "U_C519_MY18_5_Gas_Rx" SG_ 962 AdbBrdr3CritRigh_T_Stat 1;
BA_ "U_C519_MY18_5_Diesel_Rx" SG_ 962 AdbBrdr3CritRigh_T_Stat 1;
BA_ "U_CX482_CX483_MY20_Hev_Tx" SG_ 962 AdbBrdr3CritLeft_T_Stat 1;
BA_ "U_CX482_CX483_MY20_Gas_Tx" SG_ 962 AdbBrdr3CritLeft_T_Stat 1;
BA_ "U_CX482_CX483_MY20_Diesel_Tx" SG_ 962 AdbBrdr3CritLeft_T_Stat 1;
BA_ "U_U611_U625_MY20_Hev_Tx" SG_ 962 AdbBrdr3CritLeft_T_Stat 1;
BA_ "U_U611_U625_MY20_Gas_Tx" SG_ 962 AdbBrdr3CritLeft_T_Stat 1;
BA_ "U_U611_U625_MY20_Diesel_Tx" SG_ 962 AdbBrdr3CritLeft_T_Stat 1;
BA_ "U_C519_MY18_5_Gas_Tx" SG_ 962 AdbBrdr3CritLeft_T_Stat 1;
BA_ "U_C519_MY18_5_Diesel_Tx" SG_ 962 AdbBrdr3CritLeft_T_Stat 1;
BA_ "U_CX482_CX483_MY20_Hev_Rx" SG_ 962 AdbBrdr3CritLeft_T_Stat 1;
BA_ "U_CX482_CX483_MY20_Gas_Rx" SG_ 962 AdbBrdr3CritLeft_T_Stat 1;
BA_ "U_CX482_CX483_MY20_Diesel_Rx" SG_ 962 AdbBrdr3CritLeft_T_Stat 1;
BA_ "U_C519_MY18_5_Gas_Rx" SG_ 962 AdbBrdr3CritLeft_T_Stat 1;
BA_ "U_C519_MY18_5_Diesel_Rx" SG_ 962 AdbBrdr3CritLeft_T_Stat 1;
BA_ "U_CX482_CX483_MY20_Hev_Tx" SG_ 961 AdbMde2_D_Rq 1;
BA_ "U_CX482_CX483_MY20_Gas_Tx" SG_ 961 AdbMde2_D_Rq 1;
BA_ "U_CX482_CX483_MY20_Diesel_Tx" SG_ 961 AdbMde2_D_Rq 1;
BA_ "U_U611_U625_MY20_Hev_Tx" SG_ 961 AdbMde2_D_Rq 1;
BA_ "U_U611_U625_MY20_Gas_Tx" SG_ 961 AdbMde2_D_Rq 1;
BA_ "U_U611_U625_MY20_Diesel_Tx" SG_ 961 AdbMde2_D_Rq 1;
BA_ "U_C519_MY18_5_Gas_Tx" SG_ 961 AdbMde2_D_Rq 1;
BA_ "U_C519_MY18_5_Diesel_Tx" SG_ 961 AdbMde2_D_Rq 1;
BA_ "U_CX482_CX483_MY20_Hev_Rx" SG_ 961 AdbMde2_D_Rq 1;
BA_ "U_CX482_CX483_MY20_Gas_Rx" SG_ 961 AdbMde2_D_Rq 1;
BA_ "U_CX482_CX483_MY20_Diesel_Rx" SG_ 961 AdbMde2_D_Rq 1;
BA_ "U_C519_MY18_5_Gas_Rx" SG_ 961 AdbMde2_D_Rq 1;
BA_ "U_C519_MY18_5_Diesel_Rx" SG_ 961 AdbMde2_D_Rq 1;
BA_ "GenSigSendType" SG_ 961 AdbMde2_D_Rq 3;
BA_ "U_CX482_CX483_MY20_Hev_Tx" SG_ 961 AdbIntns2_D_Rq 1;
BA_ "U_CX482_CX483_MY20_Gas_Tx" SG_ 961 AdbIntns2_D_Rq 1;
BA_ "U_CX482_CX483_MY20_Diesel_Tx" SG_ 961 AdbIntns2_D_Rq 1;
BA_ "U_U611_U625_MY20_Hev_Tx" SG_ 961 AdbIntns2_D_Rq 1;
BA_ "U_U611_U625_MY20_Gas_Tx" SG_ 961 AdbIntns2_D_Rq 1;
BA_ "U_U611_U625_MY20_Diesel_Tx" SG_ 961 AdbIntns2_D_Rq 1;
BA_ "U_C519_MY18_5_Gas_Tx" SG_ 961 AdbIntns2_D_Rq 1;
BA_ "U_C519_MY18_5_Diesel_Tx" SG_ 961 AdbIntns2_D_Rq 1;
BA_ "U_CX482_CX483_MY20_Hev_Rx" SG_ 961 AdbIntns2_D_Rq 1;
BA_ "U_CX482_CX483_MY20_Gas_Rx" SG_ 961 AdbIntns2_D_Rq 1;
BA_ "U_CX482_CX483_MY20_Diesel_Rx" SG_ 961 AdbIntns2_D_Rq 1;
BA_ "U_C519_MY18_5_Gas_Rx" SG_ 961 AdbIntns2_D_Rq 1;
BA_ "U_C519_MY18_5_Diesel_Rx" SG_ 961 AdbIntns2_D_Rq 1;
BA_ "GenSigSendType" SG_ 961 AdbIntns2_D_Rq 3;
BA_ "U_CX482_CX483_MY20_Hev_Tx" SG_ 961 AdbBrdr2Up_An_Rq 1;
BA_ "U_CX482_CX483_MY20_Gas_Tx" SG_ 961 AdbBrdr2Up_An_Rq 1;
BA_ "U_CX482_CX483_MY20_Diesel_Tx" SG_ 961 AdbBrdr2Up_An_Rq 1;
BA_ "U_U611_U625_MY20_Hev_Tx" SG_ 961 AdbBrdr2Up_An_Rq 1;
BA_ "U_U611_U625_MY20_Gas_Tx" SG_ 961 AdbBrdr2Up_An_Rq 1;
BA_ "U_U611_U625_MY20_Diesel_Tx" SG_ 961 AdbBrdr2Up_An_Rq 1;
BA_ "U_C519_MY18_5_Gas_Tx" SG_ 961 AdbBrdr2Up_An_Rq 1;
BA_ "U_C519_MY18_5_Diesel_Tx" SG_ 961 AdbBrdr2Up_An_Rq 1;
BA_ "U_CX482_CX483_MY20_Hev_Rx" SG_ 961 AdbBrdr2Up_An_Rq 1;
BA_ "U_CX482_CX483_MY20_Gas_Rx" SG_ 961 AdbBrdr2Up_An_Rq 1;
BA_ "U_CX482_CX483_MY20_Diesel_Rx" SG_ 961 AdbBrdr2Up_An_Rq 1;
BA_ "U_C519_MY18_5_Gas_Rx" SG_ 961 AdbBrdr2Up_An_Rq 1;
BA_ "U_C519_MY18_5_Diesel_Rx" SG_ 961 AdbBrdr2Up_An_Rq 1;
BA_ "GenSigStartValue" SG_ 961 AdbBrdr2Up_An_Rq 400;
BA_ "U_CX482_CX483_MY20_Hev_Tx" SG_ 961 AdbBrdr2Right_An_Rq 1;
BA_ "U_CX482_CX483_MY20_Gas_Tx" SG_ 961 AdbBrdr2Right_An_Rq 1;
BA_ "U_CX482_CX483_MY20_Diesel_Tx" SG_ 961 AdbBrdr2Right_An_Rq 1;
BA_ "U_U611_U625_MY20_Hev_Tx" SG_ 961 AdbBrdr2Right_An_Rq 1;
BA_ "U_U611_U625_MY20_Gas_Tx" SG_ 961 AdbBrdr2Right_An_Rq 1;
BA_ "U_U611_U625_MY20_Diesel_Tx" SG_ 961 AdbBrdr2Right_An_Rq 1;
BA_ "U_C519_MY18_5_Gas_Tx" SG_ 961 AdbBrdr2Right_An_Rq 1;
BA_ "U_C519_MY18_5_Diesel_Tx" SG_ 961 AdbBrdr2Right_An_Rq 1;
BA_ "U_CX482_CX483_MY20_Hev_Rx" SG_ 961 AdbBrdr2Right_An_Rq 1;
BA_ "U_CX482_CX483_MY20_Gas_Rx" SG_ 961 AdbBrdr2Right_An_Rq 1;
BA_ "U_CX482_CX483_MY20_Diesel_Rx" SG_ 961 AdbBrdr2Right_An_Rq 1;
BA_ "U_C519_MY18_5_Gas_Rx" SG_ 961 AdbBrdr2Right_An_Rq 1;
BA_ "U_C519_MY18_5_Diesel_Rx" SG_ 961 AdbBrdr2Right_An_Rq 1;
BA_ "GenSigStartValue" SG_ 961 AdbBrdr2Right_An_Rq 1000;
BA_ "U_CX482_CX483_MY20_Hev_Tx" SG_ 961 AdbBrdr2Low_An_Rq 1;
BA_ "U_CX482_CX483_MY20_Gas_Tx" SG_ 961 AdbBrdr2Low_An_Rq 1;
BA_ "U_CX482_CX483_MY20_Diesel_Tx" SG_ 961 AdbBrdr2Low_An_Rq 1;
BA_ "U_U611_U625_MY20_Hev_Tx" SG_ 961 AdbBrdr2Low_An_Rq 1;
BA_ "U_U611_U625_MY20_Gas_Tx" SG_ 961 AdbBrdr2Low_An_Rq 1;
BA_ "U_U611_U625_MY20_Diesel_Tx" SG_ 961 AdbBrdr2Low_An_Rq 1;
BA_ "U_C519_MY18_5_Gas_Tx" SG_ 961 AdbBrdr2Low_An_Rq 1;
BA_ "U_C519_MY18_5_Diesel_Tx" SG_ 961 AdbBrdr2Low_An_Rq 1;
BA_ "U_CX482_CX483_MY20_Hev_Rx" SG_ 961 AdbBrdr2Low_An_Rq 1;
BA_ "U_CX482_CX483_MY20_Gas_Rx" SG_ 961 AdbBrdr2Low_An_Rq 1;
BA_ "U_CX482_CX483_MY20_Diesel_Rx" SG_ 961 AdbBrdr2Low_An_Rq 1;
BA_ "U_C519_MY18_5_Gas_Rx" SG_ 961 AdbBrdr2Low_An_Rq 1;
BA_ "U_C519_MY18_5_Diesel_Rx" SG_ 961 AdbBrdr2Low_An_Rq 1;
BA_ "GenSigStartValue" SG_ 961 AdbBrdr2Low_An_Rq 400;
BA_ "U_CX482_CX483_MY20_Hev_Tx" SG_ 961 AdbBrdr2Left_An_Rq 1;
BA_ "U_CX482_CX483_MY20_Gas_Tx" SG_ 961 AdbBrdr2Left_An_Rq 1;
BA_ "U_CX482_CX483_MY20_Diesel_Tx" SG_ 961 AdbBrdr2Left_An_Rq 1;
BA_ "U_U611_U625_MY20_Hev_Tx" SG_ 961 AdbBrdr2Left_An_Rq 1;
BA_ "U_U611_U625_MY20_Gas_Tx" SG_ 961 AdbBrdr2Left_An_Rq 1;
BA_ "U_U611_U625_MY20_Diesel_Tx" SG_ 961 AdbBrdr2Left_An_Rq 1;
BA_ "U_C519_MY18_5_Gas_Tx" SG_ 961 AdbBrdr2Left_An_Rq 1;
BA_ "U_C519_MY18_5_Diesel_Tx" SG_ 961 AdbBrdr2Left_An_Rq 1;
BA_ "U_CX482_CX483_MY20_Hev_Rx" SG_ 961 AdbBrdr2Left_An_Rq 1;
BA_ "U_CX482_CX483_MY20_Gas_Rx" SG_ 961 AdbBrdr2Left_An_Rq 1;
BA_ "U_CX482_CX483_MY20_Diesel_Rx" SG_ 961 AdbBrdr2Left_An_Rq 1;
BA_ "U_C519_MY18_5_Gas_Rx" SG_ 961 AdbBrdr2Left_An_Rq 1;
BA_ "U_C519_MY18_5_Diesel_Rx" SG_ 961 AdbBrdr2Left_An_Rq 1;
BA_ "GenSigStartValue" SG_ 961 AdbBrdr2Left_An_Rq 1000;
BA_ "U_CX482_CX483_MY20_Hev_Tx" SG_ 961 AdbBrdr2CritRigh_T_Stat 1;
BA_ "U_CX482_CX483_MY20_Gas_Tx" SG_ 961 AdbBrdr2CritRigh_T_Stat 1;
BA_ "U_CX482_CX483_MY20_Diesel_Tx" SG_ 961 AdbBrdr2CritRigh_T_Stat 1;
BA_ "U_U611_U625_MY20_Hev_Tx" SG_ 961 AdbBrdr2CritRigh_T_Stat 1;
BA_ "U_U611_U625_MY20_Gas_Tx" SG_ 961 AdbBrdr2CritRigh_T_Stat 1;
BA_ "U_U611_U625_MY20_Diesel_Tx" SG_ 961 AdbBrdr2CritRigh_T_Stat 1;
BA_ "U_C519_MY18_5_Gas_Tx" SG_ 961 AdbBrdr2CritRigh_T_Stat 1;
BA_ "U_C519_MY18_5_Diesel_Tx" SG_ 961 AdbBrdr2CritRigh_T_Stat 1;
BA_ "U_CX482_CX483_MY20_Hev_Rx" SG_ 961 AdbBrdr2CritRigh_T_Stat 1;
BA_ "U_CX482_CX483_MY20_Gas_Rx" SG_ 961 AdbBrdr2CritRigh_T_Stat 1;
BA_ "U_CX482_CX483_MY20_Diesel_Rx" SG_ 961 AdbBrdr2CritRigh_T_Stat 1;
BA_ "U_C519_MY18_5_Gas_Rx" SG_ 961 AdbBrdr2CritRigh_T_Stat 1;
BA_ "U_C519_MY18_5_Diesel_Rx" SG_ 961 AdbBrdr2CritRigh_T_Stat 1;
BA_ "U_CX482_CX483_MY20_Hev_Tx" SG_ 961 AdbBrdr2CritLeft_T_Stat 1;
BA_ "U_CX482_CX483_MY20_Gas_Tx" SG_ 961 AdbBrdr2CritLeft_T_Stat 1;
BA_ "U_CX482_CX483_MY20_Diesel_Tx" SG_ 961 AdbBrdr2CritLeft_T_Stat 1;
BA_ "U_U611_U625_MY20_Hev_Tx" SG_ 961 AdbBrdr2CritLeft_T_Stat 1;
BA_ "U_U611_U625_MY20_Gas_Tx" SG_ 961 AdbBrdr2CritLeft_T_Stat 1;
BA_ "U_U611_U625_MY20_Diesel_Tx" SG_ 961 AdbBrdr2CritLeft_T_Stat 1;
BA_ "U_C519_MY18_5_Gas_Tx" SG_ 961 AdbBrdr2CritLeft_T_Stat 1;
BA_ "U_C519_MY18_5_Diesel_Tx" SG_ 961 AdbBrdr2CritLeft_T_Stat 1;
BA_ "U_CX482_CX483_MY20_Hev_Rx" SG_ 961 AdbBrdr2CritLeft_T_Stat 1;
BA_ "U_CX482_CX483_MY20_Gas_Rx" SG_ 961 AdbBrdr2CritLeft_T_Stat 1;
BA_ "U_CX482_CX483_MY20_Diesel_Rx" SG_ 961 AdbBrdr2CritLeft_T_Stat 1;
BA_ "U_C519_MY18_5_Gas_Rx" SG_ 961 AdbBrdr2CritLeft_T_Stat 1;
BA_ "U_C519_MY18_5_Diesel_Rx" SG_ 961 AdbBrdr2CritLeft_T_Stat 1;
BA_ "CrossOver_InfoCAN" SG_ 1122 GpsHsphLongEast_D_Actl 1;
BA_ "CrossOver_InfoCAN" SG_ 1122 GpsHsphLattSth_D_Actl 1;
BA_ "U_CX482_CX483_MY20_Hev_Rx" SG_ 1122 GPS_Longitude_Minutes 1;
BA_ "U_CX482_CX483_MY20_Gas_Rx" SG_ 1122 GPS_Longitude_Minutes 1;
BA_ "U_CX482_CX483_MY20_Diesel_Rx" SG_ 1122 GPS_Longitude_Minutes 1;
BA_ "U_U611_U625_MY20_Hev_Rx" SG_ 1122 GPS_Longitude_Minutes 1;
BA_ "U_U611_U625_MY20_Gas_Rx" SG_ 1122 GPS_Longitude_Minutes 1;
BA_ "U_U611_U625_MY20_Diesel_Rx" SG_ 1122 GPS_Longitude_Minutes 1;
BA_ "U_C519_MY18_5_Gas_Rx" SG_ 1122 GPS_Longitude_Minutes 1;
BA_ "U_C519_MY18_5_Diesel_Rx" SG_ 1122 GPS_Longitude_Minutes 1;
BA_ "CrossOver_InfoCAN" SG_ 1122 GPS_Longitude_Minutes 1;
BA_ "U_CX482_CX483_MY20_Hev_Rx" SG_ 1122 GPS_Longitude_Min_dec 1;
BA_ "U_CX482_CX483_MY20_Gas_Rx" SG_ 1122 GPS_Longitude_Min_dec 1;
BA_ "U_CX482_CX483_MY20_Diesel_Rx" SG_ 1122 GPS_Longitude_Min_dec 1;
BA_ "U_U611_U625_MY20_Hev_Rx" SG_ 1122 GPS_Longitude_Min_dec 1;
BA_ "U_U611_U625_MY20_Gas_Rx" SG_ 1122 GPS_Longitude_Min_dec 1;
BA_ "U_U611_U625_MY20_Diesel_Rx" SG_ 1122 GPS_Longitude_Min_dec 1;
BA_ "U_C519_MY18_5_Gas_Rx" SG_ 1122 GPS_Longitude_Min_dec 1;
BA_ "U_C519_MY18_5_Diesel_Rx" SG_ 1122 GPS_Longitude_Min_dec 1;
BA_ "CrossOver_InfoCAN" SG_ 1122 GPS_Longitude_Min_dec 1;
BA_ "U_CX482_CX483_MY20_Hev_Rx" SG_ 1122 GPS_Longitude_Degrees 1;
BA_ "U_CX482_CX483_MY20_Gas_Rx" SG_ 1122 GPS_Longitude_Degrees 1;
BA_ "U_CX482_CX483_MY20_Diesel_Rx" SG_ 1122 GPS_Longitude_Degrees 1;
BA_ "U_U611_U625_MY20_Hev_Rx" SG_ 1122 GPS_Longitude_Degrees 1;
BA_ "U_U611_U625_MY20_Gas_Rx" SG_ 1122 GPS_Longitude_Degrees 1;
BA_ "U_U611_U625_MY20_Diesel_Rx" SG_ 1122 GPS_Longitude_Degrees 1;
BA_ "U_C519_MY18_5_Gas_Rx" SG_ 1122 GPS_Longitude_Degrees 1;
BA_ "U_C519_MY18_5_Diesel_Rx" SG_ 1122 GPS_Longitude_Degrees 1;
BA_ "GenSigStartValue" SG_ 1122 GPS_Longitude_Degrees 179;
BA_ "CrossOver_InfoCAN" SG_ 1122 GPS_Longitude_Degrees 1;
BA_ "U_CX482_CX483_MY20_Hev_Rx" SG_ 1122 GPS_Latitude_Minutes 1;
BA_ "U_CX482_CX483_MY20_Gas_Rx" SG_ 1122 GPS_Latitude_Minutes 1;
BA_ "U_CX482_CX483_MY20_Diesel_Rx" SG_ 1122 GPS_Latitude_Minutes 1;
BA_ "U_U611_U625_MY20_Hev_Rx" SG_ 1122 GPS_Latitude_Minutes 1;
BA_ "U_U611_U625_MY20_Gas_Rx" SG_ 1122 GPS_Latitude_Minutes 1;
BA_ "U_U611_U625_MY20_Diesel_Rx" SG_ 1122 GPS_Latitude_Minutes 1;
BA_ "U_C519_MY18_5_Gas_Rx" SG_ 1122 GPS_Latitude_Minutes 1;
BA_ "U_C519_MY18_5_Diesel_Rx" SG_ 1122 GPS_Latitude_Minutes 1;
BA_ "CrossOver_InfoCAN" SG_ 1122 GPS_Latitude_Minutes 1;
BA_ "U_CX482_CX483_MY20_Hev_Rx" SG_ 1122 GPS_Latitude_Min_dec 1;
BA_ "U_CX482_CX483_MY20_Gas_Rx" SG_ 1122 GPS_Latitude_Min_dec 1;
BA_ "U_CX482_CX483_MY20_Diesel_Rx" SG_ 1122 GPS_Latitude_Min_dec 1;
BA_ "U_U611_U625_MY20_Hev_Rx" SG_ 1122 GPS_Latitude_Min_dec 1;
BA_ "U_U611_U625_MY20_Gas_Rx" SG_ 1122 GPS_Latitude_Min_dec 1;
BA_ "U_U611_U625_MY20_Diesel_Rx" SG_ 1122 GPS_Latitude_Min_dec 1;
BA_ "U_C519_MY18_5_Gas_Rx" SG_ 1122 GPS_Latitude_Min_dec 1;
BA_ "U_C519_MY18_5_Diesel_Rx" SG_ 1122 GPS_Latitude_Min_dec 1;
BA_ "CrossOver_InfoCAN" SG_ 1122 GPS_Latitude_Min_dec 1;
BA_ "U_CX482_CX483_MY20_Hev_Rx" SG_ 1122 GPS_Latitude_Degrees 1;
BA_ "U_CX482_CX483_MY20_Gas_Rx" SG_ 1122 GPS_Latitude_Degrees 1;
BA_ "U_CX482_CX483_MY20_Diesel_Rx" SG_ 1122 GPS_Latitude_Degrees 1;
BA_ "U_U611_U625_MY20_Hev_Rx" SG_ 1122 GPS_Latitude_Degrees 1;
BA_ "U_U611_U625_MY20_Gas_Rx" SG_ 1122 GPS_Latitude_Degrees 1;
BA_ "U_U611_U625_MY20_Diesel_Rx" SG_ 1122 GPS_Latitude_Degrees 1;
BA_ "U_C519_MY18_5_Gas_Rx" SG_ 1122 GPS_Latitude_Degrees 1;
BA_ "U_C519_MY18_5_Diesel_Rx" SG_ 1122 GPS_Latitude_Degrees 1;
BA_ "CrossOver_InfoCAN" SG_ 1122 GPS_Latitude_Degrees 1;
BA_ "GenSigSendType" SG_ 1080 AutoTowActv_B_Stat 3;
BA_ "GenSigSendType" SG_ 1080 TurnLghtSwtch_D_Stat2 3;
BA_ "U_U611_U625_MY20_Phev_Rx" SG_ 1080 CabnAmb_Te_Actl_UB 1;
BA_ "U_CX482_CX483_MY20_Hev_Rx" SG_ 1080 CabnAmb_Te_Actl_UB 1;
BA_ "U_CX482_CX483_MY20_Gas_Rx" SG_ 1080 CabnAmb_Te_Actl_UB 1;
BA_ "U_CX482_CX483_MY20_Diesel_Rx" SG_ 1080 CabnAmb_Te_Actl_UB 1;
BA_ "U_U611_U625_MY20_Hev_Rx" SG_ 1080 CabnAmb_Te_Actl_UB 1;
BA_ "U_U611_U625_MY20_Gas_Rx" SG_ 1080 CabnAmb_Te_Actl_UB 1;
BA_ "U_U611_U625_MY20_Diesel_Rx" SG_ 1080 CabnAmb_Te_Actl_UB 1;
BA_ "U_B500_MY18_Diesel_Rx" SG_ 1080 CabnAmb_Te_Actl_UB 1;
BA_ "U_B500_MY18_Gas_Rx" SG_ 1080 CabnAmb_Te_Actl_UB 1;
BA_ "U_C519_MY18_5_Gas_Rx" SG_ 1080 CabnAmb_Te_Actl_UB 1;
BA_ "U_C519_MY18_5_Diesel_Rx" SG_ 1080 CabnAmb_Te_Actl_UB 1;
BA_ "U_B479_MY17_Diesel_Rx" SG_ 1080 CabnAmb_Te_Actl_UB 1;
BA_ "U_B479_MY17_Gas_Rx" SG_ 1080 CabnAmb_Te_Actl_UB 1;
BA_ "U_U611_U625_MY20_Phev_Rx" SG_ 1080 CabnAmb_Te_Actl 1;
BA_ "U_CX482_CX483_MY20_Hev_Rx" SG_ 1080 CabnAmb_Te_Actl 1;
BA_ "U_CX482_CX483_MY20_Gas_Rx" SG_ 1080 CabnAmb_Te_Actl 1;
BA_ "U_CX482_CX483_MY20_Diesel_Rx" SG_ 1080 CabnAmb_Te_Actl 1;
BA_ "U_U611_U625_MY20_Hev_Rx" SG_ 1080 CabnAmb_Te_Actl 1;
BA_ "U_U611_U625_MY20_Gas_Rx" SG_ 1080 CabnAmb_Te_Actl 1;
BA_ "U_U611_U625_MY20_Diesel_Rx" SG_ 1080 CabnAmb_Te_Actl 1;
BA_ "U_B500_MY18_Diesel_Rx" SG_ 1080 CabnAmb_Te_Actl 1;
BA_ "U_B500_MY18_Gas_Rx" SG_ 1080 CabnAmb_Te_Actl 1;
BA_ "U_C519_MY18_5_Gas_Rx" SG_ 1080 CabnAmb_Te_Actl 1;
BA_ "U_C519_MY18_5_Diesel_Rx" SG_ 1080 CabnAmb_Te_Actl 1;
BA_ "U_B515_MCA_MY17_Gas_Rx" SG_ 1080 CabnAmb_Te_Actl 1;
BA_ "U_B515_MCA_MY17_Diesel_Rx" SG_ 1080 CabnAmb_Te_Actl 1;
BA_ "U_B479_MY17_Diesel_Rx" SG_ 1080 CabnAmb_Te_Actl 1;
BA_ "U_B479_MY17_Gas_Rx" SG_ 1080 CabnAmb_Te_Actl 1;
BA_ "GenSigStartValue" SG_ 1080 CabnAmb_Te_Actl 114;
BA_ "U_U611_U625_MY20_Phev_Rx" SG_ 1080 HeadLghtHiPrmsn_D_Stat_UB 1;
BA_ "U_CX482_CX483_MY20_Hev_Rx" SG_ 1080 HeadLghtHiPrmsn_D_Stat_UB 1;
BA_ "U_CX482_CX483_MY20_Gas_Rx" SG_ 1080 HeadLghtHiPrmsn_D_Stat_UB 1;
BA_ "U_CX482_CX483_MY20_Diesel_Rx" SG_ 1080 HeadLghtHiPrmsn_D_Stat_UB 1;
BA_ "U_U611_U625_MY20_Hev_Rx" SG_ 1080 HeadLghtHiPrmsn_D_Stat_UB 1;
BA_ "U_U611_U625_MY20_Gas_Rx" SG_ 1080 HeadLghtHiPrmsn_D_Stat_UB 1;
BA_ "U_U611_U625_MY20_Diesel_Rx" SG_ 1080 HeadLghtHiPrmsn_D_Stat_UB 1;
BA_ "U_B500_MY18_Diesel_Rx" SG_ 1080 HeadLghtHiPrmsn_D_Stat_UB 1;
BA_ "U_B500_MY18_Gas_Rx" SG_ 1080 HeadLghtHiPrmsn_D_Stat_UB 1;
BA_ "U_C519_MY18_5_Gas_Rx" SG_ 1080 HeadLghtHiPrmsn_D_Stat_UB 1;
BA_ "U_C519_MY18_5_Diesel_Rx" SG_ 1080 HeadLghtHiPrmsn_D_Stat_UB 1;
BA_ "U_B515_MCA_MY17_Gas_Rx" SG_ 1080 HeadLghtHiPrmsn_D_Stat_UB 1;
BA_ "U_B515_MCA_MY17_Diesel_Rx" SG_ 1080 HeadLghtHiPrmsn_D_Stat_UB 1;
BA_ "U_B479_MY17_Diesel_Rx" SG_ 1080 HeadLghtHiPrmsn_D_Stat_UB 1;
BA_ "U_B479_MY17_Gas_Rx" SG_ 1080 HeadLghtHiPrmsn_D_Stat_UB 1;
BA_ "U_U611_U625_MY20_Phev_Rx" SG_ 1080 HeadLghtHiPrmsn_D_Stat 1;
BA_ "U_CX482_CX483_MY20_Hev_Rx" SG_ 1080 HeadLghtHiPrmsn_D_Stat 1;
BA_ "U_CX482_CX483_MY20_Gas_Rx" SG_ 1080 HeadLghtHiPrmsn_D_Stat 1;
BA_ "U_CX482_CX483_MY20_Diesel_Rx" SG_ 1080 HeadLghtHiPrmsn_D_Stat 1;
BA_ "U_U611_U625_MY20_Hev_Rx" SG_ 1080 HeadLghtHiPrmsn_D_Stat 1;
BA_ "U_U611_U625_MY20_Gas_Rx" SG_ 1080 HeadLghtHiPrmsn_D_Stat 1;
BA_ "U_U611_U625_MY20_Diesel_Rx" SG_ 1080 HeadLghtHiPrmsn_D_Stat 1;
BA_ "U_B500_MY18_Diesel_Rx" SG_ 1080 HeadLghtHiPrmsn_D_Stat 1;
BA_ "U_B500_MY18_Gas_Rx" SG_ 1080 HeadLghtHiPrmsn_D_Stat 1;
BA_ "U_C519_MY18_5_Gas_Rx" SG_ 1080 HeadLghtHiPrmsn_D_Stat 1;
BA_ "U_C519_MY18_5_Diesel_Rx" SG_ 1080 HeadLghtHiPrmsn_D_Stat 1;
BA_ "U_B515_MCA_MY17_Gas_Rx" SG_ 1080 HeadLghtHiPrmsn_D_Stat 1;
BA_ "U_B515_MCA_MY17_Diesel_Rx" SG_ 1080 HeadLghtHiPrmsn_D_Stat 1;
BA_ "U_B479_MY17_Diesel_Rx" SG_ 1080 HeadLghtHiPrmsn_D_Stat 1;
BA_ "U_B479_MY17_Gas_Rx" SG_ 1080 HeadLghtHiPrmsn_D_Stat 1;
BA_ "GenSigSendType" SG_ 1080 HeadLghtHiPrmsn_D_Stat 3;
BA_ "GenSigStartValue" SG_ 1080 HeadLghtHiPrmsn_D_Stat 3;
BA_ "U_U611_U625_MY20_Hev_Tx" SG_ 1121 AutoHoldSwtch_D_Stat2 1;
BA_ "U_U611_U625_MY20_Gas_Tx" SG_ 1121 AutoHoldSwtch_D_Stat2 1;
BA_ "U_U611_U625_MY20_Diesel_Tx" SG_ 1121 AutoHoldSwtch_D_Stat2 1;
BA_ "U_U611_U625_MY20_Hev_Rx" SG_ 1121 AutoHoldSwtch_D_Stat2 1;
BA_ "U_U611_U625_MY20_Gas_Rx" SG_ 1121 AutoHoldSwtch_D_Stat2 1;
BA_ "U_U611_U625_MY20_Diesel_Rx" SG_ 1121 AutoHoldSwtch_D_Stat2 1;
BA_ "GenSigSendType" SG_ 1121 AutoHoldSwtch_D_Stat2 3;
BA_ "U_U611_U625_MY20_Hev_Tx" SG_ 1121 PrkAidSwtch_D_RqDrv3 1;
BA_ "U_U611_U625_MY20_Gas_Tx" SG_ 1121 PrkAidSwtch_D_RqDrv3 1;
BA_ "U_U611_U625_MY20_Diesel_Tx" SG_ 1121 PrkAidSwtch_D_RqDrv3 1;
BA_ "GenSigSendType" SG_ 1121 PrkAidSwtch_D_RqDrv3 3;
BA_ "U_U611_U625_MY20_Hev_Tx" SG_ 1121 ApaSwtch_D_RqDrv3 1;
BA_ "U_U611_U625_MY20_Gas_Tx" SG_ 1121 ApaSwtch_D_RqDrv3 1;
BA_ "U_U611_U625_MY20_Diesel_Tx" SG_ 1121 ApaSwtch_D_RqDrv3 1;
BA_ "GenSigSendType" SG_ 1121 ApaSwtch_D_RqDrv3 3;
BA_ "U_U611_U625_MY20_Hev_Tx" SG_ 1121 StopStrtDrvMde_B_RqBtn2 1;
BA_ "U_U611_U625_MY20_Gas_Tx" SG_ 1121 StopStrtDrvMde_B_RqBtn2 1;
BA_ "U_U611_U625_MY20_Diesel_Tx" SG_ 1121 StopStrtDrvMde_B_RqBtn2 1;
BA_ "GenSigSendType" SG_ 1121 StopStrtDrvMde_B_RqBtn2 3;
BA_ "U_U611_U625_MY20_Hev_Tx" SG_ 1121 SelDrvMdeSwtch_No_Actl 1;
BA_ "U_U611_U625_MY20_Gas_Tx" SG_ 1121 SelDrvMdeSwtch_No_Actl 1;
BA_ "U_U611_U625_MY20_Diesel_Tx" SG_ 1121 SelDrvMdeSwtch_No_Actl 1;
BA_ "U_CX482_CX483_MY20_Hev_Rx" SG_ 1121 SelDrvMdeSwtch_No_Actl 1;
BA_ "U_CX482_CX483_MY20_Gas_Rx" SG_ 1121 SelDrvMdeSwtch_No_Actl 1;
BA_ "U_CX482_CX483_MY20_Diesel_Rx" SG_ 1121 SelDrvMdeSwtch_No_Actl 1;
BA_ "U_U611_U625_MY20_Hev_Rx" SG_ 1121 SelDrvMdeSwtch_No_Actl 1;
BA_ "U_U611_U625_MY20_Gas_Rx" SG_ 1121 SelDrvMdeSwtch_No_Actl 1;
BA_ "U_U611_U625_MY20_Diesel_Rx" SG_ 1121 SelDrvMdeSwtch_No_Actl 1;
BA_ "U_C519_MY18_5_Gas_Rx" SG_ 1121 SelDrvMdeSwtch_No_Actl 1;
BA_ "U_C519_MY18_5_Diesel_Rx" SG_ 1121 SelDrvMdeSwtch_No_Actl 1;
BA_ "GenSigSendType" SG_ 1121 SelDrvMdeSwtch_No_Actl 3;
BA_ "U_U611_U625_MY20_Hev_Tx" SG_ 1121 SelDrvMdeSwtch_D_Stat 1;
BA_ "U_U611_U625_MY20_Gas_Tx" SG_ 1121 SelDrvMdeSwtch_D_Stat 1;
BA_ "U_U611_U625_MY20_Diesel_Tx" SG_ 1121 SelDrvMdeSwtch_D_Stat 1;
BA_ "U_CX482_CX483_MY20_Hev_Rx" SG_ 1121 SelDrvMdeSwtch_D_Stat 1;
BA_ "U_CX482_CX483_MY20_Gas_Rx" SG_ 1121 SelDrvMdeSwtch_D_Stat 1;
BA_ "U_CX482_CX483_MY20_Diesel_Rx" SG_ 1121 SelDrvMdeSwtch_D_Stat 1;
BA_ "U_U611_U625_MY20_Hev_Rx" SG_ 1121 SelDrvMdeSwtch_D_Stat 1;
BA_ "U_U611_U625_MY20_Gas_Rx" SG_ 1121 SelDrvMdeSwtch_D_Stat 1;
BA_ "U_U611_U625_MY20_Diesel_Rx" SG_ 1121 SelDrvMdeSwtch_D_Stat 1;
BA_ "U_C519_MY18_5_Gas_Rx" SG_ 1121 SelDrvMdeSwtch_D_Stat 1;
BA_ "U_C519_MY18_5_Diesel_Rx" SG_ 1121 SelDrvMdeSwtch_D_Stat 1;
BA_ "GenSigSendType" SG_ 1121 SelDrvMdeSwtch_D_Stat 3;
BA_ "U_U611_U625_MY20_Hev_Tx" SG_ 1121 SelDrvMdeCnt_D_Stat 1;
BA_ "U_U611_U625_MY20_Gas_Tx" SG_ 1121 SelDrvMdeCnt_D_Stat 1;
BA_ "U_U611_U625_MY20_Diesel_Tx" SG_ 1121 SelDrvMdeCnt_D_Stat 1;
BA_ "U_CX482_CX483_MY20_Hev_Rx" SG_ 1121 SelDrvMdeCnt_D_Stat 1;
BA_ "U_CX482_CX483_MY20_Gas_Rx" SG_ 1121 SelDrvMdeCnt_D_Stat 1;
BA_ "U_CX482_CX483_MY20_Diesel_Rx" SG_ 1121 SelDrvMdeCnt_D_Stat 1;
BA_ "U_U611_U625_MY20_Hev_Rx" SG_ 1121 SelDrvMdeCnt_D_Stat 1;
BA_ "U_U611_U625_MY20_Gas_Rx" SG_ 1121 SelDrvMdeCnt_D_Stat 1;
BA_ "U_U611_U625_MY20_Diesel_Rx" SG_ 1121 SelDrvMdeCnt_D_Stat 1;
BA_ "U_C519_MY18_5_Gas_Rx" SG_ 1121 SelDrvMdeCnt_D_Stat 1;
BA_ "U_C519_MY18_5_Diesel_Rx" SG_ 1121 SelDrvMdeCnt_D_Stat 1;
BA_ "GenSigSendType" SG_ 1121 SelDrvMdeCnt_D_Stat 3;
BA_ "U_CX482_CX483_MY20_Hev_Rx" SG_ 517 TrnAinLss_Tq_Est 1;
BA_ "U_CX482_CX483_MY20_Gas_Rx" SG_ 517 TrnAinLss_Tq_Est 1;
BA_ "U_CX482_CX483_MY20_Diesel_Rx" SG_ 517 TrnAinLss_Tq_Est 1;
BA_ "U_B500_MY18_Diesel_Rx" SG_ 517 TrnAinLss_Tq_Est 1;
BA_ "U_B500_MY18_Gas_Rx" SG_ 517 TrnAinLss_Tq_Est 1;
BA_ "U_B562_MY18_Gas_Rx" SG_ 517 TrnAinLss_Tq_Est 1;
BA_ "U_C519_MY18_5_Gas_Rx" SG_ 517 TrnAinLss_Tq_Est 1;
BA_ "U_C519_MY18_5_Diesel_Rx" SG_ 517 TrnAinLss_Tq_Est 1;
BA_ "U_B515_MCA_MY17_Gas_Rx" SG_ 517 TrnAinLss_Tq_Est 1;
BA_ "U_B515_MCA_MY17_Diesel_Rx" SG_ 517 TrnAinLss_Tq_Est 1;
BA_ "U_B479_MY17_Diesel_Rx" SG_ 517 TrnAinLss_Tq_Est 1;
BA_ "U_B479_MY17_Gas_Rx" SG_ 517 TrnAinLss_Tq_Est 1;
BA_ "U_CX482_CX483_MY20_Hev_Rx" SG_ 517 BrkTot_Tq_RqFapLc_UB 1;
BA_ "U_CX482_CX483_MY20_Gas_Rx" SG_ 517 BrkTot_Tq_RqFapLc_UB 1;
BA_ "U_CX482_CX483_MY20_Diesel_Rx" SG_ 517 BrkTot_Tq_RqFapLc_UB 1;
BA_ "U_C519_MY18_5_Gas_Rx" SG_ 517 BrkTot_Tq_RqFapLc_UB 1;
BA_ "U_C519_MY18_5_Diesel_Rx" SG_ 517 BrkTot_Tq_RqFapLc_UB 1;
BA_ "U_CX482_CX483_MY20_Hev_Rx" SG_ 517 BrkTot_Tq_RqFapLc 1;
BA_ "U_CX482_CX483_MY20_Gas_Rx" SG_ 517 BrkTot_Tq_RqFapLc 1;
BA_ "U_CX482_CX483_MY20_Diesel_Rx" SG_ 517 BrkTot_Tq_RqFapLc 1;
BA_ "U_B500_MY18_Diesel_Rx" SG_ 517 BrkTot_Tq_RqFapLc 1;
BA_ "U_B500_MY18_Gas_Rx" SG_ 517 BrkTot_Tq_RqFapLc 1;
BA_ "U_B562_MY18_Gas_Rx" SG_ 517 BrkTot_Tq_RqFapLc 1;
BA_ "U_C519_MY18_5_Gas_Rx" SG_ 517 BrkTot_Tq_RqFapLc 1;
BA_ "U_C519_MY18_5_Diesel_Rx" SG_ 517 BrkTot_Tq_RqFapLc 1;
BA_ "U_CX482_CX483_MY20_Hev_Tx" SG_ 979 HandsOffCnfm_B_Rq 1;
BA_ "U_CX482_CX483_MY20_Gas_Tx" SG_ 979 HandsOffCnfm_B_Rq 1;
BA_ "U_CX482_CX483_MY20_Diesel_Tx" SG_ 979 HandsOffCnfm_B_Rq 1;
BA_ "U_U611_U625_MY20_Hev_Tx" SG_ 979 HandsOffCnfm_B_Rq 1;
BA_ "U_U611_U625_MY20_Gas_Tx" SG_ 979 HandsOffCnfm_B_Rq 1;
BA_ "U_U611_U625_MY20_Diesel_Tx" SG_ 979 HandsOffCnfm_B_Rq 1;
BA_ "U_C519_MY18_5_Gas_Tx" SG_ 979 HandsOffCnfm_B_Rq 1;
BA_ "U_C519_MY18_5_Diesel_Tx" SG_ 979 HandsOffCnfm_B_Rq 1;
BA_ "U_U611_U625_MY20_Phev_Rx" SG_ 979 HandsOffCnfm_B_Rq 1;
BA_ "U_CX482_CX483_MY20_Hev_Rx" SG_ 979 HandsOffCnfm_B_Rq 1;
BA_ "U_CX482_CX483_MY20_Gas_Rx" SG_ 979 HandsOffCnfm_B_Rq 1;
BA_ "U_CX482_CX483_MY20_Diesel_Rx" SG_ 979 HandsOffCnfm_B_Rq 1;
BA_ "U_U611_U625_MY20_Hev_Rx" SG_ 979 HandsOffCnfm_B_Rq 1;
BA_ "U_U611_U625_MY20_Gas_Rx" SG_ 979 HandsOffCnfm_B_Rq 1;
BA_ "U_U611_U625_MY20_Diesel_Rx" SG_ 979 HandsOffCnfm_B_Rq 1;
BA_ "U_C519_MY18_5_Gas_Rx" SG_ 979 HandsOffCnfm_B_Rq 1;
BA_ "U_C519_MY18_5_Diesel_Rx" SG_ 979 HandsOffCnfm_B_Rq 1;
BA_ "U_CX482_CX483_MY20_Hev_Tx" SG_ 979 LatCtl_D_Rq 1;
BA_ "U_CX482_CX483_MY20_Gas_Tx" SG_ 979 LatCtl_D_Rq 1;
BA_ "U_CX482_CX483_MY20_Diesel_Tx" SG_ 979 LatCtl_D_Rq 1;
BA_ "U_U611_U625_MY20_Hev_Tx" SG_ 979 LatCtl_D_Rq 1;
BA_ "U_U611_U625_MY20_Gas_Tx" SG_ 979 LatCtl_D_Rq 1;
BA_ "U_U611_U625_MY20_Diesel_Tx" SG_ 979 LatCtl_D_Rq 1;
BA_ "U_C519_MY18_5_Gas_Tx" SG_ 979 LatCtl_D_Rq 1;
BA_ "U_C519_MY18_5_Diesel_Tx" SG_ 979 LatCtl_D_Rq 1;
BA_ "U_U611_U625_MY20_Phev_Rx" SG_ 979 LatCtl_D_Rq 1;
BA_ "U_CX482_CX483_MY20_Hev_Rx" SG_ 979 LatCtl_D_Rq 1;
BA_ "U_CX482_CX483_MY20_Gas_Rx" SG_ 979 LatCtl_D_Rq 1;
BA_ "U_CX482_CX483_MY20_Diesel_Rx" SG_ 979 LatCtl_D_Rq 1;
BA_ "U_U611_U625_MY20_Hev_Rx" SG_ 979 LatCtl_D_Rq 1;
BA_ "U_U611_U625_MY20_Gas_Rx" SG_ 979 LatCtl_D_Rq 1;
BA_ "U_U611_U625_MY20_Diesel_Rx" SG_ 979 LatCtl_D_Rq 1;
BA_ "U_B562_MY18_Gas_Rx" SG_ 979 LatCtl_D_Rq 1;
BA_ "U_C519_MY18_5_Gas_Rx" SG_ 979 LatCtl_D_Rq 1;
BA_ "U_C519_MY18_5_Diesel_Rx" SG_ 979 LatCtl_D_Rq 1;
BA_ "U_CX482_CX483_MY20_Hev_Tx" SG_ 979 LatCtlRampType_D_Rq 1;
BA_ "U_CX482_CX483_MY20_Gas_Tx" SG_ 979 LatCtlRampType_D_Rq 1;
BA_ "U_CX482_CX483_MY20_Diesel_Tx" SG_ 979 LatCtlRampType_D_Rq 1;
BA_ "U_U611_U625_MY20_Hev_Tx" SG_ 979 LatCtlRampType_D_Rq 1;
BA_ "U_U611_U625_MY20_Gas_Tx" SG_ 979 LatCtlRampType_D_Rq 1;
BA_ "U_U611_U625_MY20_Diesel_Tx" SG_ 979 LatCtlRampType_D_Rq 1;
BA_ "U_C519_MY18_5_Gas_Tx" SG_ 979 LatCtlRampType_D_Rq 1;
BA_ "U_C519_MY18_5_Diesel_Tx" SG_ 979 LatCtlRampType_D_Rq 1;
BA_ "U_U611_U625_MY20_Phev_Rx" SG_ 979 LatCtlRampType_D_Rq 1;
BA_ "U_CX482_CX483_MY20_Hev_Rx" SG_ 979 LatCtlRampType_D_Rq 1;
BA_ "U_CX482_CX483_MY20_Gas_Rx" SG_ 979 LatCtlRampType_D_Rq 1;
BA_ "U_CX482_CX483_MY20_Diesel_Rx" SG_ 979 LatCtlRampType_D_Rq 1;
BA_ "U_U611_U625_MY20_Hev_Rx" SG_ 979 LatCtlRampType_D_Rq 1;
BA_ "U_U611_U625_MY20_Gas_Rx" SG_ 979 LatCtlRampType_D_Rq 1;
BA_ "U_U611_U625_MY20_Diesel_Rx" SG_ 979 LatCtlRampType_D_Rq 1;
BA_ "U_B562_MY18_Gas_Rx" SG_ 979 LatCtlRampType_D_Rq 1;
BA_ "U_C519_MY18_5_Gas_Rx" SG_ 979 LatCtlRampType_D_Rq 1;
BA_ "U_C519_MY18_5_Diesel_Rx" SG_ 979 LatCtlRampType_D_Rq 1;
BA_ "U_CX482_CX483_MY20_Hev_Tx" SG_ 979 LatCtlPrecision_D_Rq 1;
BA_ "U_CX482_CX483_MY20_Gas_Tx" SG_ 979 LatCtlPrecision_D_Rq 1;
BA_ "U_CX482_CX483_MY20_Diesel_Tx" SG_ 979 LatCtlPrecision_D_Rq 1;
BA_ "U_U611_U625_MY20_Hev_Tx" SG_ 979 LatCtlPrecision_D_Rq 1;
BA_ "U_U611_U625_MY20_Gas_Tx" SG_ 979 LatCtlPrecision_D_Rq 1;
BA_ "U_U611_U625_MY20_Diesel_Tx" SG_ 979 LatCtlPrecision_D_Rq 1;
BA_ "U_C519_MY18_5_Gas_Tx" SG_ 979 LatCtlPrecision_D_Rq 1;
BA_ "U_C519_MY18_5_Diesel_Tx" SG_ 979 LatCtlPrecision_D_Rq 1;
BA_ "U_U611_U625_MY20_Phev_Rx" SG_ 979 LatCtlPrecision_D_Rq 1;
BA_ "U_CX482_CX483_MY20_Hev_Rx" SG_ 979 LatCtlPrecision_D_Rq 1;
BA_ "U_CX482_CX483_MY20_Gas_Rx" SG_ 979 LatCtlPrecision_D_Rq 1;
BA_ "U_CX482_CX483_MY20_Diesel_Rx" SG_ 979 LatCtlPrecision_D_Rq 1;
BA_ "U_U611_U625_MY20_Hev_Rx" SG_ 979 LatCtlPrecision_D_Rq 1;
BA_ "U_U611_U625_MY20_Gas_Rx" SG_ 979 LatCtlPrecision_D_Rq 1;
BA_ "U_U611_U625_MY20_Diesel_Rx" SG_ 979 LatCtlPrecision_D_Rq 1;
BA_ "U_B562_MY18_Gas_Rx" SG_ 979 LatCtlPrecision_D_Rq 1;
BA_ "U_C519_MY18_5_Gas_Rx" SG_ 979 LatCtlPrecision_D_Rq 1;
BA_ "U_C519_MY18_5_Diesel_Rx" SG_ 979 LatCtlPrecision_D_Rq 1;
BA_ "U_CX482_CX483_MY20_Hev_Tx" SG_ 979 LatCtlPathOffst_L_Actl 1;
BA_ "U_CX482_CX483_MY20_Gas_Tx" SG_ 979 LatCtlPathOffst_L_Actl 1;
BA_ "U_CX482_CX483_MY20_Diesel_Tx" SG_ 979 LatCtlPathOffst_L_Actl 1;
BA_ "U_U611_U625_MY20_Hev_Tx" SG_ 979 LatCtlPathOffst_L_Actl 1;
BA_ "U_U611_U625_MY20_Gas_Tx" SG_ 979 LatCtlPathOffst_L_Actl 1;
BA_ "U_U611_U625_MY20_Diesel_Tx" SG_ 979 LatCtlPathOffst_L_Actl 1;
BA_ "U_C519_MY18_5_Gas_Tx" SG_ 979 LatCtlPathOffst_L_Actl 1;
BA_ "U_C519_MY18_5_Diesel_Tx" SG_ 979 LatCtlPathOffst_L_Actl 1;
BA_ "U_U611_U625_MY20_Phev_Rx" SG_ 979 LatCtlPathOffst_L_Actl 1;
BA_ "U_CX482_CX483_MY20_Hev_Rx" SG_ 979 LatCtlPathOffst_L_Actl 1;
BA_ "U_CX482_CX483_MY20_Gas_Rx" SG_ 979 LatCtlPathOffst_L_Actl 1;
BA_ "U_CX482_CX483_MY20_Diesel_Rx" SG_ 979 LatCtlPathOffst_L_Actl 1;
BA_ "U_U611_U625_MY20_Hev_Rx" SG_ 979 LatCtlPathOffst_L_Actl 1;
BA_ "U_U611_U625_MY20_Gas_Rx" SG_ 979 LatCtlPathOffst_L_Actl 1;
BA_ "U_U611_U625_MY20_Diesel_Rx" SG_ 979 LatCtlPathOffst_L_Actl 1;
BA_ "U_B562_MY18_Gas_Rx" SG_ 979 LatCtlPathOffst_L_Actl 1;
BA_ "U_C519_MY18_5_Gas_Rx" SG_ 979 LatCtlPathOffst_L_Actl 1;
BA_ "U_C519_MY18_5_Diesel_Rx" SG_ 979 LatCtlPathOffst_L_Actl 1;
BA_ "GenSigStartValue" SG_ 979 LatCtlPathOffst_L_Actl 512;
BA_ "U_CX482_CX483_MY20_Hev_Tx" SG_ 979 LatCtlPath_An_Actl 1;
BA_ "U_CX482_CX483_MY20_Gas_Tx" SG_ 979 LatCtlPath_An_Actl 1;
BA_ "U_CX482_CX483_MY20_Diesel_Tx" SG_ 979 LatCtlPath_An_Actl 1;
BA_ "U_U611_U625_MY20_Hev_Tx" SG_ 979 LatCtlPath_An_Actl 1;
BA_ "U_U611_U625_MY20_Gas_Tx" SG_ 979 LatCtlPath_An_Actl 1;
BA_ "U_U611_U625_MY20_Diesel_Tx" SG_ 979 LatCtlPath_An_Actl 1;
BA_ "U_C519_MY18_5_Gas_Tx" SG_ 979 LatCtlPath_An_Actl 1;
BA_ "U_C519_MY18_5_Diesel_Tx" SG_ 979 LatCtlPath_An_Actl 1;
BA_ "U_U611_U625_MY20_Phev_Rx" SG_ 979 LatCtlPath_An_Actl 1;
BA_ "U_CX482_CX483_MY20_Hev_Rx" SG_ 979 LatCtlPath_An_Actl 1;
BA_ "U_CX482_CX483_MY20_Gas_Rx" SG_ 979 LatCtlPath_An_Actl 1;
BA_ "U_CX482_CX483_MY20_Diesel_Rx" SG_ 979 LatCtlPath_An_Actl 1;
BA_ "U_U611_U625_MY20_Hev_Rx" SG_ 979 LatCtlPath_An_Actl 1;
BA_ "U_U611_U625_MY20_Gas_Rx" SG_ 979 LatCtlPath_An_Actl 1;
BA_ "U_U611_U625_MY20_Diesel_Rx" SG_ 979 LatCtlPath_An_Actl 1;
BA_ "U_B562_MY18_Gas_Rx" SG_ 979 LatCtlPath_An_Actl 1;
BA_ "U_C519_MY18_5_Gas_Rx" SG_ 979 LatCtlPath_An_Actl 1;
BA_ "U_C519_MY18_5_Diesel_Rx" SG_ 979 LatCtlPath_An_Actl 1;
BA_ "GenSigStartValue" SG_ 979 LatCtlPath_An_Actl 1000;
BA_ "U_CX482_CX483_MY20_Hev_Tx" SG_ 979 LatCtlCurv_NoRate_Actl 1;
BA_ "U_CX482_CX483_MY20_Gas_Tx" SG_ 979 LatCtlCurv_NoRate_Actl 1;
BA_ "U_CX482_CX483_MY20_Diesel_Tx" SG_ 979 LatCtlCurv_NoRate_Actl 1;
BA_ "U_U611_U625_MY20_Hev_Tx" SG_ 979 LatCtlCurv_NoRate_Actl 1;
BA_ "U_U611_U625_MY20_Gas_Tx" SG_ 979 LatCtlCurv_NoRate_Actl 1;
BA_ "U_U611_U625_MY20_Diesel_Tx" SG_ 979 LatCtlCurv_NoRate_Actl 1;
BA_ "U_C519_MY18_5_Gas_Tx" SG_ 979 LatCtlCurv_NoRate_Actl 1;
BA_ "U_C519_MY18_5_Diesel_Tx" SG_ 979 LatCtlCurv_NoRate_Actl 1;
BA_ "U_U611_U625_MY20_Phev_Rx" SG_ 979 LatCtlCurv_NoRate_Actl 1;
BA_ "U_CX482_CX483_MY20_Hev_Rx" SG_ 979 LatCtlCurv_NoRate_Actl 1;
BA_ "U_CX482_CX483_MY20_Gas_Rx" SG_ 979 LatCtlCurv_NoRate_Actl 1;
BA_ "U_CX482_CX483_MY20_Diesel_Rx" SG_ 979 LatCtlCurv_NoRate_Actl 1;
BA_ "U_U611_U625_MY20_Hev_Rx" SG_ 979 LatCtlCurv_NoRate_Actl 1;
BA_ "U_U611_U625_MY20_Gas_Rx" SG_ 979 LatCtlCurv_NoRate_Actl 1;
BA_ "U_U611_U625_MY20_Diesel_Rx" SG_ 979 LatCtlCurv_NoRate_Actl 1;
BA_ "U_B562_MY18_Gas_Rx" SG_ 979 LatCtlCurv_NoRate_Actl 1;
BA_ "U_C519_MY18_5_Gas_Rx" SG_ 979 LatCtlCurv_NoRate_Actl 1;
BA_ "U_C519_MY18_5_Diesel_Rx" SG_ 979 LatCtlCurv_NoRate_Actl 1;
BA_ "GenSigStartValue" SG_ 979 LatCtlCurv_NoRate_Actl 4096;
BA_ "U_CX482_CX483_MY20_Hev_Tx" SG_ 979 LatCtlCurv_No_Actl 1;
BA_ "U_CX482_CX483_MY20_Gas_Tx" SG_ 979 LatCtlCurv_No_Actl 1;
BA_ "U_CX482_CX483_MY20_Diesel_Tx" SG_ 979 LatCtlCurv_No_Actl 1;
BA_ "U_U611_U625_MY20_Hev_Tx" SG_ 979 LatCtlCurv_No_Actl 1;
BA_ "U_U611_U625_MY20_Gas_Tx" SG_ 979 LatCtlCurv_No_Actl 1;
BA_ "U_U611_U625_MY20_Diesel_Tx" SG_ 979 LatCtlCurv_No_Actl 1;
BA_ "U_C519_MY18_5_Gas_Tx" SG_ 979 LatCtlCurv_No_Actl 1;
BA_ "U_C519_MY18_5_Diesel_Tx" SG_ 979 LatCtlCurv_No_Actl 1;
BA_ "U_U611_U625_MY20_Phev_Rx" SG_ 979 LatCtlCurv_No_Actl 1;
BA_ "U_CX482_CX483_MY20_Hev_Rx" SG_ 979 LatCtlCurv_No_Actl 1;
BA_ "U_CX482_CX483_MY20_Gas_Rx" SG_ 979 LatCtlCurv_No_Actl 1;
BA_ "U_CX482_CX483_MY20_Diesel_Rx" SG_ 979 LatCtlCurv_No_Actl 1;
BA_ "U_U611_U625_MY20_Hev_Rx" SG_ 979 LatCtlCurv_No_Actl 1;
BA_ "U_U611_U625_MY20_Gas_Rx" SG_ 979 LatCtlCurv_No_Actl 1;
BA_ "U_U611_U625_MY20_Diesel_Rx" SG_ 979 LatCtlCurv_No_Actl 1;
BA_ "U_B562_MY18_Gas_Rx" SG_ 979 LatCtlCurv_No_Actl 1;
BA_ "U_C519_MY18_5_Gas_Rx" SG_ 979 LatCtlCurv_No_Actl 1;
BA_ "U_C519_MY18_5_Diesel_Rx" SG_ 979 LatCtlCurv_No_Actl 1;
BA_ "GenSigStartValue" SG_ 979 LatCtlCurv_No_Actl 1000;
BA_ "U_CX482_CX483_MY20_Hev_Tx" SG_ 1056 SelDrvMdePos12_B_Avail 1;
BA_ "U_CX482_CX483_MY20_Gas_Tx" SG_ 1056 SelDrvMdePos12_B_Avail 1;
BA_ "U_CX482_CX483_MY20_Diesel_Tx" SG_ 1056 SelDrvMdePos12_B_Avail 1;
BA_ "U_U611_U625_MY20_Hev_Tx" SG_ 1056 SelDrvMdePos12_B_Avail 1;
BA_ "U_U611_U625_MY20_Gas_Tx" SG_ 1056 SelDrvMdePos12_B_Avail 1;
BA_ "U_U611_U625_MY20_Diesel_Tx" SG_ 1056 SelDrvMdePos12_B_Avail 1;
BA_ "U_C519_MY18_5_Gas_Tx" SG_ 1056 SelDrvMdePos12_B_Avail 1;
BA_ "U_C519_MY18_5_Diesel_Tx" SG_ 1056 SelDrvMdePos12_B_Avail 1;
BA_ "GenSigSendType" SG_ 1056 SelDrvMdePos12_B_Avail 3;
BA_ "U_CX482_CX483_MY20_Hev_Tx" SG_ 1056 SelDrvMdePos11_B_Avail 1;
BA_ "U_CX482_CX483_MY20_Gas_Tx" SG_ 1056 SelDrvMdePos11_B_Avail 1;
BA_ "U_CX482_CX483_MY20_Diesel_Tx" SG_ 1056 SelDrvMdePos11_B_Avail 1;
BA_ "U_U611_U625_MY20_Hev_Tx" SG_ 1056 SelDrvMdePos11_B_Avail 1;
BA_ "U_U611_U625_MY20_Gas_Tx" SG_ 1056 SelDrvMdePos11_B_Avail 1;
BA_ "U_U611_U625_MY20_Diesel_Tx" SG_ 1056 SelDrvMdePos11_B_Avail 1;
BA_ "U_C519_MY18_5_Gas_Tx" SG_ 1056 SelDrvMdePos11_B_Avail 1;
BA_ "U_C519_MY18_5_Diesel_Tx" SG_ 1056 SelDrvMdePos11_B_Avail 1;
BA_ "GenSigSendType" SG_ 1056 SelDrvMdePos11_B_Avail 3;
BA_ "U_CX482_CX483_MY20_Hev_Tx" SG_ 1056 SelDrvMdePos10_B_Avail 1;
BA_ "U_CX482_CX483_MY20_Gas_Tx" SG_ 1056 SelDrvMdePos10_B_Avail 1;
BA_ "U_CX482_CX483_MY20_Diesel_Tx" SG_ 1056 SelDrvMdePos10_B_Avail 1;
BA_ "U_U611_U625_MY20_Hev_Tx" SG_ 1056 SelDrvMdePos10_B_Avail 1;
BA_ "U_U611_U625_MY20_Gas_Tx" SG_ 1056 SelDrvMdePos10_B_Avail 1;
BA_ "U_U611_U625_MY20_Diesel_Tx" SG_ 1056 SelDrvMdePos10_B_Avail 1;
BA_ "U_C519_MY18_5_Gas_Tx" SG_ 1056 SelDrvMdePos10_B_Avail 1;
BA_ "U_C519_MY18_5_Diesel_Tx" SG_ 1056 SelDrvMdePos10_B_Avail 1;
BA_ "GenSigSendType" SG_ 1056 SelDrvMdePos10_B_Avail 3;
BA_ "U_CX482_CX483_MY20_Hev_Tx" SG_ 1056 SelDrvMdePos09_B_Avail 1;
BA_ "U_CX482_CX483_MY20_Gas_Tx" SG_ 1056 SelDrvMdePos09_B_Avail 1;
BA_ "U_CX482_CX483_MY20_Diesel_Tx" SG_ 1056 SelDrvMdePos09_B_Avail 1;
BA_ "U_U611_U625_MY20_Hev_Tx" SG_ 1056 SelDrvMdePos09_B_Avail 1;
BA_ "U_U611_U625_MY20_Gas_Tx" SG_ 1056 SelDrvMdePos09_B_Avail 1;
BA_ "U_U611_U625_MY20_Diesel_Tx" SG_ 1056 SelDrvMdePos09_B_Avail 1;
BA_ "U_C519_MY18_5_Gas_Tx" SG_ 1056 SelDrvMdePos09_B_Avail 1;
BA_ "U_C519_MY18_5_Diesel_Tx" SG_ 1056 SelDrvMdePos09_B_Avail 1;
BA_ "GenSigSendType" SG_ 1056 SelDrvMdePos09_B_Avail 3;
BA_ "U_CX482_CX483_MY20_Hev_Tx" SG_ 1056 SelDrvMdePos08_B_Avail 1;
BA_ "U_CX482_CX483_MY20_Gas_Tx" SG_ 1056 SelDrvMdePos08_B_Avail 1;
BA_ "U_CX482_CX483_MY20_Diesel_Tx" SG_ 1056 SelDrvMdePos08_B_Avail 1;
BA_ "U_U611_U625_MY20_Hev_Tx" SG_ 1056 SelDrvMdePos08_B_Avail 1;
BA_ "U_U611_U625_MY20_Gas_Tx" SG_ 1056 SelDrvMdePos08_B_Avail 1;
BA_ "U_U611_U625_MY20_Diesel_Tx" SG_ 1056 SelDrvMdePos08_B_Avail 1;
BA_ "U_C519_MY18_5_Gas_Tx" SG_ 1056 SelDrvMdePos08_B_Avail 1;
BA_ "U_C519_MY18_5_Diesel_Tx" SG_ 1056 SelDrvMdePos08_B_Avail 1;
BA_ "GenSigSendType" SG_ 1056 SelDrvMdePos08_B_Avail 3;
BA_ "U_CX482_CX483_MY20_Hev_Tx" SG_ 1056 SelDrvMdePos07_B_Avail 1;
BA_ "U_CX482_CX483_MY20_Gas_Tx" SG_ 1056 SelDrvMdePos07_B_Avail 1;
BA_ "U_CX482_CX483_MY20_Diesel_Tx" SG_ 1056 SelDrvMdePos07_B_Avail 1;
BA_ "U_U611_U625_MY20_Hev_Tx" SG_ 1056 SelDrvMdePos07_B_Avail 1;
BA_ "U_U611_U625_MY20_Gas_Tx" SG_ 1056 SelDrvMdePos07_B_Avail 1;
BA_ "U_U611_U625_MY20_Diesel_Tx" SG_ 1056 SelDrvMdePos07_B_Avail 1;
BA_ "U_C519_MY18_5_Gas_Tx" SG_ 1056 SelDrvMdePos07_B_Avail 1;
BA_ "U_C519_MY18_5_Diesel_Tx" SG_ 1056 SelDrvMdePos07_B_Avail 1;
BA_ "GenSigSendType" SG_ 1056 SelDrvMdePos07_B_Avail 3;
BA_ "U_CX482_CX483_MY20_Hev_Tx" SG_ 1056 SelDrvMdePos06_B_Avail 1;
BA_ "U_CX482_CX483_MY20_Gas_Tx" SG_ 1056 SelDrvMdePos06_B_Avail 1;
BA_ "U_CX482_CX483_MY20_Diesel_Tx" SG_ 1056 SelDrvMdePos06_B_Avail 1;
BA_ "U_U611_U625_MY20_Hev_Tx" SG_ 1056 SelDrvMdePos06_B_Avail 1;
BA_ "U_U611_U625_MY20_Gas_Tx" SG_ 1056 SelDrvMdePos06_B_Avail 1;
BA_ "U_U611_U625_MY20_Diesel_Tx" SG_ 1056 SelDrvMdePos06_B_Avail 1;
BA_ "U_C519_MY18_5_Gas_Tx" SG_ 1056 SelDrvMdePos06_B_Avail 1;
BA_ "U_C519_MY18_5_Diesel_Tx" SG_ 1056 SelDrvMdePos06_B_Avail 1;
BA_ "GenSigSendType" SG_ 1056 SelDrvMdePos06_B_Avail 3;
BA_ "U_CX482_CX483_MY20_Hev_Tx" SG_ 1056 SelDrvMdePos05_B_Avail 1;
BA_ "U_CX482_CX483_MY20_Gas_Tx" SG_ 1056 SelDrvMdePos05_B_Avail 1;
BA_ "U_CX482_CX483_MY20_Diesel_Tx" SG_ 1056 SelDrvMdePos05_B_Avail 1;
BA_ "U_U611_U625_MY20_Hev_Tx" SG_ 1056 SelDrvMdePos05_B_Avail 1;
BA_ "U_U611_U625_MY20_Gas_Tx" SG_ 1056 SelDrvMdePos05_B_Avail 1;
BA_ "U_U611_U625_MY20_Diesel_Tx" SG_ 1056 SelDrvMdePos05_B_Avail 1;
BA_ "U_C519_MY18_5_Gas_Tx" SG_ 1056 SelDrvMdePos05_B_Avail 1;
BA_ "U_C519_MY18_5_Diesel_Tx" SG_ 1056 SelDrvMdePos05_B_Avail 1;
BA_ "GenSigSendType" SG_ 1056 SelDrvMdePos05_B_Avail 3;
BA_ "U_CX482_CX483_MY20_Hev_Tx" SG_ 1056 SelDrvMdePos04_B_Avail 1;
BA_ "U_CX482_CX483_MY20_Gas_Tx" SG_ 1056 SelDrvMdePos04_B_Avail 1;
BA_ "U_CX482_CX483_MY20_Diesel_Tx" SG_ 1056 SelDrvMdePos04_B_Avail 1;
BA_ "U_U611_U625_MY20_Hev_Tx" SG_ 1056 SelDrvMdePos04_B_Avail 1;
BA_ "U_U611_U625_MY20_Gas_Tx" SG_ 1056 SelDrvMdePos04_B_Avail 1;
BA_ "U_U611_U625_MY20_Diesel_Tx" SG_ 1056 SelDrvMdePos04_B_Avail 1;
BA_ "U_C519_MY18_5_Gas_Tx" SG_ 1056 SelDrvMdePos04_B_Avail 1;
BA_ "U_C519_MY18_5_Diesel_Tx" SG_ 1056 SelDrvMdePos04_B_Avail 1;
BA_ "GenSigSendType" SG_ 1056 SelDrvMdePos04_B_Avail 3;
BA_ "U_CX482_CX483_MY20_Hev_Tx" SG_ 1056 SelDrvMdePos03_B_Avail 1;
BA_ "U_CX482_CX483_MY20_Gas_Tx" SG_ 1056 SelDrvMdePos03_B_Avail 1;
BA_ "U_CX482_CX483_MY20_Diesel_Tx" SG_ 1056 SelDrvMdePos03_B_Avail 1;
BA_ "U_U611_U625_MY20_Hev_Tx" SG_ 1056 SelDrvMdePos03_B_Avail 1;
BA_ "U_U611_U625_MY20_Gas_Tx" SG_ 1056 SelDrvMdePos03_B_Avail 1;
BA_ "U_U611_U625_MY20_Diesel_Tx" SG_ 1056 SelDrvMdePos03_B_Avail 1;
BA_ "U_C519_MY18_5_Gas_Tx" SG_ 1056 SelDrvMdePos03_B_Avail 1;
BA_ "U_C519_MY18_5_Diesel_Tx" SG_ 1056 SelDrvMdePos03_B_Avail 1;
BA_ "GenSigSendType" SG_ 1056 SelDrvMdePos03_B_Avail 3;
BA_ "U_CX482_CX483_MY20_Hev_Tx" SG_ 1056 SelDrvMdePos02_B_Avail 1;
BA_ "U_CX482_CX483_MY20_Gas_Tx" SG_ 1056 SelDrvMdePos02_B_Avail 1;
BA_ "U_CX482_CX483_MY20_Diesel_Tx" SG_ 1056 SelDrvMdePos02_B_Avail 1;
BA_ "U_U611_U625_MY20_Hev_Tx" SG_ 1056 SelDrvMdePos02_B_Avail 1;
BA_ "U_U611_U625_MY20_Gas_Tx" SG_ 1056 SelDrvMdePos02_B_Avail 1;
BA_ "U_U611_U625_MY20_Diesel_Tx" SG_ 1056 SelDrvMdePos02_B_Avail 1;
BA_ "U_C519_MY18_5_Gas_Tx" SG_ 1056 SelDrvMdePos02_B_Avail 1;
BA_ "U_C519_MY18_5_Diesel_Tx" SG_ 1056 SelDrvMdePos02_B_Avail 1;
BA_ "GenSigSendType" SG_ 1056 SelDrvMdePos02_B_Avail 3;
BA_ "U_CX482_CX483_MY20_Hev_Tx" SG_ 1056 SelDrvMdePos01_B_Avail 1;
BA_ "U_CX482_CX483_MY20_Gas_Tx" SG_ 1056 SelDrvMdePos01_B_Avail 1;
BA_ "U_CX482_CX483_MY20_Diesel_Tx" SG_ 1056 SelDrvMdePos01_B_Avail 1;
BA_ "U_U611_U625_MY20_Hev_Tx" SG_ 1056 SelDrvMdePos01_B_Avail 1;
BA_ "U_U611_U625_MY20_Gas_Tx" SG_ 1056 SelDrvMdePos01_B_Avail 1;
BA_ "U_U611_U625_MY20_Diesel_Tx" SG_ 1056 SelDrvMdePos01_B_Avail 1;
BA_ "U_C519_MY18_5_Gas_Tx" SG_ 1056 SelDrvMdePos01_B_Avail 1;
BA_ "U_C519_MY18_5_Diesel_Tx" SG_ 1056 SelDrvMdePos01_B_Avail 1;
BA_ "GenSigSendType" SG_ 1056 SelDrvMdePos01_B_Avail 3;
BA_ "U_CX482_CX483_MY20_Hev_Tx" SG_ 1056 ActvDrvMde_D2_Stat 1;
BA_ "U_CX482_CX483_MY20_Gas_Tx" SG_ 1056 ActvDrvMde_D2_Stat 1;
BA_ "U_CX482_CX483_MY20_Diesel_Tx" SG_ 1056 ActvDrvMde_D2_Stat 1;
BA_ "U_U611_U625_MY20_Hev_Tx" SG_ 1056 ActvDrvMde_D2_Stat 1;
BA_ "U_U611_U625_MY20_Gas_Tx" SG_ 1056 ActvDrvMde_D2_Stat 1;
BA_ "U_U611_U625_MY20_Diesel_Tx" SG_ 1056 ActvDrvMde_D2_Stat 1;
BA_ "U_C519_MY18_5_Gas_Tx" SG_ 1056 ActvDrvMde_D2_Stat 1;
BA_ "U_C519_MY18_5_Diesel_Tx" SG_ 1056 ActvDrvMde_D2_Stat 1;
BA_ "U_U611_U625_MY20_Hev_Rx" SG_ 1056 ActvDrvMde_D2_Stat 1;
BA_ "U_U611_U625_MY20_Gas_Rx" SG_ 1056 ActvDrvMde_D2_Stat 1;
BA_ "U_U611_U625_MY20_Diesel_Rx" SG_ 1056 ActvDrvMde_D2_Stat 1;
BA_ "U_C519_MY18_5_Gas_Rx" SG_ 1056 ActvDrvMde_D2_Stat 1;
BA_ "U_C519_MY18_5_Diesel_Rx" SG_ 1056 ActvDrvMde_D2_Stat 1;
BA_ "GenSigSendType" SG_ 1056 ActvDrvMde_D2_Stat 3;
BA_ "GenSigStartValue" SG_ 1056 ActvDrvMde_D2_Stat 31;
BA_ "U_CX482_CX483_MY20_Hev_Tx" SG_ 1056 SelDrvMde_D2_Rq 1;
BA_ "U_CX482_CX483_MY20_Gas_Tx" SG_ 1056 SelDrvMde_D2_Rq 1;
BA_ "U_CX482_CX483_MY20_Diesel_Tx" SG_ 1056 SelDrvMde_D2_Rq 1;
BA_ "U_U611_U625_MY20_Hev_Tx" SG_ 1056 SelDrvMde_D2_Rq 1;
BA_ "U_U611_U625_MY20_Gas_Tx" SG_ 1056 SelDrvMde_D2_Rq 1;
BA_ "U_U611_U625_MY20_Diesel_Tx" SG_ 1056 SelDrvMde_D2_Rq 1;
BA_ "U_C490_MY18_Tx" SG_ 1056 SelDrvMde_D2_Rq 1;
BA_ "U_C519_MY18_5_Gas_Tx" SG_ 1056 SelDrvMde_D2_Rq 1;
BA_ "U_C519_MY18_5_Diesel_Tx" SG_ 1056 SelDrvMde_D2_Rq 1;
BA_ "GenSigSendType" SG_ 1056 SelDrvMde_D2_Rq 3;
BA_ "GenSigStartValue" SG_ 1056 SelDrvMde_D2_Rq 31;
BA_ "U_LC1_B500_MY18_Gas_Tx" SG_ 1056 ActvDrvMde_D_Stat 1;
BA_ "U_LC1_B500_MY18_Diesel_Tx" SG_ 1056 ActvDrvMde_D_Stat 1;
BA_ "U_CX482_CX483_MY20_Hev_Tx" SG_ 1056 ActvDrvMde_D_Stat 1;
BA_ "U_CX482_CX483_MY20_Gas_Tx" SG_ 1056 ActvDrvMde_D_Stat 1;
BA_ "U_CX482_CX483_MY20_Diesel_Tx" SG_ 1056 ActvDrvMde_D_Stat 1;
BA_ "U_U611_U625_MY20_Hev_Tx" SG_ 1056 ActvDrvMde_D_Stat 1;
BA_ "U_U611_U625_MY20_Gas_Tx" SG_ 1056 ActvDrvMde_D_Stat 1;
BA_ "U_U611_U625_MY20_Diesel_Tx" SG_ 1056 ActvDrvMde_D_Stat 1;
BA_ "U_B500_MY18_Diesel_Tx" SG_ 1056 ActvDrvMde_D_Stat 1;
BA_ "U_B500_MY18_Gas_Tx" SG_ 1056 ActvDrvMde_D_Stat 1;
BA_ "U_C519_MY18_5_Gas_Tx" SG_ 1056 ActvDrvMde_D_Stat 1;
BA_ "U_C519_MY18_5_Diesel_Tx" SG_ 1056 ActvDrvMde_D_Stat 1;
BA_ "U_B479_MY17_Diesel_Tx" SG_ 1056 ActvDrvMde_D_Stat 1;
BA_ "U_B479_MY17_Gas_Tx" SG_ 1056 ActvDrvMde_D_Stat 1;
BA_ "GenSigSendType" SG_ 1056 ActvDrvMde_D_Stat 3;
BA_ "U_LC1_B500_MY18_Gas_Tx" SG_ 1056 SelDrvMdePt_D_Rq 1;
BA_ "U_LC1_B500_MY18_Diesel_Tx" SG_ 1056 SelDrvMdePt_D_Rq 1;
BA_ "U_CX482_CX483_MY20_Hev_Tx" SG_ 1056 SelDrvMdePt_D_Rq 1;
BA_ "U_CX482_CX483_MY20_Gas_Tx" SG_ 1056 SelDrvMdePt_D_Rq 1;
BA_ "U_CX482_CX483_MY20_Diesel_Tx" SG_ 1056 SelDrvMdePt_D_Rq 1;
BA_ "U_U611_U625_MY20_Hev_Tx" SG_ 1056 SelDrvMdePt_D_Rq 1;
BA_ "U_U611_U625_MY20_Gas_Tx" SG_ 1056 SelDrvMdePt_D_Rq 1;
BA_ "U_U611_U625_MY20_Diesel_Tx" SG_ 1056 SelDrvMdePt_D_Rq 1;
BA_ "U_B500_MY18_Diesel_Tx" SG_ 1056 SelDrvMdePt_D_Rq 1;
BA_ "U_B500_MY18_Gas_Tx" SG_ 1056 SelDrvMdePt_D_Rq 1;
BA_ "U_C519_MY18_5_Gas_Tx" SG_ 1056 SelDrvMdePt_D_Rq 1;
BA_ "U_C519_MY18_5_Diesel_Tx" SG_ 1056 SelDrvMdePt_D_Rq 1;
BA_ "U_B479_MY17_Diesel_Tx" SG_ 1056 SelDrvMdePt_D_Rq 1;
BA_ "U_B479_MY17_Gas_Tx" SG_ 1056 SelDrvMdePt_D_Rq 1;
BA_ "GenSigSendType" SG_ 1056 SelDrvMdePt_D_Rq 3;
BA_ "U_CX482_CX483_MY20_Hev_Tx" SG_ 1056 SelDrvMdeMsgTxt_D_Rq 1;
BA_ "U_CX482_CX483_MY20_Gas_Tx" SG_ 1056 SelDrvMdeMsgTxt_D_Rq 1;
BA_ "U_CX482_CX483_MY20_Diesel_Tx" SG_ 1056 SelDrvMdeMsgTxt_D_Rq 1;
BA_ "U_U611_U625_MY20_Hev_Tx" SG_ 1056 SelDrvMdeMsgTxt_D_Rq 1;
BA_ "U_U611_U625_MY20_Gas_Tx" SG_ 1056 SelDrvMdeMsgTxt_D_Rq 1;
BA_ "U_U611_U625_MY20_Diesel_Tx" SG_ 1056 SelDrvMdeMsgTxt_D_Rq 1;
BA_ "U_C519_MY18_5_Gas_Tx" SG_ 1056 SelDrvMdeMsgTxt_D_Rq 1;
BA_ "U_C519_MY18_5_Diesel_Tx" SG_ 1056 SelDrvMdeMsgTxt_D_Rq 1;
BA_ "U_B479_MY17_Diesel_Tx" SG_ 1056 SelDrvMdeMsgTxt_D_Rq 1;
BA_ "U_B479_MY17_Gas_Tx" SG_ 1056 SelDrvMdeMsgTxt_D_Rq 1;
BA_ "GenSigSendType" SG_ 1056 SelDrvMdeMsgTxt_D_Rq 3;
BA_ "U_CX482_CX483_MY20_Hev_Tx" SG_ 1056 SelDrvMde_D_Stat 1;
BA_ "U_CX482_CX483_MY20_Gas_Tx" SG_ 1056 SelDrvMde_D_Stat 1;
BA_ "U_CX482_CX483_MY20_Diesel_Tx" SG_ 1056 SelDrvMde_D_Stat 1;
BA_ "U_U611_U625_MY20_Hev_Tx" SG_ 1056 SelDrvMde_D_Stat 1;
BA_ "U_U611_U625_MY20_Gas_Tx" SG_ 1056 SelDrvMde_D_Stat 1;
BA_ "U_U611_U625_MY20_Diesel_Tx" SG_ 1056 SelDrvMde_D_Stat 1;
BA_ "U_C519_MY18_5_Gas_Tx" SG_ 1056 SelDrvMde_D_Stat 1;
BA_ "U_C519_MY18_5_Diesel_Tx" SG_ 1056 SelDrvMde_D_Stat 1;
BA_ "U_B479_MY17_Diesel_Tx" SG_ 1056 SelDrvMde_D_Stat 1;
BA_ "U_B479_MY17_Gas_Tx" SG_ 1056 SelDrvMde_D_Stat 1;
BA_ "GenSigSendType" SG_ 1056 SelDrvMde_D_Stat 3;
BA_ "U_CX482_CX483_MY20_Hev_Tx" SG_ 1056 SelDrvMde_D_Rq 1;
BA_ "U_CX482_CX483_MY20_Gas_Tx" SG_ 1056 SelDrvMde_D_Rq 1;
BA_ "U_CX482_CX483_MY20_Diesel_Tx" SG_ 1056 SelDrvMde_D_Rq 1;
BA_ "U_U611_U625_MY20_Hev_Tx" SG_ 1056 SelDrvMde_D_Rq 1;
BA_ "U_U611_U625_MY20_Gas_Tx" SG_ 1056 SelDrvMde_D_Rq 1;
BA_ "U_U611_U625_MY20_Diesel_Tx" SG_ 1056 SelDrvMde_D_Rq 1;
BA_ "U_C519_MY18_5_Gas_Tx" SG_ 1056 SelDrvMde_D_Rq 1;
BA_ "U_C519_MY18_5_Diesel_Tx" SG_ 1056 SelDrvMde_D_Rq 1;
BA_ "U_B479_MY17_Diesel_Tx" SG_ 1056 SelDrvMde_D_Rq 1;
BA_ "U_B479_MY17_Gas_Tx" SG_ 1056 SelDrvMde_D_Rq 1;
BA_ "GenSigSendType" SG_ 1056 SelDrvMde_D_Rq 3;
BA_ "U_CX482_CX483_MY20_Hev_Tx" SG_ 1056 SelDrvMde16_B_Avail 1;
BA_ "U_CX482_CX483_MY20_Gas_Tx" SG_ 1056 SelDrvMde16_B_Avail 1;
BA_ "U_CX482_CX483_MY20_Diesel_Tx" SG_ 1056 SelDrvMde16_B_Avail 1;
BA_ "U_C519_MY18_5_Gas_Tx" SG_ 1056 SelDrvMde16_B_Avail 1;
BA_ "U_C519_MY18_5_Diesel_Tx" SG_ 1056 SelDrvMde16_B_Avail 1;
BA_ "U_B479_MY17_Diesel_Tx" SG_ 1056 SelDrvMde16_B_Avail 1;
BA_ "U_B479_MY17_Gas_Tx" SG_ 1056 SelDrvMde16_B_Avail 1;
BA_ "GenSigSendType" SG_ 1056 SelDrvMde16_B_Avail 3;
BA_ "U_CX482_CX483_MY20_Hev_Tx" SG_ 1056 SelDrvMde15_B_Avail 1;
BA_ "U_CX482_CX483_MY20_Gas_Tx" SG_ 1056 SelDrvMde15_B_Avail 1;
BA_ "U_CX482_CX483_MY20_Diesel_Tx" SG_ 1056 SelDrvMde15_B_Avail 1;
BA_ "U_C519_MY18_5_Gas_Tx" SG_ 1056 SelDrvMde15_B_Avail 1;
BA_ "U_C519_MY18_5_Diesel_Tx" SG_ 1056 SelDrvMde15_B_Avail 1;
BA_ "U_B479_MY17_Diesel_Tx" SG_ 1056 SelDrvMde15_B_Avail 1;
BA_ "U_B479_MY17_Gas_Tx" SG_ 1056 SelDrvMde15_B_Avail 1;
BA_ "GenSigSendType" SG_ 1056 SelDrvMde15_B_Avail 3;
BA_ "U_CX482_CX483_MY20_Hev_Tx" SG_ 1056 SelDrvMde14_B_Avail 1;
BA_ "U_CX482_CX483_MY20_Gas_Tx" SG_ 1056 SelDrvMde14_B_Avail 1;
BA_ "U_CX482_CX483_MY20_Diesel_Tx" SG_ 1056 SelDrvMde14_B_Avail 1;
BA_ "U_C519_MY18_5_Gas_Tx" SG_ 1056 SelDrvMde14_B_Avail 1;
BA_ "U_C519_MY18_5_Diesel_Tx" SG_ 1056 SelDrvMde14_B_Avail 1;
BA_ "U_B479_MY17_Diesel_Tx" SG_ 1056 SelDrvMde14_B_Avail 1;
BA_ "U_B479_MY17_Gas_Tx" SG_ 1056 SelDrvMde14_B_Avail 1;
BA_ "GenSigSendType" SG_ 1056 SelDrvMde14_B_Avail 3;
BA_ "U_CX482_CX483_MY20_Hev_Tx" SG_ 1056 SelDrvMde13_B_Avail 1;
BA_ "U_CX482_CX483_MY20_Gas_Tx" SG_ 1056 SelDrvMde13_B_Avail 1;
BA_ "U_CX482_CX483_MY20_Diesel_Tx" SG_ 1056 SelDrvMde13_B_Avail 1;
BA_ "U_C519_MY18_5_Gas_Tx" SG_ 1056 SelDrvMde13_B_Avail 1;
BA_ "U_C519_MY18_5_Diesel_Tx" SG_ 1056 SelDrvMde13_B_Avail 1;
BA_ "U_B479_MY17_Diesel_Tx" SG_ 1056 SelDrvMde13_B_Avail 1;
BA_ "U_B479_MY17_Gas_Tx" SG_ 1056 SelDrvMde13_B_Avail 1;
BA_ "GenSigSendType" SG_ 1056 SelDrvMde13_B_Avail 3;
BA_ "U_CX482_CX483_MY20_Hev_Tx" SG_ 1056 SelDrvMde12_B_Avail 1;
BA_ "U_CX482_CX483_MY20_Gas_Tx" SG_ 1056 SelDrvMde12_B_Avail 1;
BA_ "U_CX482_CX483_MY20_Diesel_Tx" SG_ 1056 SelDrvMde12_B_Avail 1;
BA_ "U_C519_MY18_5_Gas_Tx" SG_ 1056 SelDrvMde12_B_Avail 1;
BA_ "U_C519_MY18_5_Diesel_Tx" SG_ 1056 SelDrvMde12_B_Avail 1;
BA_ "U_B479_MY17_Diesel_Tx" SG_ 1056 SelDrvMde12_B_Avail 1;
BA_ "U_B479_MY17_Gas_Tx" SG_ 1056 SelDrvMde12_B_Avail 1;
BA_ "GenSigSendType" SG_ 1056 SelDrvMde12_B_Avail 3;
BA_ "U_CX482_CX483_MY20_Hev_Tx" SG_ 1056 SelDrvMde11_B_Avail 1;
BA_ "U_CX482_CX483_MY20_Gas_Tx" SG_ 1056 SelDrvMde11_B_Avail 1;
BA_ "U_CX482_CX483_MY20_Diesel_Tx" SG_ 1056 SelDrvMde11_B_Avail 1;
BA_ "U_C519_MY18_5_Gas_Tx" SG_ 1056 SelDrvMde11_B_Avail 1;
BA_ "U_C519_MY18_5_Diesel_Tx" SG_ 1056 SelDrvMde11_B_Avail 1;
BA_ "U_B479_MY17_Diesel_Tx" SG_ 1056 SelDrvMde11_B_Avail 1;
BA_ "U_B479_MY17_Gas_Tx" SG_ 1056 SelDrvMde11_B_Avail 1;
BA_ "GenSigSendType" SG_ 1056 SelDrvMde11_B_Avail 3;
BA_ "U_CX482_CX483_MY20_Hev_Tx" SG_ 1056 SelDrvMde10_B_Avail 1;
BA_ "U_CX482_CX483_MY20_Gas_Tx" SG_ 1056 SelDrvMde10_B_Avail 1;
BA_ "U_CX482_CX483_MY20_Diesel_Tx" SG_ 1056 SelDrvMde10_B_Avail 1;
BA_ "U_C519_MY18_5_Gas_Tx" SG_ 1056 SelDrvMde10_B_Avail 1;
BA_ "U_C519_MY18_5_Diesel_Tx" SG_ 1056 SelDrvMde10_B_Avail 1;
BA_ "U_B479_MY17_Diesel_Tx" SG_ 1056 SelDrvMde10_B_Avail 1;
BA_ "U_B479_MY17_Gas_Tx" SG_ 1056 SelDrvMde10_B_Avail 1;
BA_ "GenSigSendType" SG_ 1056 SelDrvMde10_B_Avail 3;
BA_ "U_CX482_CX483_MY20_Hev_Tx" SG_ 1056 SelDrvMde09_B_Avail 1;
BA_ "U_CX482_CX483_MY20_Gas_Tx" SG_ 1056 SelDrvMde09_B_Avail 1;
BA_ "U_CX482_CX483_MY20_Diesel_Tx" SG_ 1056 SelDrvMde09_B_Avail 1;
BA_ "U_C519_MY18_5_Gas_Tx" SG_ 1056 SelDrvMde09_B_Avail 1;
BA_ "U_C519_MY18_5_Diesel_Tx" SG_ 1056 SelDrvMde09_B_Avail 1;
BA_ "U_B479_MY17_Diesel_Tx" SG_ 1056 SelDrvMde09_B_Avail 1;
BA_ "U_B479_MY17_Gas_Tx" SG_ 1056 SelDrvMde09_B_Avail 1;
BA_ "GenSigSendType" SG_ 1056 SelDrvMde09_B_Avail 3;
BA_ "U_CX482_CX483_MY20_Hev_Tx" SG_ 1056 SelDrvMde08_B_Avail 1;
BA_ "U_CX482_CX483_MY20_Gas_Tx" SG_ 1056 SelDrvMde08_B_Avail 1;
BA_ "U_CX482_CX483_MY20_Diesel_Tx" SG_ 1056 SelDrvMde08_B_Avail 1;
BA_ "U_C519_MY18_5_Gas_Tx" SG_ 1056 SelDrvMde08_B_Avail 1;
BA_ "U_C519_MY18_5_Diesel_Tx" SG_ 1056 SelDrvMde08_B_Avail 1;
BA_ "U_B479_MY17_Diesel_Tx" SG_ 1056 SelDrvMde08_B_Avail 1;
BA_ "U_B479_MY17_Gas_Tx" SG_ 1056 SelDrvMde08_B_Avail 1;
BA_ "GenSigSendType" SG_ 1056 SelDrvMde08_B_Avail 3;
BA_ "U_CX482_CX483_MY20_Hev_Tx" SG_ 1056 SelDrvMde07_B_Avail 1;
BA_ "U_CX482_CX483_MY20_Gas_Tx" SG_ 1056 SelDrvMde07_B_Avail 1;
BA_ "U_CX482_CX483_MY20_Diesel_Tx" SG_ 1056 SelDrvMde07_B_Avail 1;
BA_ "U_C519_MY18_5_Gas_Tx" SG_ 1056 SelDrvMde07_B_Avail 1;
BA_ "U_C519_MY18_5_Diesel_Tx" SG_ 1056 SelDrvMde07_B_Avail 1;
BA_ "U_B479_MY17_Diesel_Tx" SG_ 1056 SelDrvMde07_B_Avail 1;
BA_ "U_B479_MY17_Gas_Tx" SG_ 1056 SelDrvMde07_B_Avail 1;
BA_ "GenSigSendType" SG_ 1056 SelDrvMde07_B_Avail 3;
BA_ "U_CX482_CX483_MY20_Hev_Tx" SG_ 1056 SelDrvMde06_B_Avail 1;
BA_ "U_CX482_CX483_MY20_Gas_Tx" SG_ 1056 SelDrvMde06_B_Avail 1;
BA_ "U_CX482_CX483_MY20_Diesel_Tx" SG_ 1056 SelDrvMde06_B_Avail 1;
BA_ "U_C519_MY18_5_Gas_Tx" SG_ 1056 SelDrvMde06_B_Avail 1;
BA_ "U_C519_MY18_5_Diesel_Tx" SG_ 1056 SelDrvMde06_B_Avail 1;
BA_ "U_B479_MY17_Diesel_Tx" SG_ 1056 SelDrvMde06_B_Avail 1;
BA_ "U_B479_MY17_Gas_Tx" SG_ 1056 SelDrvMde06_B_Avail 1;
BA_ "GenSigSendType" SG_ 1056 SelDrvMde06_B_Avail 3;
BA_ "U_CX482_CX483_MY20_Hev_Tx" SG_ 1056 SelDrvMde05_B_Avail 1;
BA_ "U_CX482_CX483_MY20_Gas_Tx" SG_ 1056 SelDrvMde05_B_Avail 1;
BA_ "U_CX482_CX483_MY20_Diesel_Tx" SG_ 1056 SelDrvMde05_B_Avail 1;
BA_ "U_C519_MY18_5_Gas_Tx" SG_ 1056 SelDrvMde05_B_Avail 1;
BA_ "U_C519_MY18_5_Diesel_Tx" SG_ 1056 SelDrvMde05_B_Avail 1;
BA_ "U_B479_MY17_Diesel_Tx" SG_ 1056 SelDrvMde05_B_Avail 1;
BA_ "U_B479_MY17_Gas_Tx" SG_ 1056 SelDrvMde05_B_Avail 1;
BA_ "GenSigSendType" SG_ 1056 SelDrvMde05_B_Avail 3;
BA_ "U_CX482_CX483_MY20_Hev_Tx" SG_ 1056 SelDrvMde04_B_Avail 1;
BA_ "U_CX482_CX483_MY20_Gas_Tx" SG_ 1056 SelDrvMde04_B_Avail 1;
BA_ "U_CX482_CX483_MY20_Diesel_Tx" SG_ 1056 SelDrvMde04_B_Avail 1;
BA_ "U_C519_MY18_5_Gas_Tx" SG_ 1056 SelDrvMde04_B_Avail 1;
BA_ "U_C519_MY18_5_Diesel_Tx" SG_ 1056 SelDrvMde04_B_Avail 1;
BA_ "U_B479_MY17_Diesel_Tx" SG_ 1056 SelDrvMde04_B_Avail 1;
BA_ "U_B479_MY17_Gas_Tx" SG_ 1056 SelDrvMde04_B_Avail 1;
BA_ "GenSigSendType" SG_ 1056 SelDrvMde04_B_Avail 3;
BA_ "U_CX482_CX483_MY20_Hev_Tx" SG_ 1056 SelDrvMde03_B_Avail 1;
BA_ "U_CX482_CX483_MY20_Gas_Tx" SG_ 1056 SelDrvMde03_B_Avail 1;
BA_ "U_CX482_CX483_MY20_Diesel_Tx" SG_ 1056 SelDrvMde03_B_Avail 1;
BA_ "U_C519_MY18_5_Gas_Tx" SG_ 1056 SelDrvMde03_B_Avail 1;
BA_ "U_C519_MY18_5_Diesel_Tx" SG_ 1056 SelDrvMde03_B_Avail 1;
BA_ "U_B479_MY17_Diesel_Tx" SG_ 1056 SelDrvMde03_B_Avail 1;
BA_ "U_B479_MY17_Gas_Tx" SG_ 1056 SelDrvMde03_B_Avail 1;
BA_ "GenSigSendType" SG_ 1056 SelDrvMde03_B_Avail 3;
BA_ "U_CX482_CX483_MY20_Hev_Tx" SG_ 1056 SelDrvMde02_B_Avail 1;
BA_ "U_CX482_CX483_MY20_Gas_Tx" SG_ 1056 SelDrvMde02_B_Avail 1;
BA_ "U_CX482_CX483_MY20_Diesel_Tx" SG_ 1056 SelDrvMde02_B_Avail 1;
BA_ "U_C519_MY18_5_Gas_Tx" SG_ 1056 SelDrvMde02_B_Avail 1;
BA_ "U_C519_MY18_5_Diesel_Tx" SG_ 1056 SelDrvMde02_B_Avail 1;
BA_ "U_B479_MY17_Diesel_Tx" SG_ 1056 SelDrvMde02_B_Avail 1;
BA_ "U_B479_MY17_Gas_Tx" SG_ 1056 SelDrvMde02_B_Avail 1;
BA_ "GenSigSendType" SG_ 1056 SelDrvMde02_B_Avail 3;
BA_ "U_CX482_CX483_MY20_Hev_Tx" SG_ 1056 SelDrvMde01_B_Avail 1;
BA_ "U_CX482_CX483_MY20_Gas_Tx" SG_ 1056 SelDrvMde01_B_Avail 1;
BA_ "U_CX482_CX483_MY20_Diesel_Tx" SG_ 1056 SelDrvMde01_B_Avail 1;
BA_ "U_C519_MY18_5_Gas_Tx" SG_ 1056 SelDrvMde01_B_Avail 1;
BA_ "U_C519_MY18_5_Diesel_Tx" SG_ 1056 SelDrvMde01_B_Avail 1;
BA_ "U_B479_MY17_Diesel_Tx" SG_ 1056 SelDrvMde01_B_Avail 1;
BA_ "U_B479_MY17_Gas_Tx" SG_ 1056 SelDrvMde01_B_Avail 1;
BA_ "GenSigSendType" SG_ 1056 SelDrvMde01_B_Avail 3;
BA_ "U_U611_U625_MY20_Hev_Tx" SG_ 1056 AwdMde_D_RqBrk 1;
BA_ "U_U611_U625_MY20_Gas_Tx" SG_ 1056 AwdMde_D_RqBrk 1;
BA_ "U_U611_U625_MY20_Diesel_Tx" SG_ 1056 AwdMde_D_RqBrk 1;
BA_ "GenSigSendType" SG_ 1056 AwdMde_D_RqBrk 3;
BA_ "GenSigStartValue" SG_ 1056 AwdMde_D_RqBrk 5;
BA_ "U_CX482_CX483_MY20_Hev_Rx" SG_ 1215 EhData2_No_Actl 1;
BA_ "U_CX482_CX483_MY20_Gas_Rx" SG_ 1215 EhData2_No_Actl 1;
BA_ "U_CX482_CX483_MY20_Diesel_Rx" SG_ 1215 EhData2_No_Actl 1;
BA_ "U_U611_U625_MY20_Hev_Rx" SG_ 1215 EhData2_No_Actl 1;
BA_ "U_U611_U625_MY20_Gas_Rx" SG_ 1215 EhData2_No_Actl 1;
BA_ "U_U611_U625_MY20_Diesel_Rx" SG_ 1215 EhData2_No_Actl 1;
BA_ "U_C519_MY18_5_Gas_Rx" SG_ 1215 EhData2_No_Actl 1;
BA_ "U_C519_MY18_5_Diesel_Rx" SG_ 1215 EhData2_No_Actl 1;
BA_ "U_B479_MY17_Diesel_Rx" SG_ 1215 EhData2_No_Actl 1;
BA_ "U_B479_MY17_Gas_Rx" SG_ 1215 EhData2_No_Actl 1;
BA_ "CrossOver_InfoCAN" SG_ 1215 EhData2_No_Actl 1;
BA_ "U_CX482_CX483_MY20_Hev_Rx" SG_ 1214 EhData1_No_Actl 1;
BA_ "U_CX482_CX483_MY20_Gas_Rx" SG_ 1214 EhData1_No_Actl 1;
BA_ "U_CX482_CX483_MY20_Diesel_Rx" SG_ 1214 EhData1_No_Actl 1;
BA_ "U_U611_U625_MY20_Hev_Rx" SG_ 1214 EhData1_No_Actl 1;
BA_ "U_U611_U625_MY20_Gas_Rx" SG_ 1214 EhData1_No_Actl 1;
BA_ "U_U611_U625_MY20_Diesel_Rx" SG_ 1214 EhData1_No_Actl 1;
BA_ "U_C519_MY18_5_Gas_Rx" SG_ 1214 EhData1_No_Actl 1;
BA_ "U_C519_MY18_5_Diesel_Rx" SG_ 1214 EhData1_No_Actl 1;
BA_ "U_B479_MY17_Diesel_Rx" SG_ 1214 EhData1_No_Actl 1;
BA_ "U_B479_MY17_Gas_Rx" SG_ 1214 EhData1_No_Actl 1;
BA_ "CrossOver_InfoCAN" SG_ 1214 EhData1_No_Actl 1;
BA_ "U_U611_U625_MY20_Phev_Tx" SG_ 673 ICI_Coding_BtnID_D 1;
BA_ "U_CX482_CX483_MY20_Hev_Tx" SG_ 673 ICI_Coding_BtnID_D 1;
BA_ "U_CX482_CX483_MY20_Gas_Tx" SG_ 673 ICI_Coding_BtnID_D 1;
BA_ "U_CX482_CX483_MY20_Diesel_Tx" SG_ 673 ICI_Coding_BtnID_D 1;
BA_ "U_U611_U625_MY20_Hev_Tx" SG_ 673 ICI_Coding_BtnID_D 1;
BA_ "U_U611_U625_MY20_Gas_Tx" SG_ 673 ICI_Coding_BtnID_D 1;
BA_ "U_U611_U625_MY20_Diesel_Tx" SG_ 673 ICI_Coding_BtnID_D 1;
BA_ "U_B500_MY18_Diesel_Tx" SG_ 673 ICI_Coding_BtnID_D 1;
BA_ "U_B500_MY18_Gas_Tx" SG_ 673 ICI_Coding_BtnID_D 1;
BA_ "U_C519_MY18_5_Gas_Tx" SG_ 673 ICI_Coding_BtnID_D 1;
BA_ "U_C519_MY18_5_Diesel_Tx" SG_ 673 ICI_Coding_BtnID_D 1;
BA_ "U_B515_MCA_MY17_Gas_Tx" SG_ 673 ICI_Coding_BtnID_D 1;
BA_ "U_B515_MCA_MY17_Diesel_Tx" SG_ 673 ICI_Coding_BtnID_D 1;
BA_ "U_B479_MY17_Diesel_Tx" SG_ 673 ICI_Coding_BtnID_D 1;
BA_ "U_B479_MY17_Gas_Tx" SG_ 673 ICI_Coding_BtnID_D 1;
BA_ "GenSigSendType" SG_ 673 ICI_Coding_BtnID_D 3;
BA_ "CrossOver_InfoCAN" SG_ 673 ICI_Coding_BtnID_D 1;
BA_ "U_U611_U625_MY20_Phev_Tx" SG_ 673 ICI_Coding_BtnID_C 1;
BA_ "U_CX482_CX483_MY20_Hev_Tx" SG_ 673 ICI_Coding_BtnID_C 1;
BA_ "U_CX482_CX483_MY20_Gas_Tx" SG_ 673 ICI_Coding_BtnID_C 1;
BA_ "U_CX482_CX483_MY20_Diesel_Tx" SG_ 673 ICI_Coding_BtnID_C 1;
BA_ "U_U611_U625_MY20_Hev_Tx" SG_ 673 ICI_Coding_BtnID_C 1;
BA_ "U_U611_U625_MY20_Gas_Tx" SG_ 673 ICI_Coding_BtnID_C 1;
BA_ "U_U611_U625_MY20_Diesel_Tx" SG_ 673 ICI_Coding_BtnID_C 1;
BA_ "U_B500_MY18_Diesel_Tx" SG_ 673 ICI_Coding_BtnID_C 1;
BA_ "U_B500_MY18_Gas_Tx" SG_ 673 ICI_Coding_BtnID_C 1;
BA_ "U_C519_MY18_5_Gas_Tx" SG_ 673 ICI_Coding_BtnID_C 1;
BA_ "U_C519_MY18_5_Diesel_Tx" SG_ 673 ICI_Coding_BtnID_C 1;
BA_ "U_B515_MCA_MY17_Gas_Tx" SG_ 673 ICI_Coding_BtnID_C 1;
BA_ "U_B515_MCA_MY17_Diesel_Tx" SG_ 673 ICI_Coding_BtnID_C 1;
BA_ "U_B479_MY17_Diesel_Tx" SG_ 673 ICI_Coding_BtnID_C 1;
BA_ "U_B479_MY17_Gas_Tx" SG_ 673 ICI_Coding_BtnID_C 1;
BA_ "GenSigSendType" SG_ 673 ICI_Coding_BtnID_C 3;
BA_ "CrossOver_InfoCAN" SG_ 673 ICI_Coding_BtnID_C 1;
BA_ "U_U611_U625_MY20_Phev_Tx" SG_ 673 ICI_Coding_BtnID_B 1;
BA_ "U_CX482_CX483_MY20_Hev_Tx" SG_ 673 ICI_Coding_BtnID_B 1;
BA_ "U_CX482_CX483_MY20_Gas_Tx" SG_ 673 ICI_Coding_BtnID_B 1;
BA_ "U_CX482_CX483_MY20_Diesel_Tx" SG_ 673 ICI_Coding_BtnID_B 1;
BA_ "U_U611_U625_MY20_Hev_Tx" SG_ 673 ICI_Coding_BtnID_B 1;
BA_ "U_U611_U625_MY20_Gas_Tx" SG_ 673 ICI_Coding_BtnID_B 1;
BA_ "U_U611_U625_MY20_Diesel_Tx" SG_ 673 ICI_Coding_BtnID_B 1;
BA_ "U_B500_MY18_Diesel_Tx" SG_ 673 ICI_Coding_BtnID_B 1;
BA_ "U_B500_MY18_Gas_Tx" SG_ 673 ICI_Coding_BtnID_B 1;
BA_ "U_C519_MY18_5_Gas_Tx" SG_ 673 ICI_Coding_BtnID_B 1;
BA_ "U_C519_MY18_5_Diesel_Tx" SG_ 673 ICI_Coding_BtnID_B 1;
BA_ "U_B515_MCA_MY17_Gas_Tx" SG_ 673 ICI_Coding_BtnID_B 1;
BA_ "U_B515_MCA_MY17_Diesel_Tx" SG_ 673 ICI_Coding_BtnID_B 1;
BA_ "U_B479_MY17_Diesel_Tx" SG_ 673 ICI_Coding_BtnID_B 1;
BA_ "U_B479_MY17_Gas_Tx" SG_ 673 ICI_Coding_BtnID_B 1;
BA_ "GenSigSendType" SG_ 673 ICI_Coding_BtnID_B 3;
BA_ "CrossOver_InfoCAN" SG_ 673 ICI_Coding_BtnID_B 1;
BA_ "U_U611_U625_MY20_Phev_Tx" SG_ 673 ICI_Coding_BtnID_A 1;
BA_ "U_CX482_CX483_MY20_Hev_Tx" SG_ 673 ICI_Coding_BtnID_A 1;
BA_ "U_CX482_CX483_MY20_Gas_Tx" SG_ 673 ICI_Coding_BtnID_A 1;
BA_ "U_CX482_CX483_MY20_Diesel_Tx" SG_ 673 ICI_Coding_BtnID_A 1;
BA_ "U_U611_U625_MY20_Hev_Tx" SG_ 673 ICI_Coding_BtnID_A 1;
BA_ "U_U611_U625_MY20_Gas_Tx" SG_ 673 ICI_Coding_BtnID_A 1;
BA_ "U_U611_U625_MY20_Diesel_Tx" SG_ 673 ICI_Coding_BtnID_A 1;
BA_ "U_B500_MY18_Diesel_Tx" SG_ 673 ICI_Coding_BtnID_A 1;
BA_ "U_B500_MY18_Gas_Tx" SG_ 673 ICI_Coding_BtnID_A 1;
BA_ "U_C519_MY18_5_Gas_Tx" SG_ 673 ICI_Coding_BtnID_A 1;
BA_ "U_C519_MY18_5_Diesel_Tx" SG_ 673 ICI_Coding_BtnID_A 1;
BA_ "U_B515_MCA_MY17_Gas_Tx" SG_ 673 ICI_Coding_BtnID_A 1;
BA_ "U_B515_MCA_MY17_Diesel_Tx" SG_ 673 ICI_Coding_BtnID_A 1;
BA_ "U_B479_MY17_Diesel_Tx" SG_ 673 ICI_Coding_BtnID_A 1;
BA_ "U_B479_MY17_Gas_Tx" SG_ 673 ICI_Coding_BtnID_A 1;
BA_ "GenSigSendType" SG_ 673 ICI_Coding_BtnID_A 3;
BA_ "CrossOver_InfoCAN" SG_ 673 ICI_Coding_BtnID_A 1;
BA_ "U_U611_U625_MY20_Phev_Tx" SG_ 673 ICI_BtnID_D 1;
BA_ "U_CX482_CX483_MY20_Hev_Tx" SG_ 673 ICI_BtnID_D 1;
BA_ "U_CX482_CX483_MY20_Gas_Tx" SG_ 673 ICI_BtnID_D 1;
BA_ "U_CX482_CX483_MY20_Diesel_Tx" SG_ 673 ICI_BtnID_D 1;
BA_ "U_U611_U625_MY20_Hev_Tx" SG_ 673 ICI_BtnID_D 1;
BA_ "U_U611_U625_MY20_Gas_Tx" SG_ 673 ICI_BtnID_D 1;
BA_ "U_U611_U625_MY20_Diesel_Tx" SG_ 673 ICI_BtnID_D 1;
BA_ "U_B500_MY18_Diesel_Tx" SG_ 673 ICI_BtnID_D 1;
BA_ "U_B500_MY18_Gas_Tx" SG_ 673 ICI_BtnID_D 1;
BA_ "U_C519_MY18_5_Gas_Tx" SG_ 673 ICI_BtnID_D 1;
BA_ "U_C519_MY18_5_Diesel_Tx" SG_ 673 ICI_BtnID_D 1;
BA_ "U_B515_MCA_MY17_Gas_Tx" SG_ 673 ICI_BtnID_D 1;
BA_ "U_B515_MCA_MY17_Diesel_Tx" SG_ 673 ICI_BtnID_D 1;
BA_ "U_B479_MY17_Diesel_Tx" SG_ 673 ICI_BtnID_D 1;
BA_ "U_B479_MY17_Gas_Tx" SG_ 673 ICI_BtnID_D 1;
BA_ "GenSigSendType" SG_ 673 ICI_BtnID_D 3;
BA_ "GenSigStartValue" SG_ 673 ICI_BtnID_D 255;
BA_ "CrossOver_InfoCAN" SG_ 673 ICI_BtnID_D 1;
BA_ "U_U611_U625_MY20_Phev_Tx" SG_ 673 ICI_BtnID_C 1;
BA_ "U_CX482_CX483_MY20_Hev_Tx" SG_ 673 ICI_BtnID_C 1;
BA_ "U_CX482_CX483_MY20_Gas_Tx" SG_ 673 ICI_BtnID_C 1;
BA_ "U_CX482_CX483_MY20_Diesel_Tx" SG_ 673 ICI_BtnID_C 1;
BA_ "U_U611_U625_MY20_Hev_Tx" SG_ 673 ICI_BtnID_C 1;
BA_ "U_U611_U625_MY20_Gas_Tx" SG_ 673 ICI_BtnID_C 1;
BA_ "U_U611_U625_MY20_Diesel_Tx" SG_ 673 ICI_BtnID_C 1;
BA_ "U_B500_MY18_Diesel_Tx" SG_ 673 ICI_BtnID_C 1;
BA_ "U_B500_MY18_Gas_Tx" SG_ 673 ICI_BtnID_C 1;
BA_ "U_C519_MY18_5_Gas_Tx" SG_ 673 ICI_BtnID_C 1;
BA_ "U_C519_MY18_5_Diesel_Tx" SG_ 673 ICI_BtnID_C 1;
BA_ "U_B515_MCA_MY17_Gas_Tx" SG_ 673 ICI_BtnID_C 1;
BA_ "U_B515_MCA_MY17_Diesel_Tx" SG_ 673 ICI_BtnID_C 1;
BA_ "U_B479_MY17_Diesel_Tx" SG_ 673 ICI_BtnID_C 1;
BA_ "U_B479_MY17_Gas_Tx" SG_ 673 ICI_BtnID_C 1;
BA_ "GenSigSendType" SG_ 673 ICI_BtnID_C 3;
BA_ "GenSigStartValue" SG_ 673 ICI_BtnID_C 255;
BA_ "CrossOver_InfoCAN" SG_ 673 ICI_BtnID_C 1;
BA_ "U_U611_U625_MY20_Phev_Tx" SG_ 673 ICI_BtnID_B 1;
BA_ "U_CX482_CX483_MY20_Hev_Tx" SG_ 673 ICI_BtnID_B 1;
BA_ "U_CX482_CX483_MY20_Gas_Tx" SG_ 673 ICI_BtnID_B 1;
BA_ "U_CX482_CX483_MY20_Diesel_Tx" SG_ 673 ICI_BtnID_B 1;
BA_ "U_U611_U625_MY20_Hev_Tx" SG_ 673 ICI_BtnID_B 1;
BA_ "U_U611_U625_MY20_Gas_Tx" SG_ 673 ICI_BtnID_B 1;
BA_ "U_U611_U625_MY20_Diesel_Tx" SG_ 673 ICI_BtnID_B 1;
BA_ "U_B500_MY18_Diesel_Tx" SG_ 673 ICI_BtnID_B 1;
BA_ "U_B500_MY18_Gas_Tx" SG_ 673 ICI_BtnID_B 1;
BA_ "U_C519_MY18_5_Gas_Tx" SG_ 673 ICI_BtnID_B 1;
BA_ "U_C519_MY18_5_Diesel_Tx" SG_ 673 ICI_BtnID_B 1;
BA_ "U_B515_MCA_MY17_Gas_Tx" SG_ 673 ICI_BtnID_B 1;
BA_ "U_B515_MCA_MY17_Diesel_Tx" SG_ 673 ICI_BtnID_B 1;
BA_ "U_B479_MY17_Diesel_Tx" SG_ 673 ICI_BtnID_B 1;
BA_ "U_B479_MY17_Gas_Tx" SG_ 673 ICI_BtnID_B 1;
BA_ "GenSigSendType" SG_ 673 ICI_BtnID_B 3;
BA_ "GenSigStartValue" SG_ 673 ICI_BtnID_B 255;
BA_ "CrossOver_InfoCAN" SG_ 673 ICI_BtnID_B 1;
BA_ "U_U611_U625_MY20_Phev_Tx" SG_ 673 ICI_BtnID_A 1;
BA_ "U_CX482_CX483_MY20_Hev_Tx" SG_ 673 ICI_BtnID_A 1;
BA_ "U_CX482_CX483_MY20_Gas_Tx" SG_ 673 ICI_BtnID_A 1;
BA_ "U_CX482_CX483_MY20_Diesel_Tx" SG_ 673 ICI_BtnID_A 1;
BA_ "U_U611_U625_MY20_Hev_Tx" SG_ 673 ICI_BtnID_A 1;
BA_ "U_U611_U625_MY20_Gas_Tx" SG_ 673 ICI_BtnID_A 1;
BA_ "U_U611_U625_MY20_Diesel_Tx" SG_ 673 ICI_BtnID_A 1;
BA_ "U_B500_MY18_Diesel_Tx" SG_ 673 ICI_BtnID_A 1;
BA_ "U_B500_MY18_Gas_Tx" SG_ 673 ICI_BtnID_A 1;
BA_ "U_C519_MY18_5_Gas_Tx" SG_ 673 ICI_BtnID_A 1;
BA_ "U_C519_MY18_5_Diesel_Tx" SG_ 673 ICI_BtnID_A 1;
BA_ "U_B515_MCA_MY17_Gas_Tx" SG_ 673 ICI_BtnID_A 1;
BA_ "U_B515_MCA_MY17_Diesel_Tx" SG_ 673 ICI_BtnID_A 1;
BA_ "U_B479_MY17_Diesel_Tx" SG_ 673 ICI_BtnID_A 1;
BA_ "U_B479_MY17_Gas_Tx" SG_ 673 ICI_BtnID_A 1;
BA_ "GenSigSendType" SG_ 673 ICI_BtnID_A 3;
BA_ "GenSigStartValue" SG_ 673 ICI_BtnID_A 255;
BA_ "CrossOver_InfoCAN" SG_ 673 ICI_BtnID_A 1;
BA_ "U_U611_U625_MY20_Phev_Rx" SG_ 845 StmsLmbrPsgr_D_Stat 1;
BA_ "U_U611_U625_MY20_Hev_Rx" SG_ 845 StmsLmbrPsgr_D_Stat 1;
BA_ "U_U611_U625_MY20_Gas_Rx" SG_ 845 StmsLmbrPsgr_D_Stat 1;
BA_ "U_U611_U625_MY20_Diesel_Rx" SG_ 845 StmsLmbrPsgr_D_Stat 1;
BA_ "CrossOver_InfoCAN" SG_ 845 StmsLmbrPsgr_D_Stat 1;
BA_ "U_U611_U625_MY20_Phev_Rx" SG_ 845 StmsCshnPsgr_D_Stat 1;
BA_ "U_U611_U625_MY20_Hev_Rx" SG_ 845 StmsCshnPsgr_D_Stat 1;
BA_ "U_U611_U625_MY20_Gas_Rx" SG_ 845 StmsCshnPsgr_D_Stat 1;
BA_ "U_U611_U625_MY20_Diesel_Rx" SG_ 845 StmsCshnPsgr_D_Stat 1;
BA_ "CrossOver_InfoCAN" SG_ 845 StmsCshnPsgr_D_Stat 1;
BA_ "U_U611_U625_MY20_Phev_Rx" SG_ 845 SeatSwtchPsgr_B_Stat 1;
BA_ "U_U611_U625_MY20_Hev_Rx" SG_ 845 SeatSwtchPsgr_B_Stat 1;
BA_ "U_U611_U625_MY20_Gas_Rx" SG_ 845 SeatSwtchPsgr_B_Stat 1;
BA_ "U_U611_U625_MY20_Diesel_Rx" SG_ 845 SeatSwtchPsgr_B_Stat 1;
BA_ "CrossOver_InfoCAN" SG_ 845 SeatSwtchPsgr_B_Stat 1;
BA_ "U_U611_U625_MY20_Phev_Rx" SG_ 845 SeatPPsgr_B_Stat 1;
BA_ "U_U611_U625_MY20_Hev_Rx" SG_ 845 SeatPPsgr_B_Stat 1;
BA_ "U_U611_U625_MY20_Gas_Rx" SG_ 845 SeatPPsgr_B_Stat 1;
BA_ "U_U611_U625_MY20_Diesel_Rx" SG_ 845 SeatPPsgr_B_Stat 1;
BA_ "CrossOver_InfoCAN" SG_ 845 SeatPPsgr_B_Stat 1;
BA_ "U_U611_U625_MY20_Phev_Rx" SG_ 845 SeatFnPsgr_D_Stat 1;
BA_ "U_U611_U625_MY20_Hev_Rx" SG_ 845 SeatFnPsgr_D_Stat 1;
BA_ "U_U611_U625_MY20_Gas_Rx" SG_ 845 SeatFnPsgr_D_Stat 1;
BA_ "U_U611_U625_MY20_Diesel_Rx" SG_ 845 SeatFnPsgr_D_Stat 1;
BA_ "CrossOver_InfoCAN" SG_ 845 SeatFnPsgr_D_Stat 1;
BA_ "CrossOver_InfoCAN" SG_ 845 PsgrMemFeedback_Rsp 1;
BA_ "U_U611_U625_MY20_Phev_Rx" SG_ 850 SeatCshnPsgrRR_Pc_Actl 1;
BA_ "U_U611_U625_MY20_Hev_Rx" SG_ 850 SeatCshnPsgrRR_Pc_Actl 1;
BA_ "U_U611_U625_MY20_Gas_Rx" SG_ 850 SeatCshnPsgrRR_Pc_Actl 1;
BA_ "U_U611_U625_MY20_Diesel_Rx" SG_ 850 SeatCshnPsgrRR_Pc_Actl 1;
BA_ "GenSigStartValue" SG_ 850 SeatCshnPsgrRR_Pc_Actl 127;
BA_ "CrossOver_InfoCAN" SG_ 850 SeatCshnPsgrRR_Pc_Actl 1;
BA_ "U_U611_U625_MY20_Phev_Rx" SG_ 850 SeatCshnPsgrRL_Pc_Actl 1;
BA_ "U_U611_U625_MY20_Hev_Rx" SG_ 850 SeatCshnPsgrRL_Pc_Actl 1;
BA_ "U_U611_U625_MY20_Gas_Rx" SG_ 850 SeatCshnPsgrRL_Pc_Actl 1;
BA_ "U_U611_U625_MY20_Diesel_Rx" SG_ 850 SeatCshnPsgrRL_Pc_Actl 1;
BA_ "GenSigStartValue" SG_ 850 SeatCshnPsgrRL_Pc_Actl 127;
BA_ "CrossOver_InfoCAN" SG_ 850 SeatCshnPsgrRL_Pc_Actl 1;
BA_ "U_U611_U625_MY20_Phev_Rx" SG_ 850 SeatCshnPsgrFR_Pc_Actl 1;
BA_ "U_U611_U625_MY20_Hev_Rx" SG_ 850 SeatCshnPsgrFR_Pc_Actl 1;
BA_ "U_U611_U625_MY20_Gas_Rx" SG_ 850 SeatCshnPsgrFR_Pc_Actl 1;
BA_ "U_U611_U625_MY20_Diesel_Rx" SG_ 850 SeatCshnPsgrFR_Pc_Actl 1;
BA_ "GenSigStartValue" SG_ 850 SeatCshnPsgrFR_Pc_Actl 127;
BA_ "CrossOver_InfoCAN" SG_ 850 SeatCshnPsgrFR_Pc_Actl 1;
BA_ "U_U611_U625_MY20_Phev_Rx" SG_ 850 SeatCshnPsgrFL_Pc_Actl 1;
BA_ "U_U611_U625_MY20_Hev_Rx" SG_ 850 SeatCshnPsgrFL_Pc_Actl 1;
BA_ "U_U611_U625_MY20_Gas_Rx" SG_ 850 SeatCshnPsgrFL_Pc_Actl 1;
BA_ "U_U611_U625_MY20_Diesel_Rx" SG_ 850 SeatCshnPsgrFL_Pc_Actl 1;
BA_ "GenSigStartValue" SG_ 850 SeatCshnPsgrFL_Pc_Actl 127;
BA_ "CrossOver_InfoCAN" SG_ 850 SeatCshnPsgrFL_Pc_Actl 1;
BA_ "GenSigStartValue" SG_ 850 SeatBlLoPsgr_Pc_Actl2 127;
BA_ "CrossOver_InfoCAN" SG_ 850 SeatBlLoPsgr_Pc_Actl2 1;
BA_ "U_CX482_CX483_MY20_Hev_Tx" SG_ 820 AhbStatGfhbFdbk_D_Actl 1;
BA_ "U_CX482_CX483_MY20_Gas_Tx" SG_ 820 AhbStatGfhbFdbk_D_Actl 1;
BA_ "U_CX482_CX483_MY20_Diesel_Tx" SG_ 820 AhbStatGfhbFdbk_D_Actl 1;
BA_ "U_U611_U625_MY20_Hev_Tx" SG_ 820 AhbStatGfhbFdbk_D_Actl 1;
BA_ "U_U611_U625_MY20_Gas_Tx" SG_ 820 AhbStatGfhbFdbk_D_Actl 1;
BA_ "U_U611_U625_MY20_Diesel_Tx" SG_ 820 AhbStatGfhbFdbk_D_Actl 1;
BA_ "U_C519_MY18_5_Gas_Tx" SG_ 820 AhbStatGfhbFdbk_D_Actl 1;
BA_ "U_C519_MY18_5_Diesel_Tx" SG_ 820 AhbStatGfhbFdbk_D_Actl 1;
BA_ "U_U611_U625_MY20_Phev_Rx" SG_ 820 AhbStatGfhbFdbk_D_Actl 1;
BA_ "U_CX482_CX483_MY20_Hev_Rx" SG_ 820 AhbStatGfhbFdbk_D_Actl 1;
BA_ "U_CX482_CX483_MY20_Gas_Rx" SG_ 820 AhbStatGfhbFdbk_D_Actl 1;
BA_ "U_CX482_CX483_MY20_Diesel_Rx" SG_ 820 AhbStatGfhbFdbk_D_Actl 1;
BA_ "U_U611_U625_MY20_Hev_Rx" SG_ 820 AhbStatGfhbFdbk_D_Actl 1;
BA_ "U_U611_U625_MY20_Gas_Rx" SG_ 820 AhbStatGfhbFdbk_D_Actl 1;
BA_ "U_U611_U625_MY20_Diesel_Rx" SG_ 820 AhbStatGfhbFdbk_D_Actl 1;
BA_ "U_B500_MY18_Diesel_Rx" SG_ 820 AhbStatGfhbFdbk_D_Actl 1;
BA_ "U_B500_MY18_Gas_Rx" SG_ 820 AhbStatGfhbFdbk_D_Actl 1;
BA_ "U_C519_MY18_5_Gas_Rx" SG_ 820 AhbStatGfhbFdbk_D_Actl 1;
BA_ "U_C519_MY18_5_Diesel_Rx" SG_ 820 AhbStatGfhbFdbk_D_Actl 1;
BA_ "U_B515_MCA_MY17_Gas_Rx" SG_ 820 AhbStatGfhbFdbk_D_Actl 1;
BA_ "U_B515_MCA_MY17_Diesel_Rx" SG_ 820 AhbStatGfhbFdbk_D_Actl 1;
BA_ "U_B479_MY17_Diesel_Rx" SG_ 820 AhbStatGfhbFdbk_D_Actl 1;
BA_ "U_B479_MY17_Gas_Rx" SG_ 820 AhbStatGfhbFdbk_D_Actl 1;
BA_ "U_CX482_CX483_MY20_Hev_Tx" SG_ 820 HeadLghtDrvSide_B_Stat 1;
BA_ "U_CX482_CX483_MY20_Gas_Tx" SG_ 820 HeadLghtDrvSide_B_Stat 1;
BA_ "U_CX482_CX483_MY20_Diesel_Tx" SG_ 820 HeadLghtDrvSide_B_Stat 1;
BA_ "U_C519_MY18_5_Gas_Tx" SG_ 820 HeadLghtDrvSide_B_Stat 1;
BA_ "U_C519_MY18_5_Diesel_Tx" SG_ 820 HeadLghtDrvSide_B_Stat 1;
BA_ "U_B479_MY17_Diesel_Rx" SG_ 820 HeadLghtDrvSide_B_Stat 1;
BA_ "U_B479_MY17_Gas_Rx" SG_ 820 HeadLghtDrvSide_B_Stat 1;
BA_ "U_CX482_CX483_MY20_Hev_Tx" SG_ 820 GfhbDistrChng_D_Stat 1;
BA_ "U_CX482_CX483_MY20_Gas_Tx" SG_ 820 GfhbDistrChng_D_Stat 1;
BA_ "U_CX482_CX483_MY20_Diesel_Tx" SG_ 820 GfhbDistrChng_D_Stat 1;
BA_ "U_CX482_CX483_MY20_Hev_Tx" SG_ 820 GfhbShtrRight_An_Actl 1;
BA_ "U_CX482_CX483_MY20_Gas_Tx" SG_ 820 GfhbShtrRight_An_Actl 1;
BA_ "U_CX482_CX483_MY20_Diesel_Tx" SG_ 820 GfhbShtrRight_An_Actl 1;
BA_ "GenSigStartValue" SG_ 820 GfhbShtrRight_An_Actl 1022;
BA_ "U_CX482_CX483_MY20_Hev_Tx" SG_ 820 GfhbShtrLeft_An_Actl 1;
BA_ "U_CX482_CX483_MY20_Gas_Tx" SG_ 820 GfhbShtrLeft_An_Actl 1;
BA_ "U_CX482_CX483_MY20_Diesel_Tx" SG_ 820 GfhbShtrLeft_An_Actl 1;
BA_ "GenSigStartValue" SG_ 820 GfhbShtrLeft_An_Actl 1022;
BA_ "U_CX482_CX483_MY20_Hev_Tx" SG_ 820 GfhbLvlRight_An_Actl 1;
BA_ "U_CX482_CX483_MY20_Gas_Tx" SG_ 820 GfhbLvlRight_An_Actl 1;
BA_ "U_CX482_CX483_MY20_Diesel_Tx" SG_ 820 GfhbLvlRight_An_Actl 1;
BA_ "GenSigStartValue" SG_ 820 GfhbLvlRight_An_Actl 254;
BA_ "U_CX482_CX483_MY20_Hev_Tx" SG_ 820 GfhbLvlLeft_An_Actl 1;
BA_ "U_CX482_CX483_MY20_Gas_Tx" SG_ 820 GfhbLvlLeft_An_Actl 1;
BA_ "U_CX482_CX483_MY20_Diesel_Tx" SG_ 820 GfhbLvlLeft_An_Actl 1;
BA_ "GenSigStartValue" SG_ 820 GfhbLvlLeft_An_Actl 254;
BA_ "U_CX482_CX483_MY20_Hev_Tx" SG_ 820 HeadLghtHiOn_B_StatHcm 1;
BA_ "U_CX482_CX483_MY20_Gas_Tx" SG_ 820 HeadLghtHiOn_B_StatHcm 1;
BA_ "U_CX482_CX483_MY20_Diesel_Tx" SG_ 820 HeadLghtHiOn_B_StatHcm 1;
BA_ "U_U611_U625_MY20_Hev_Tx" SG_ 820 HeadLghtHiOn_B_StatHcm 1;
BA_ "U_U611_U625_MY20_Gas_Tx" SG_ 820 HeadLghtHiOn_B_StatHcm 1;
BA_ "U_U611_U625_MY20_Diesel_Tx" SG_ 820 HeadLghtHiOn_B_StatHcm 1;
BA_ "U_C519_MY18_5_Gas_Tx" SG_ 820 HeadLghtHiOn_B_StatHcm 1;
BA_ "U_C519_MY18_5_Diesel_Tx" SG_ 820 HeadLghtHiOn_B_StatHcm 1;
BA_ "CrossOver_InfoCAN" SG_ 820 HeadLghtHiOn_B_StatHcm 1;
BA_ "U_CX482_CX483_MY20_Hev_Tx" SG_ 820 GfhbLampOnOff_D_Stat 1;
BA_ "U_CX482_CX483_MY20_Gas_Tx" SG_ 820 GfhbLampOnOff_D_Stat 1;
BA_ "U_CX482_CX483_MY20_Diesel_Tx" SG_ 820 GfhbLampOnOff_D_Stat 1;
BA_ "U_CX482_CX483_MY20_Hev_Tx" SG_ 820 GfhbDistrRight_D_Stat 1;
BA_ "U_CX482_CX483_MY20_Gas_Tx" SG_ 820 GfhbDistrRight_D_Stat 1;
BA_ "U_CX482_CX483_MY20_Diesel_Tx" SG_ 820 GfhbDistrRight_D_Stat 1;
BA_ "U_CX482_CX483_MY20_Hev_Tx" SG_ 820 GfhbDistrLeft_D_Stat 1;
BA_ "U_CX482_CX483_MY20_Gas_Tx" SG_ 820 GfhbDistrLeft_D_Stat 1;
BA_ "U_CX482_CX483_MY20_Diesel_Tx" SG_ 820 GfhbDistrLeft_D_Stat 1;
BA_ "U_CX482_CX483_MY20_Hev_Tx" SG_ 820 Adaptive_Hdlmp_Fault 1;
BA_ "U_CX482_CX483_MY20_Gas_Tx" SG_ 820 Adaptive_Hdlmp_Fault 1;
BA_ "U_CX482_CX483_MY20_Diesel_Tx" SG_ 820 Adaptive_Hdlmp_Fault 1;
BA_ "U_U611_U625_MY20_Hev_Tx" SG_ 820 Adaptive_Hdlmp_Fault 1;
BA_ "U_U611_U625_MY20_Gas_Tx" SG_ 820 Adaptive_Hdlmp_Fault 1;
BA_ "U_U611_U625_MY20_Diesel_Tx" SG_ 820 Adaptive_Hdlmp_Fault 1;
BA_ "U_C519_MY18_5_Gas_Tx" SG_ 820 Adaptive_Hdlmp_Fault 1;
BA_ "U_C519_MY18_5_Diesel_Tx" SG_ 820 Adaptive_Hdlmp_Fault 1;
BA_ "U_B479_MY17_Diesel_Rx" SG_ 820 Adaptive_Hdlmp_Fault 1;
BA_ "U_B479_MY17_Gas_Rx" SG_ 820 Adaptive_Hdlmp_Fault 1;
BA_ "CrossOver_InfoCAN" SG_ 820 Adaptive_Hdlmp_Fault 1;
BA_ "U_CX482_CX483_MY20_Hev_Rx" SG_ 935 CtaRightBrkEnbl_B_Rq 1;
BA_ "U_CX482_CX483_MY20_Gas_Rx" SG_ 935 CtaRightBrkEnbl_B_Rq 1;
BA_ "U_CX482_CX483_MY20_Diesel_Rx" SG_ 935 CtaRightBrkEnbl_B_Rq 1;
BA_ "U_C519_MY18_5_Gas_Rx" SG_ 935 CtaRightBrkEnbl_B_Rq 1;
BA_ "U_C519_MY18_5_Diesel_Rx" SG_ 935 CtaRightBrkEnbl_B_Rq 1;
BA_ "GenSigStartValue" SG_ 935 Side_Detect_R_Illum 100;
BA_ "CrossOver_InfoCAN" SG_ 935 Side_Detect_R_Illum 1;
BA_ "CrossOver_InfoCAN" SG_ 935 CtaSnsRight_D_Stat 1;
BA_ "CrossOver_InfoCAN" SG_ 935 CtaAlrtRight_D_Stat 1;
BA_ "CrossOver_InfoCAN" SG_ 935 CtaRight_D_Stat 1;
BA_ "GenSigStartValue" SG_ 935 SodRight_D_Stat 2;
BA_ "CrossOver_InfoCAN" SG_ 935 SodRight_D_Stat 1;
BA_ "CrossOver_InfoCAN" SG_ 935 SodSnsRight_D_Stat 1;
BA_ "CrossOver_InfoCAN" SG_ 935 SodAlrtRight_D_Stat 1;
BA_ "CrossOver_InfoCAN" SG_ 935 SodDetctRight_D_Stat 1;
BA_ "GenSigStartValue" SG_ 935 SodWarnRight_Prd_Rq 14;
BA_ "CrossOver_InfoCAN" SG_ 935 SodWarnRight_Prd_Rq 1;
BA_ "CrossOver_InfoCAN" SG_ 935 SodInnrRight_D_Stat 1;
BA_ "U_CX482_CX483_MY20_Hev_Rx" SG_ 935 CtaRightBrkDecel_B_Rq 1;
BA_ "U_CX482_CX483_MY20_Gas_Rx" SG_ 935 CtaRightBrkDecel_B_Rq 1;
BA_ "U_CX482_CX483_MY20_Diesel_Rx" SG_ 935 CtaRightBrkDecel_B_Rq 1;
BA_ "U_C519_MY18_5_Gas_Rx" SG_ 935 CtaRightBrkDecel_B_Rq 1;
BA_ "U_C519_MY18_5_Diesel_Rx" SG_ 935 CtaRightBrkDecel_B_Rq 1;
BA_ "CrossOver_InfoCAN" SG_ 935 CtaInnrRight_D_Stat 1;
BA_ "U_CX482_CX483_MY20_Hev_Rx" SG_ 934 CtaLeftBrkDecel_B_Rq 1;
BA_ "U_CX482_CX483_MY20_Gas_Rx" SG_ 934 CtaLeftBrkDecel_B_Rq 1;
BA_ "U_CX482_CX483_MY20_Diesel_Rx" SG_ 934 CtaLeftBrkDecel_B_Rq 1;
BA_ "U_C519_MY18_5_Gas_Rx" SG_ 934 CtaLeftBrkDecel_B_Rq 1;
BA_ "U_C519_MY18_5_Diesel_Rx" SG_ 934 CtaLeftBrkDecel_B_Rq 1;
BA_ "U_CX482_CX483_MY20_Hev_Rx" SG_ 934 CtaLeftBrkEnbl_B_Rq 1;
BA_ "U_CX482_CX483_MY20_Gas_Rx" SG_ 934 CtaLeftBrkEnbl_B_Rq 1;
BA_ "U_CX482_CX483_MY20_Diesel_Rx" SG_ 934 CtaLeftBrkEnbl_B_Rq 1;
BA_ "U_C519_MY18_5_Gas_Rx" SG_ 934 CtaLeftBrkEnbl_B_Rq 1;
BA_ "U_C519_MY18_5_Diesel_Rx" SG_ 934 CtaLeftBrkEnbl_B_Rq 1;
BA_ "GenSigStartValue" SG_ 934 Side_Detect_L_Illum 100;
BA_ "CrossOver_InfoCAN" SG_ 934 Side_Detect_L_Illum 1;
BA_ "CrossOver_InfoCAN" SG_ 934 CtaSnsLeft_D_Stat 1;
BA_ "CrossOver_InfoCAN" SG_ 934 SodDetctLeft_D_Stat 1;
BA_ "CrossOver_InfoCAN" SG_ 934 CtaLeft_D_Stat 1;
BA_ "CrossOver_InfoCAN" SG_ 934 CtaAlrtLeft_D_Stat 1;
BA_ "GenSigStartValue" SG_ 934 SodLeft_D_Stat 2;
BA_ "CrossOver_InfoCAN" SG_ 934 SodLeft_D_Stat 1;
BA_ "CrossOver_InfoCAN" SG_ 934 SodSnsLeft_D_Stat 1;
BA_ "CrossOver_InfoCAN" SG_ 934 SodAlrtLeft_D_Stat 1;
BA_ "GenSigStartValue" SG_ 934 SodWarnLeft_Prd_Rq 14;
BA_ "CrossOver_InfoCAN" SG_ 934 SodWarnLeft_Prd_Rq 1;
BA_ "CrossOver_InfoCAN" SG_ 934 SodInnrLeft_D_Stat 1;
BA_ "CrossOver_InfoCAN" SG_ 934 CtaInnrLeft_D_Stat 1;
VAL_ 139 ActvFrontSteMsgTxt_D_Rq 7 "Message7" 6 "Message6" 5 "Message5" 4 "Message4" 3 "Message3" 2 "Message2" 1 "Message1" 0 "NoMessage" ;
VAL_ 139 ActvFrontSteLck_D_Stat 3 "Test_passed" 2 "Test_failed" 1 "Test_cannot_run" 0 "Test_incomplete" ;
VAL_ 139 SelDrvMdeAdptSte_D_Stat 3 "Faulty" 2 "TemporarilyNotAvailable" 1 "Available" 0 "NotAvailable" ;
VAL_ 139 AslButtnOnOffPress2 1 "Button_Pressed" 0 "Button_Not_Pressed" ;
VAL_ 139 AslButtnOnOffCnclPres2 1 "Button_Pressed" 0 "Button_Not_Pressed" ;
VAL_ 139 CcButtnOnPress2 1 "Button_Pressed" 0 "Button_Not_Pressed" ;
VAL_ 139 CcButtnOnOffPress2 1 "Button_Pressed" 0 "Button_Not_Pressed" ;
VAL_ 139 CcButtnOnOffCnclPress2 1 "Button_Pressed" 0 "Button_Not_Pressed" ;
VAL_ 139 CcButtnOffPress2 1 "Button_Pressed" 0 "Button_Not_Pressed" ;
VAL_ 139 CcAsllButtnResPress2 1 "Button_Pressed" 0 "Button_Not_Pressed" ;
VAL_ 139 CcAslButtnSetPress2 1 "Button_Pressed" 0 "Button_Not_Pressed" ;
VAL_ 139 CcAslButtnSetIncPress2 1 "Button_Pressed" 0 "Button_Not_Pressed" ;
VAL_ 139 CcAslButtnSetDecPress2 1 "Button_Pressed" 0 "Button_Not_Pressed" ;
VAL_ 139 CcAslButtnResIncPress2 1 "Button_Pressed" 0 "Button_Not_Pressed" ;
VAL_ 139 CcAslButtnResDecPress2 1 "Button_Pressed" 0 "Button_Not_Pressed" ;
VAL_ 139 CcAslButtnOnPress2 1 "Button_Pressed" 0 "Button_Not_Pressed" ;
VAL_ 139 CcAslButtnOnOffCncl2 1 "Button_Pressed" 0 "Button_Not_Pressed" ;
VAL_ 139 CcAslButtnOffCnclPres2 1 "Button_Pressed" 0 "Button_Not_Pressed" ;
VAL_ 139 CcAslButtnIndxIncPres2 1 "Button_Pressed" 0 "Button_Not_Pressed" ;
VAL_ 139 CcAslButtnIndxDecPres2 1 "Button_Pressed" 0 "Button_Not_Pressed" ;
VAL_ 139 CcAslButtnDeny_B_Actl2 1 "Yes" 0 "No" ;
VAL_ 139 CcAslButtnCnclResPres2 1 "Button_Pressed" 0 "Button_Not_Pressed" ;
VAL_ 139 CcAslButtnCnclPress2 1 "Button_Pressed" 0 "Button_Not_Pressed" ;
VAL_ 139 AccButtnGapIncPress2 1 "Button_Pressed" 0 "Button_Not_Pressed" ;
VAL_ 139 AccButtnGapDecPress2 1 "Button_Pressed" 0 "Button_Not_Pressed" ;
VAL_ 1186 SelDrvMdeAwd2_D_Stat 31 "Faulty" 30 "NotUsed_17" 29 "NotUsed_16" 28 "NotUsed_15" 27 "NotUsed_14" 26 "NotUsed_13" 25 "NotUsed_12" 24 "NotUsed_11" 23 "NotUsed_10" 22 "NotUsed_9" 21 "NotUsed_8" 20 "NotUsed_7" 19 "NotUsed_6" 18 "NotUsed_5" 17 "NotUsed_4" 16 "NotUsed_3" 15 "NotUsed_2" 14 "NotUsed_1" 13 "NotAvailable" 12 "HighSpeedDesertMode_Baja" 11 "SportAdaptiveMode" 10 "RockCrawlMode" 9 "MudRutsMode" 8 "SandMode" 7 "EconomyMode" 6 "GrassGravelSnow" 5 "TowHaulMode" 4 "SportMode" 3 "Normal_4L" 2 "Normal_4A" 1 "Normal_2H" 0 "NormalMode" ;
VAL_ 1186 RearDiffLckMsg_D_Rq 7 "Locker_Disabled" 6 "Locker_Enabled" 5 "Locker_Accel_Pedal" 4 "Speed4" 3 "Speed3" 2 "Spee2" 1 "Speed1" 0 "Normal__No_Message " ;
VAL_ 1186 RearDiffLckLamp_D_Rq 3 "Not_Used" 2 "Flash" 1 "On" 0 "Off" ;
VAL_ 1186 RearDiffLck_Tq_Actl 4095 "Fault" 4094 "Unknown" ;
VAL_ 1186 RearDiffFalt_D_Stat 3 "Diff_Failed_Closed" 2 "Diff_Failed_Open" 1 "Fault_Non_Specific" 0 "No_Fault" ;
VAL_ 1186 LsdSrvcRqd_B_Rq 1 "On" 0 "Off" ;
VAL_ 1042 VehSideSlip_An_Est 511 "Fault" 510 "Unknown" ;
VAL_ 1042 VehRol_An_Dsply 127 "Faulty" 126 "NoDataExists" ;
VAL_ 1042 RearDiffLck_Tq_RqMn 4095 "Faulty" ;
VAL_ 1042 VehPtch_An_Dsply 127 "Faulty" 126 "NoDataExists" ;
VAL_ 138 SteWhlRelCalib_An_Sns 32767 "Fault" 32766 "NoDataExists" ;
VAL_ 1090 TrlrAnOffstDir_D_Calc 3 "NotUSed" 2 "Right" 1 "Left_or_Center" 0 "Null" ;
VAL_ 1090 TrlrAnCalib_Pc_Actl 15 "Faulty" ;
VAL_ 1090 TrlrTrgtAcquire_D_Stat 7 "Faulty" 6 "NotUsed_2" 5 "NotUsed_1" 4 "RVCforTBA_Activated" 3 "Processing" 2 "TargetNotAcquired" 1 "TargetAcquired" 0 "Null" ;
VAL_ 1090 TrlrAid_D_Stat 15 "Faulty" 14 "Trgt_Acqrd_Conf_Unk_w_Par" 13 "TAD_Rq_Denied" 12 "Trgt_Acqrd_Conf_High_w_Par" 11 "Trgt_Acqrd_Conf_Med_w_Par" 10 "Trgt_Acqrd_Conf_Low_w_Par" 9 "Insufficient_Lighting" 8 "No_Video_Input" 7 "Sensor_Blocked" 6 "Target_Cannot_Be_Located" 5 "Invalid_Parameters" 4 "Trgt_Acqrd_Confidence_High" 3 "Trgt_Acqrd_Confidence_Med" 2 "Trgt_Acqrd_Confidence_Low" 1 "Init" 0 "Target_Not_Acquired" ;
VAL_ 1090 TrlrAid_AnRate_Actl 4095 "Faulty" ;
VAL_ 1090 TrlrAid2_An_Actl 4095 "Faulty" ;
VAL_ 73 immoSubTarget1Cmd_T1 7 "Unused3" 6 "Unused2" 5 "ECHO_TARGET1_IDBLOCK2" 4 "Unused1" 3 "RQST_TARGET1_IDBLOCK2" 2 "RQST_TARGET1_IDBLOCK1" 1 "RESPONSE" 0 "IDLE" ;
VAL_ 133 SteWhlOSRelInit2An_Est 65535 "Fault" 65534 "Unknown" ;
VAL_ 133 SteWhlRelCalib_An_Sns 32767 "Fault" 32766 "NoDataExists" ;
VAL_ 133 StePw_B_Rq 1 "Yes" 0 "No" ;
VAL_ 133 SteWhlRelInit2_An_Sns 65535 "Faulty" 65534 "NoDataExists" ;
VAL_ 980 AdbRampingV_D_Rq 3 "Slow" 2 "Medium" 1 "Fast" 0 "Immediately" ;
VAL_ 980 AdbMde1_D_Rq 3 "MarkerLightFlashing" 2 "MarkerLightConstant" 1 "Spot" 0 "None" ;
VAL_ 980 AdbLampOnOff_D_Rq 3 "BothOn" 2 "LeftOnRightOff" 1 "RightOnLeftOff" 0 "BothOff" ;
VAL_ 980 AdbIntns1_D_Rq 3 "Maximum" 2 "Medium" 1 "Low" 0 "Off" ;
VAL_ 980 AdbHiBeamKeepOff_D_Rq 3 "KeepBothOff" 2 "KeepLeftOff" 1 "KeepRightOff" 0 "BothFreeRunning" ;
VAL_ 980 AdbDividedRoad_B_Stat 1 "Yes" 0 "No" ;
VAL_ 980 AdbBrdr1Up_An_Rq 511 "Faulty" 510 "NoDataExists" ;
VAL_ 980 AdbBrdr1Right_An_Rq 2047 "Faulty" 2046 "NoDataExists" ;
VAL_ 980 AdbBrdr1Low_An_Rq 511 "Faulty" 510 "NoDataExists" ;
VAL_ 980 AdbBrdr1Left_An_Rq 2047 "Faulty" 2046 "NoDataExists" ;
VAL_ 1006 PersIndexIpmb_D_Actl 7 "Unused_3" 6 "Unused_2" 5 "Unused_1" 4 "Vehicle" 3 "PERS_4" 2 "PERS_3" 1 "PERS_2" 0 "PERS_1" ;
VAL_ 1200 BrkRearPCorrltn_B_Stat 1 "Yes" 0 "No" ;
VAL_ 1200 HsaTrnAout_Tq_Rq 65535 "Fault" 65534 "Unknown" ;
VAL_ 1200 BrkBstrVac_P_Actl 127 "Invalid" ;
VAL_ 1200 YawStabilityIndex 511 "Fault" 510 "NoDataExists" ;
VAL_ 1200 BrkTot_Tq_RqDrv 8191 "Fault" ;
VAL_ 1200 BrkAutoHold_D_Stat 7 "Faulty" 6 "NotUsed" 5 "Releasing" 4 "HeldSecondary" 3 "HeldSecure" 2 "Held" 1 "Inactive" 0 "Off" ;
VAL_ 1200 HsaStat_D_Dsply 7 "NotUsed3" 6 "NotUsed2" 5 "NotUsed1" 4 "NotAvailable" 3 "SlowReleaseWithChime" 2 "SlowReleaseWithoutChime" 1 "Active" 0 "Inactive" ;
VAL_ 945 KeyOffMde_D_Actl 15 "NotUsed_11" 14 "NotUsed_10" 13 "NotUsed_9" 12 "NotUsed_8" 11 "NotUsed_7" 10 "NotUsed_6" 9 "NotUsed_5" 8 "NotUsed_4" 7 "NotUsed_3" 6 "NotUsed_2" 5 "NotUsed_1" 4 "CriticalBattery" 3 "Hibernate" 2 "Transport" 1 "Factory" 0 "Normal" ;
VAL_ 1102 SelDrvMdePos12_D_Stat 31 "Faulty" 30 "SelDrvMde31" 29 "SelDrvMde30" 28 "SelDrvMde29" 27 "SelDrvMde28" 26 "SelDrvMde27" 25 "SelDrvMde26" 24 "SelDrvMde25" 23 "SelDrvMde24" 22 "SelDrvMde23" 21 "SelDrvMde22" 20 "SelDrvMde21" 19 "SelDrvMde20" 18 "SelDrvMde19" 17 "SelDrvMde18" 16 "SelDrvMde17" 15 "SelDrvMde16" 14 "SelDrvMde15" 13 "SelDrvMde14" 12 "SelDrvMde13" 11 "SelDrvMde12" 10 "SelDrvMde11" 9 "SelDrvMde10" 8 "SelDrvMde09" 7 "SelDrvMde08" 6 "SelDrvMde07" 5 "SelDrvMde06" 4 "SelDrvMde05" 3 "SelDrvMde04" 2 "SelDrvMde03" 1 "SelDrvMde02" 0 "SelDrvMde01" ;
VAL_ 1102 SelDrvMdePos11_D_Stat 31 "Faulty" 30 "SelDrvMde31" 29 "SelDrvMde30" 28 "SelDrvMde29" 27 "SelDrvMde28" 26 "SelDrvMde27" 25 "SelDrvMde26" 24 "SelDrvMde25" 23 "SelDrvMde24" 22 "SelDrvMde23" 21 "SelDrvMde22" 20 "SelDrvMde21" 19 "SelDrvMde20" 18 "SelDrvMde19" 17 "SelDrvMde18" 16 "SelDrvMde17" 15 "SelDrvMde16" 14 "SelDrvMde15" 13 "SelDrvMde14" 12 "SelDrvMde13" 11 "SelDrvMde12" 10 "SelDrvMde11" 9 "SelDrvMde10" 8 "SelDrvMde09" 7 "SelDrvMde08" 6 "SelDrvMde07" 5 "SelDrvMde06" 4 "SelDrvMde05" 3 "SelDrvMde04" 2 "SelDrvMde03" 1 "SelDrvMde02" 0 "SelDrvMde01" ;
VAL_ 1102 SelDrvMdePos10_D_Stat 31 "Faulty" 30 "SelDrvMde31" 29 "SelDrvMde30" 28 "SelDrvMde29" 27 "SelDrvMde28" 26 "SelDrvMde27" 25 "SelDrvMde26" 24 "SelDrvMde25" 23 "SelDrvMde24" 22 "SelDrvMde23" 21 "SelDrvMde22" 20 "SelDrvMde21" 19 "SelDrvMde20" 18 "SelDrvMde19" 17 "SelDrvMde18" 16 "SelDrvMde17" 15 "SelDrvMde16" 14 "SelDrvMde15" 13 "SelDrvMde14" 12 "SelDrvMde13" 11 "SelDrvMde12" 10 "SelDrvMde11" 9 "SelDrvMde10" 8 "SelDrvMde09" 7 "SelDrvMde08" 6 "SelDrvMde07" 5 "SelDrvMde06" 4 "SelDrvMde05" 3 "SelDrvMde04" 2 "SelDrvMde03" 1 "SelDrvMde02" 0 "SelDrvMde01" ;
VAL_ 1102 SelDrvMdePos09_D_Stat 31 "Faulty" 30 "SelDrvMde31" 29 "SelDrvMde30" 28 "SelDrvMde29" 27 "SelDrvMde28" 26 "SelDrvMde27" 25 "SelDrvMde26" 24 "SelDrvMde25" 23 "SelDrvMde24" 22 "SelDrvMde23" 21 "SelDrvMde22" 20 "SelDrvMde21" 19 "SelDrvMde20" 18 "SelDrvMde19" 17 "SelDrvMde18" 16 "SelDrvMde17" 15 "SelDrvMde16" 14 "SelDrvMde15" 13 "SelDrvMde14" 12 "SelDrvMde13" 11 "SelDrvMde12" 10 "SelDrvMde11" 9 "SelDrvMde10" 8 "SelDrvMde09" 7 "SelDrvMde08" 6 "SelDrvMde07" 5 "SelDrvMde06" 4 "SelDrvMde05" 3 "SelDrvMde04" 2 "SelDrvMde03" 1 "SelDrvMde02" 0 "SelDrvMde01" ;
VAL_ 1102 SelDrvMdePos08_D_Stat 31 "Faulty" 30 "SelDrvMde31" 29 "SelDrvMde30" 28 "SelDrvMde29" 27 "SelDrvMde28" 26 "SelDrvMde27" 25 "SelDrvMde26" 24 "SelDrvMde25" 23 "SelDrvMde24" 22 "SelDrvMde23" 21 "SelDrvMde22" 20 "SelDrvMde21" 19 "SelDrvMde20" 18 "SelDrvMde19" 17 "SelDrvMde18" 16 "SelDrvMde17" 15 "SelDrvMde16" 14 "SelDrvMde15" 13 "SelDrvMde14" 12 "SelDrvMde13" 11 "SelDrvMde12" 10 "SelDrvMde11" 9 "SelDrvMde10" 8 "SelDrvMde09" 7 "SelDrvMde08" 6 "SelDrvMde07" 5 "SelDrvMde06" 4 "SelDrvMde05" 3 "SelDrvMde04" 2 "SelDrvMde03" 1 "SelDrvMde02" 0 "SelDrvMde01" ;
VAL_ 1102 SelDrvMdePos07_D_Stat 31 "Faulty" 30 "SelDrvMde31" 29 "SelDrvMde30" 28 "SelDrvMde29" 27 "SelDrvMde28" 26 "SelDrvMde27" 25 "SelDrvMde26" 24 "SelDrvMde25" 23 "SelDrvMde24" 22 "SelDrvMde23" 21 "SelDrvMde22" 20 "SelDrvMde21" 19 "SelDrvMde20" 18 "SelDrvMde19" 17 "SelDrvMde18" 16 "SelDrvMde17" 15 "SelDrvMde16" 14 "SelDrvMde15" 13 "SelDrvMde14" 12 "SelDrvMde13" 11 "SelDrvMde12" 10 "SelDrvMde11" 9 "SelDrvMde10" 8 "SelDrvMde09" 7 "SelDrvMde08" 6 "SelDrvMde07" 5 "SelDrvMde06" 4 "SelDrvMde05" 3 "SelDrvMde04" 2 "SelDrvMde03" 1 "SelDrvMde02" 0 "SelDrvMde01" ;
VAL_ 1102 SelDrvMdePos06_D_Stat 31 "Faulty" 30 "SelDrvMde31" 29 "SelDrvMde30" 28 "SelDrvMde29" 27 "SelDrvMde28" 26 "SelDrvMde27" 25 "SelDrvMde26" 24 "SelDrvMde25" 23 "SelDrvMde24" 22 "SelDrvMde23" 21 "SelDrvMde22" 20 "SelDrvMde21" 19 "SelDrvMde20" 18 "SelDrvMde19" 17 "SelDrvMde18" 16 "SelDrvMde17" 15 "SelDrvMde16" 14 "SelDrvMde15" 13 "SelDrvMde14" 12 "SelDrvMde13" 11 "SelDrvMde12" 10 "SelDrvMde11" 9 "SelDrvMde10" 8 "SelDrvMde09" 7 "SelDrvMde08" 6 "SelDrvMde07" 5 "SelDrvMde06" 4 "SelDrvMde05" 3 "SelDrvMde04" 2 "SelDrvMde03" 1 "SelDrvMde02" 0 "SelDrvMde01" ;
VAL_ 1102 SelDrvMdePos05_D_Stat 31 "Faulty" 30 "SelDrvMde31" 29 "SelDrvMde30" 28 "SelDrvMde29" 27 "SelDrvMde28" 26 "SelDrvMde27" 25 "SelDrvMde26" 24 "SelDrvMde25" 23 "SelDrvMde24" 22 "SelDrvMde23" 21 "SelDrvMde22" 20 "SelDrvMde21" 19 "SelDrvMde20" 18 "SelDrvMde19" 17 "SelDrvMde18" 16 "SelDrvMde17" 15 "SelDrvMde16" 14 "SelDrvMde15" 13 "SelDrvMde14" 12 "SelDrvMde13" 11 "SelDrvMde12" 10 "SelDrvMde11" 9 "SelDrvMde10" 8 "SelDrvMde09" 7 "SelDrvMde08" 6 "SelDrvMde07" 5 "SelDrvMde06" 4 "SelDrvMde05" 3 "SelDrvMde04" 2 "SelDrvMde03" 1 "SelDrvMde02" 0 "SelDrvMde01" ;
VAL_ 1102 SelDrvMdePos04_D_Stat 31 "Faulty" 30 "SelDrvMde31" 29 "SelDrvMde30" 28 "SelDrvMde29" 27 "SelDrvMde28" 26 "SelDrvMde27" 25 "SelDrvMde26" 24 "SelDrvMde25" 23 "SelDrvMde24" 22 "SelDrvMde23" 21 "SelDrvMde22" 20 "SelDrvMde21" 19 "SelDrvMde20" 18 "SelDrvMde19" 17 "SelDrvMde18" 16 "SelDrvMde17" 15 "SelDrvMde16" 14 "SelDrvMde15" 13 "SelDrvMde14" 12 "SelDrvMde13" 11 "SelDrvMde12" 10 "SelDrvMde11" 9 "SelDrvMde10" 8 "SelDrvMde09" 7 "SelDrvMde08" 6 "SelDrvMde07" 5 "SelDrvMde06" 4 "SelDrvMde05" 3 "SelDrvMde04" 2 "SelDrvMde03" 1 "SelDrvMde02" 0 "SelDrvMde01" ;
VAL_ 1102 SelDrvMdePos03_D_Stat 31 "Faulty" 30 "SelDrvMde31" 29 "SelDrvMde30" 28 "SelDrvMde29" 27 "SelDrvMde28" 26 "SelDrvMde27" 25 "SelDrvMde26" 24 "SelDrvMde25" 23 "SelDrvMde24" 22 "SelDrvMde23" 21 "SelDrvMde22" 20 "SelDrvMde21" 19 "SelDrvMde20" 18 "SelDrvMde19" 17 "SelDrvMde18" 16 "SelDrvMde17" 15 "SelDrvMde16" 14 "SelDrvMde15" 13 "SelDrvMde14" 12 "SelDrvMde13" 11 "SelDrvMde12" 10 "SelDrvMde11" 9 "SelDrvMde10" 8 "SelDrvMde09" 7 "SelDrvMde08" 6 "SelDrvMde07" 5 "SelDrvMde06" 4 "SelDrvMde05" 3 "SelDrvMde04" 2 "SelDrvMde03" 1 "SelDrvMde02" 0 "SelDrvMde01" ;
VAL_ 1102 SelDrvMdePos02_D_Stat 31 "Faulty" 30 "SelDrvMde31" 29 "SelDrvMde30" 28 "SelDrvMde29" 27 "SelDrvMde28" 26 "SelDrvMde27" 25 "SelDrvMde26" 24 "SelDrvMde25" 23 "SelDrvMde24" 22 "SelDrvMde23" 21 "SelDrvMde22" 20 "SelDrvMde21" 19 "SelDrvMde20" 18 "SelDrvMde19" 17 "SelDrvMde18" 16 "SelDrvMde17" 15 "SelDrvMde16" 14 "SelDrvMde15" 13 "SelDrvMde14" 12 "SelDrvMde13" 11 "SelDrvMde12" 10 "SelDrvMde11" 9 "SelDrvMde10" 8 "SelDrvMde09" 7 "SelDrvMde08" 6 "SelDrvMde07" 5 "SelDrvMde06" 4 "SelDrvMde05" 3 "SelDrvMde04" 2 "SelDrvMde03" 1 "SelDrvMde02" 0 "SelDrvMde01" ;
VAL_ 1102 SelDrvMdePos01_D_Stat 31 "Faulty" 30 "SelDrvMde31" 29 "SelDrvMde30" 28 "SelDrvMde29" 27 "SelDrvMde28" 26 "SelDrvMde27" 25 "SelDrvMde26" 24 "SelDrvMde25" 23 "SelDrvMde24" 22 "SelDrvMde23" 21 "SelDrvMde22" 20 "SelDrvMde21" 19 "SelDrvMde20" 18 "SelDrvMde19" 17 "SelDrvMde18" 16 "SelDrvMde17" 15 "SelDrvMde16" 14 "SelDrvMde15" 13 "SelDrvMde14" 12 "SelDrvMde13" 11 "SelDrvMde12" 10 "SelDrvMde11" 9 "SelDrvMde10" 8 "SelDrvMde09" 7 "SelDrvMde08" 6 "SelDrvMde07" 5 "SelDrvMde06" 4 "SelDrvMde05" 3 "SelDrvMde04" 2 "SelDrvMde03" 1 "SelDrvMde02" 0 "SelDrvMde01" ;
VAL_ 962 AdbMde3_D_Rq 3 "MarkerLightFlashing" 2 "MarkerLightConstant" 1 "Spot" 0 "None" ;
VAL_ 962 AdbIntns3_D_Rq 3 "Maximum" 2 "Medium" 1 "Low" 0 "Off" ;
VAL_ 962 AdbBrdr3Up_An_Rq 511 "Faulty" 510 "NoDataExists" ;
VAL_ 962 AdbBrdr3Right_An_Rq 2047 "Faulty" 2046 "NoDataExists" ;
VAL_ 962 AdbBrdr3Low_An_Rq 511 "Faulty" 510 "NoDataExists" ;
VAL_ 962 AdbBrdr3Left_An_Rq 2047 "Faulty" 2046 "NoDataExists" ;
VAL_ 961 AdbMde2_D_Rq 3 "MarkerLightFlashing" 2 "MarkerLightConstant" 1 "Spot" 0 "None" ;
VAL_ 961 AdbIntns2_D_Rq 3 "Maximum" 2 "Medium" 1 "Low" 0 "Off" ;
VAL_ 961 AdbBrdr2Up_An_Rq 511 "Faulty" 510 "NoDataExists" ;
VAL_ 961 AdbBrdr2Right_An_Rq 2047 "Faulty" 2046 "NoDataExists" ;
VAL_ 961 AdbBrdr2Low_An_Rq 511 "Faulty" 510 "NoDataExists" ;
VAL_ 961 AdbBrdr2Left_An_Rq 2047 "Faulty" 2046 "NoDataExists" ;
VAL_ 1122 GpsHsphLongEast_D_Actl 0 "Invalid" 1 "Eastern" 2 "Western" 3 "Fault" ;
VAL_ 1122 GpsHsphLattSth_D_Actl 3 "Fault" 2 "Northern" 1 "Southern" 0 "Invalid" ;
VAL_ 1122 GPS_Longitude_Minutes 63 "Fault" 62 "Unknown" ;
VAL_ 1122 GPS_Longitude_Min_dec 16383 "Invalid" 16382 "Unknown" ;
VAL_ 1122 GPS_Longitude_Degrees 511 "Fault" 510 "Unknown" ;
VAL_ 1122 GPS_Latitude_Minutes 63 "Fault" 62 "Unknown" ;
VAL_ 1122 GPS_Latitude_Min_dec 16383 "Invalid" 16382 "Unknown" ;
VAL_ 1122 GPS_Latitude_Degrees 255 "Invalid" 254 "Unknown" ;
VAL_ 1080 AutoTowActv_B_Stat_UB 1 "Fresh_data" 0 "Unchanged_data" ;
VAL_ 1080 AutoTowActv_B_Stat 1 "Yes" 0 "No" ;
VAL_ 1080 DrLatchLckRr_B_Stat_UB 1 "Fresh_data" 0 "Unchanged_data" ;
VAL_ 1080 DrLatchLckRl_B_Stat_UB 1 "Fresh_data" 0 "Unchanged_data" ;
VAL_ 1080 DrLatchLckFr_B_Stat_UB 1 "Fresh_data" 0 "Unchanged_data" ;
VAL_ 1080 DrLatchLckFl_B_Stat_UB 1 "Fresh_data" 0 "Unchanged_data" ;
VAL_ 1080 DrLatchRr_B_Falt_UB 1 "Fresh_data" 0 "Unchanged_data" ;
VAL_ 1080 DrLatchRl_B_Falt_UB 1 "Fresh_data" 0 "Unchanged_data" ;
VAL_ 1080 DrLatchFr_B_Falt_UB 1 "Fresh_data" 0 "Unchanged_data" ;
VAL_ 1080 DrLatchFl_B_Falt_UB 1 "Fresh_data" 0 "Unchanged_data" ;
VAL_ 1080 DrLatchCntRr_No_Actl_UB 1 "Fresh_data" 0 "Unchanged_data" ;
VAL_ 1080 DrLatchCntRl_No_Actl_UB 1 "Fresh_data" 0 "Unchanged_data" ;
VAL_ 1080 DrLatchCntFr_No_Actl_UB 1 "Fresh_data" 0 "Unchanged_data" ;
VAL_ 1080 DrLatchCntFl_No_Actl_UB 1 "Fresh_data" 0 "Unchanged_data" ;
VAL_ 1080 DrLatchRr_B_Falt 1 "Yes" 0 "No" ;
VAL_ 1080 DrLatchRl_B_Falt 1 "Yes" 0 "No" ;
VAL_ 1080 DrLatchLckRr_B_Stat 1 "Locked" 0 "Unlock" ;
VAL_ 1080 DrLatchLckRl_B_Stat 1 "Locked" 0 "Unlock" ;
VAL_ 1080 DrLatchLckFr_B_Stat 1 "Locked" 0 "Unlock" ;
VAL_ 1080 DrLatchLckFl_B_Stat 1 "Locked" 0 "Unlock" ;
VAL_ 1080 DrLatchFr_B_Falt 1 "Yes" 0 "No" ;
VAL_ 1080 DrLatchFl_B_Falt 1 "Yes" 0 "No" ;
VAL_ 1080 TurnLghtSwtch_D_Stat2_UB 1 "Fresh_data" 0 "Unchanged_data" ;
VAL_ 1080 TurnLghtSwtch_D_Stat2 3 "NotUsed" 2 "Right" 1 "Left" 0 "Off" ;
VAL_ 1080 CabnAmb_Te_Actl_UB 1 "Fresh_data" 0 "Unchanged_data" ;
VAL_ 1080 CabnAmb_Te_Actl 255 "Fault" ;
VAL_ 1080 HeadLghtHiPrmsn_D_Stat_UB 1 "Fresh_data" 0 "Unchanged_data" ;
VAL_ 1080 HeadLghtHiPrmsn_D_Stat 3 "CancelAndSuppress" 2 "Cancel" 1 "Hold" 0 "AllowChange" ;
VAL_ 1121 AutoHoldSwtch_D_Stat2 3 "Faulty" 2 "NotUsed" 1 "Pressed" 0 "Not_Pressed" ;
VAL_ 1121 PrkAidSwtch_D_RqDrv3 1 "Pressed" 0 "Not_Pressed" ;
VAL_ 1121 ApaSwtch_D_RqDrv3 3 "NotUsed2" 2 "NotUsed1" 1 "Pressed" 0 "Not_Pressed" ;
VAL_ 1121 StopStrtDrvMde_B_RqBtn2 1 "Pressed" 0 "Not_Pressed" ;
VAL_ 1121 SelDrvMdeSwtch_D_Stat 3 "Faulty" 2 "SwitchState2" 1 "SwitchState1" 0 "NotPressed" ;
VAL_ 1121 SelDrvMdeCnt_D_Stat 4 "FourCounts" 3 "ThreeCounts" 2 "TwoCounts" 1 "OneCount" 0 "ZeroCounts" 7 "SevenOrMoreCounts" 6 "SixCounts" 5 "FiveCounts" ;
VAL_ 517 TrnAinLss_Tq_Est_UB 1 "Fresh_data" 0 "Unchanged_data" ;
VAL_ 517 TrnAinLss_Tq_Est 2047 "Fault" 2046 "Unknown" ;
VAL_ 517 BrkTot_Tq_RqFapLc_UB 1 "Fresh_data" 0 "Unchanged_data" ;
VAL_ 979 HandsOffCnfm_B_Rq 1 "Active" 0 "Inactive" ;
VAL_ 979 LatCtl_D_Rq 7 "NotUsed4" 6 "NotUsed3" 5 "NotUsed2" 4 "NotUsed1" 3 "InterventionRight" 2 "InterventionLeft" 1 "ContinuousPathFollowing" 0 "NoLateralControl" ;
VAL_ 979 LatCtlRampType_D_Rq 3 "Immediately" 2 "Fast" 1 "Medium" 0 "Slow" ;
VAL_ 979 LatCtlPrecision_D_Rq 3 "NotUsed2" 2 "NotUsed1" 1 "Precise" 0 "Comfortable" ;
VAL_ 1056 SelDrvMdePos12_B_Avail 1 "Available" 0 "NotAvailable" ;
VAL_ 1056 SelDrvMdePos11_B_Avail 1 "Available" 0 "NotAvailable" ;
VAL_ 1056 SelDrvMdePos10_B_Avail 1 "Available" 0 "NotAvailable" ;
VAL_ 1056 SelDrvMdePos09_B_Avail 1 "Available" 0 "NotAvailable" ;
VAL_ 1056 SelDrvMdePos08_B_Avail 1 "Available" 0 "NotAvailable" ;
VAL_ 1056 SelDrvMdePos07_B_Avail 1 "Available" 0 "NotAvailable" ;
VAL_ 1056 SelDrvMdePos06_B_Avail 1 "Available" 0 "NotAvailable" ;
VAL_ 1056 SelDrvMdePos05_B_Avail 1 "Available" 0 "NotAvailable" ;
VAL_ 1056 SelDrvMdePos04_B_Avail 1 "Available" 0 "NotAvailable" ;
VAL_ 1056 SelDrvMdePos03_B_Avail 1 "Available" 0 "NotAvailable" ;
VAL_ 1056 SelDrvMdePos02_B_Avail 1 "Available" 0 "NotAvailable" ;
VAL_ 1056 SelDrvMdePos01_B_Avail 1 "Available" 0 "NotAvailable" ;
VAL_ 1056 ActvDrvMde_D2_Stat 31 "Faulty" 30 "SelDrvMde31" 29 "SelDrvMde30" 28 "SelDrvMde29" 27 "SelDrvMde28" 26 "SelDrvMde27" 25 "SelDrvMde26" 24 "SelDrvMde25" 23 "SelDrvMde24" 22 "SelDrvMde23" 21 "SelDrvMde22" 20 "SelDrvMde21" 19 "SelDrvMde20" 18 "SelDrvMde19" 17 "SelDrvMde18" 16 "SelDrvMde17" 15 "SelDrvMde16" 14 "SelDrvMde15" 13 "SelDrvMde14" 12 "SelDrvMde13" 11 "SelDrvMde12" 10 "SelDrvMde11" 9 "SelDrvMde10" 8 "SelDrvMde09" 7 "SelDrvMde08" 6 "SelDrvMde07" 5 "SelDrvMde06" 4 "SelDrvMde05" 3 "SelDrvMde04" 2 "SelDrvMde03" 1 "SelDrvMde02" 0 "SelDrvMde01" ;
VAL_ 1056 SelDrvMde_D2_Rq 31 "Faulty" 30 "SelDrvMde31" 29 "SelDrvMde30" 28 "SelDrvMde29" 27 "SelDrvMde28" 26 "SelDrvMde27" 25 "SelDrvMde26" 24 "SelDrvMde25" 23 "SelDrvMde24" 22 "SelDrvMde23" 21 "SelDrvMde22" 20 "SelDrvMde21" 19 "SelDrvMde20" 18 "SelDrvMde19" 17 "SelDrvMde18" 16 "SelDrvMde17" 15 "SelDrvMde16" 14 "SelDrvMde15" 13 "SelDrvMde14" 12 "SelDrvMde13" 11 "SelDrvMde12" 10 "SelDrvMde11" 9 "SelDrvMde10" 8 "SelDrvMde09" 7 "SelDrvMde08" 6 "SelDrvMde07" 5 "SelDrvMde06" 4 "SelDrvMde05" 3 "SelDrvMde04" 2 "SelDrvMde03" 1 "SelDrvMde02" 0 "SelDrvMde01" ;
VAL_ 1056 ActvDrvMde_D_Stat 15 "SelDrvMde16" 14 "SelDrvMde15" 13 "SelDrvMde14" 12 "SelDrvMde13" 11 "SelDrvMde12" 10 "SelDrvMde11" 9 "SelDrvMde10" 8 "SelDrvMde09" 7 "SelDrvMde08" 6 "SelDrvMde07" 5 "SelDrvMde06" 4 "SelDrvMde05" 3 "SelDrvMde04" 2 "SelDrvMde03" 1 "SelDrvMde02" 0 "SelDrvMde01" ;
VAL_ 1056 SelDrvMdePt_D_Rq 31 "NotUsed16" 30 "NotUsed15" 29 "NotUsed14" 28 "NotUsed13" 27 "NotUsed12" 26 "NotUsed11" 25 "NotUsed10" 24 "NotUsed9" 23 "NotUsed8" 22 "NotUsed7" 21 "NotUsed6" 20 "NotUsed5" 19 "NotUsed4" 18 "NotUsed3" 17 "NotUsed2" 16 "NotUsed1" 15 "HighSpeedDesertMode_Baja" 14 "SportAdaptiveMode" 13 "NotAvailable_13" 12 "NotAvailable_12" 11 "NotAvailable_11" 10 "NotAvailable_10" 9 "RockCrawlMode" 8 "MudRutsMode" 7 "SandMode" 6 "EconomyMode" 5 "GrassGravelSnow" 4 "NotAvailable_04" 3 "TowHaulMode" 2 "NotAvailable_02" 1 "SportMode" 0 "NormalMode" ;
VAL_ 1056 SelDrvMdeMsgTxt_D_Rq 15 "Message15" 14 "Message14" 13 "Message13" 12 "Message12" 11 "Message11" 10 "Message10" 9 "Message9" 8 "Message8" 7 "Message7" 6 "Message6" 5 "Message5" 4 "Message4" 3 "Message3" 2 "Message2" 1 "Message1" 0 "NoMessage" ;
VAL_ 1056 SelDrvMde_D_Stat 3 "NotUsed" 2 "DriveModeChangeRequest" 1 "DriveModeChangeSelection" 0 "NoDriveModeChangeRequest" ;
VAL_ 1056 SelDrvMde_D_Rq 15 "SelDrvMde16" 14 "SelDrvMde15" 13 "SelDrvMde14" 12 "SelDrvMde13" 11 "SelDrvMde12" 10 "SelDrvMde11" 9 "SelDrvMde10" 8 "SelDrvMde09" 7 "SelDrvMde08" 6 "SelDrvMde07" 5 "SelDrvMde06" 4 "SelDrvMde05" 3 "SelDrvMde04" 2 "SelDrvMde03" 1 "SelDrvMde02" 0 "SelDrvMde01" ;
VAL_ 1056 SelDrvMde16_B_Avail 1 "Available" 0 "NotAvailable" ;
VAL_ 1056 SelDrvMde15_B_Avail 1 "Available" 0 "NotAvailable" ;
VAL_ 1056 SelDrvMde14_B_Avail 1 "Available" 0 "NotAvailable" ;
VAL_ 1056 SelDrvMde13_B_Avail 1 "Available" 0 "NotAvailable" ;
VAL_ 1056 SelDrvMde12_B_Avail 1 "Available" 0 "NotAvailable" ;
VAL_ 1056 SelDrvMde11_B_Avail 1 "Available" 0 "NotAvailable" ;
VAL_ 1056 SelDrvMde10_B_Avail 1 "Available" 0 "NotAvailable" ;
VAL_ 1056 SelDrvMde09_B_Avail 1 "Available" 0 "NotAvailable" ;
VAL_ 1056 SelDrvMde08_B_Avail 1 "Available" 0 "NotAvailable" ;
VAL_ 1056 SelDrvMde07_B_Avail 1 "Available" 0 "NotAvailable" ;
VAL_ 1056 SelDrvMde06_B_Avail 1 "Available" 0 "NotAvailable" ;
VAL_ 1056 SelDrvMde05_B_Avail 1 "Available" 0 "NotAvailable" ;
VAL_ 1056 SelDrvMde04_B_Avail 1 "Available" 0 "NotAvailable" ;
VAL_ 1056 SelDrvMde03_B_Avail 1 "Available" 0 "NotAvailable" ;
VAL_ 1056 SelDrvMde02_B_Avail 1 "Available" 0 "NotAvailable" ;
VAL_ 1056 SelDrvMde01_B_Avail 1 "Available" 0 "NotAvailable" ;
VAL_ 1056 AwdMde_D_RqBrk 7 "Faulty" 6 "NotUsed2" 5 "NoRequest" 4 "Neutral" 3 "FourByFourLow" 2 "FourByFourHigh" 1 "FourByFourAuto" 0 "FourByTwo" ;
VAL_ 673 ICI_Coding_BtnID_D 15 "Idle" 5 "Stuck" 4 "LongEvent" 3 "ShortElapsed" 2 "ShortEvent" 1 "Active" 0 "Inactive" ;
VAL_ 673 ICI_Coding_BtnID_C 15 "Idle" 5 "Stuck" 4 "LongEvent" 3 "ShortElapsed" 2 "ShortEvent" 1 "Active" 0 "Inactive" ;
VAL_ 673 ICI_Coding_BtnID_B 15 "Idle" 5 "Stuck" 4 "LongEvent" 3 "ShortElapsed" 2 "ShortEvent" 1 "Active" 0 "Inactive" ;
VAL_ 673 ICI_Coding_BtnID_A 15 "Idle" 5 "Stuck" 4 "LongEvent" 3 "ShortElapsed" 2 "ShortEvent" 1 "Active" 0 "Inactive" ;
VAL_ 845 StmsLmbrPsgr_D_Stat 3 "High" 2 "Low" 1 "Off" 0 "Null" ;
VAL_ 845 StmsCshnPsgr_D_Stat 3 "High" 2 "Low" 1 "Off" 0 "Null" ;
VAL_ 845 SeatSwtchPsgr_B_Stat 1 "On" 0 "Off" ;
VAL_ 845 SeatPPsgr_B_Stat 1 "Updating" 0 "NotUpdating" ;
VAL_ 845 SeatFnPsgr_D_Stat 7 "CushionMassage" 6 "LumbarMassage" 5 "UpperBolster" 4 "LowerBolster" 3 "UpperLumbar" 2 "MiddleLumbar" 1 "LowerLumbar" 0 "Null" ;
VAL_ 845 PsgrMemFeedback_Rsp 8 "Recall_4" 7 "Recall_3" 6 "Recall_2" 5 "Recall_1" 4 "Store_4" 3 "Store_3" 2 "Store_2" 1 "Store_1" 0 "Inactive" ;
VAL_ 850 SeatCshnPsgrRR_Pc_Actl 127 "Null" ;
VAL_ 850 SeatCshnPsgrRL_Pc_Actl 127 "Null" ;
VAL_ 850 SeatCshnPsgrFR_Pc_Actl 127 "Null" ;
VAL_ 850 SeatCshnPsgrFL_Pc_Actl 127 "Null" ;
VAL_ 850 SeatBlLoPsgr_Pc_Actl2 127 "Null" ;
VAL_ 820 AhbStatGfhbFdbk_D_Actl 3 "GfhbHighBeamFullyOn" 2 "GfhbHighBeamPartlyOn" 1 "GfhbHighBeamOff" 0 "GfhbUnavailable" ;
VAL_ 820 HeadLghtDrvSide_B_Stat 1 "Left_Hand_Traffic" 0 "Right_Hand_Traffic" ;
VAL_ 820 GfhbDistrChng_D_Stat 3 "Both_in_Transition" 2 "Left_in_Transition" 1 "Right_in_Transition" 0 "Both_Static" ;
VAL_ 820 GfhbShtrRight_An_Actl 1023 "Faulty" 1022 "NoDataExists" ;
VAL_ 820 GfhbShtrLeft_An_Actl 1023 "Faulty" 1022 "NoDataExists" ;
VAL_ 820 GfhbLvlRight_An_Actl 255 "Faulty" 254 "NoDataExists" ;
VAL_ 820 GfhbLvlLeft_An_Actl 255 "Faulty" 254 "NoDataExists" ;
VAL_ 820 HeadLghtHiOn_B_StatHcm 1 "On" 0 "Off" ;
VAL_ 820 GfhbLampOnOff_D_Stat 3 "Both_On" 2 "Left_On_Right_Off" 1 "Right_On_Left_Off" 0 "Both_Off" ;
VAL_ 820 GfhbDistrRight_D_Stat 7 "High_Beam_Classis" 6 "High_Beam_GFHB" 5 "GFHB_with_Vert_Adjustment" 4 "GFHB_with_Spot" 3 "Motorway" 2 "Low_Beam_GFHB" 1 "Low_Beam_Classic" 0 "Symmetric" ;
VAL_ 820 GfhbDistrLeft_D_Stat 7 "High_Beam_Classis" 6 "High_Beam_GFHB" 5 "GFHB_with_Vert_Adjustment" 4 "GFHB_with_Spot" 3 "Motorway" 2 "Low_Beam_GFHB" 1 "Low_Beam_Classic" 0 "Symmetric" ;
VAL_ 820 Adaptive_Hdlmp_Fault 1 "Yes" 0 "No" ;
VAL_ 935 CtaAlrtRight2_D_Stat 7 "NotUsed3" 6 "NotUsed2" 5 "NotUsed1" 4 "AlertZone4" 3 "AlertZone3" 2 "AlertZone2" 1 "AlertZone1" 0 "Off" ;
VAL_ 935 BttRight_D_Stat 7 "NotUsed" 6 "Disabled" 5 "Off" 4 "OffTemp" 3 "NotConnected" 2 "Pending" 1 "Connected" 0 "NotDetermined" ;
VAL_ 935 BttRight_D_RqDrv 3 "NotUsed" 2 "Request" 1 "NoRequest" 0 "Null" ;
VAL_ 935 CtaBrkRightMsgTxt_B_Rq 1 "Enable" 0 "Disable" ;
VAL_ 935 CtaRightBrkEnbl_B_Rq 1 "Enable" 0 "Disable" ;
VAL_ 935 CtaSnsRight_D_Stat 3 "Invalid" 2 "System_Failure" 1 "Blocked" 0 "Clear" ;
VAL_ 935 CtaAlrtRight_D_Stat 1 "On" 0 "Off" ;
VAL_ 935 CtaRight_D_Stat 4 "Invalid" 3 "Disabled" 2 "On" 1 "Trailer_Tow_Off" 0 "Off" ;
VAL_ 935 SodRight_D_Stat 4 "Invalid" 3 "Disabled" 2 "On" 1 "Trailer_Tow_Off" 0 "Off" ;
VAL_ 935 SodSnsRight_D_Stat 3 "Second_Warning_Audio" 2 "System_Failure" 1 "Blocked" 0 "Clear" ;
VAL_ 935 SodAlrtRight_D_Stat 3 "Bulb_Proveout" 2 "Flash" 1 "On" 0 "Off" ;
VAL_ 935 SodDetctRight_D_Stat 4 "Sensor_Blocked" 3 "Sensor_Fault" 2 "Flash_On" 1 "Alert_On" 0 "AlertOff_FlashOff_SensrClr" ;
VAL_ 935 SodInnrRight_D_Stat 3 "Reporting" 2 "Not_Reporting" 1 "System_Standby" 0 "Initialization" ;
VAL_ 935 CtaRightBrkDecel_B_Rq 1 "Enable" 0 "Disable" ;
VAL_ 935 CtaInnrRight_D_Stat 3 "Reporting" 2 "Not_Reporting" 1 "System_Standby" 0 "Initialization" ;
VAL_ 934 CtaAlrtLeft2_D_Stat 7 "NotUsed3" 6 "NotUsed2" 5 "NotUsed1" 4 "AlertZone4" 3 "AlertZone3" 2 "AlertZone2" 1 "AlertZone1" 0 "Off" ;
VAL_ 934 BttLeft_D_Stat 7 "NotUsed" 6 "Disabled" 5 "Off" 4 "OffTemp" 3 "NotConnected" 2 "Pending" 1 "Connected" 0 "NotDetermined" ;
VAL_ 934 BttLeft_D_RqDrv 3 "NotUsed" 2 "Request" 1 "NoRequest" 0 "Null" ;
VAL_ 934 CtaBrkLeftMsgTxt_B_Rq 1 "Enable" 0 "Disable" ;
VAL_ 934 CtaLeftBrkDecel_B_Rq 1 "Enable" 0 "Disable" ;
VAL_ 934 CtaLeftBrkEnbl_B_Rq 1 "Enable" 0 "Disable" ;
VAL_ 934 CtaSnsLeft_D_Stat 3 "Invalid" 2 "System_Failure" 1 "Blocked" 0 "Clear" ;
VAL_ 934 SodDetctLeft_D_Stat 4 "Sensor_Blocked" 3 "Sensor_Fault" 2 "Flash_On" 1 "Alert_On" 0 "AlertOff_FlashOff_SensrClr" ;
VAL_ 934 CtaLeft_D_Stat 4 "Invalid" 3 "Disabled" 2 "On" 1 "Trailer_Tow_Off" 0 "Off" ;
VAL_ 934 CtaAlrtLeft_D_Stat 1 "On" 0 "Off" ;
VAL_ 934 SodLeft_D_Stat 4 "Invalid" 3 "Disabled" 2 "On" 1 "Trailer_Tow_Off" 0 "Off" ;
VAL_ 934 SodSnsLeft_D_Stat 3 "Second_Warning_Audio" 2 "System_Failure" 1 "Blocked" 0 "Clear" ;
VAL_ 934 SodAlrtLeft_D_Stat 3 "Bulb_Proveout" 2 "Flash" 1 "On" 0 "Off" ;
VAL_ 934 SodInnrLeft_D_Stat 3 "Reporting" 2 "Not_Reporting" 1 "System_Standby" 0 "Initialization" ;
VAL_ 934 CtaInnrLeft_D_Stat 3 "Reporting" 2 "Not_Reporting" 1 "System_Standby" 0 "Initialization" ;
